VERSION ""

NS_ :

BS_:

BU_:

BO_ 2633663742 HVESP11HIST: 19 Vector__XXX
 SG_ Hvesp11StateOfHealth : 0|8@1+ (0.4,0) [0|100] "%" Vector__XXX
 SG_ Hvsp11CnttrOpnUndrLdCnt : 8|16@1+ (1,0) [0|64255] "count" Vector__XXX
 SG_ Hvesp11TotalEnergyThroughput : 24|32@1+ (100,0) [0|421108121500] "Watt-hour" Vector__XXX
 SG_ Hvesp11TotalAccumulatedCharge : 56|32@1+ (100,0) [0|421108121500] "Ah" Vector__XXX
 SG_ Hvesp11TotalLifetimeEnergyInput : 88|32@1+ (1,0) [0|4211081215] "kWh" Vector__XXX
 SG_ Hvsp11TtlLftmEnrgOtpt : 120|32@1+ (1,0) [0|4211081215] "kWh" Vector__XXX

BO_ 2566555134 HVESP11CFG: 19 Vector__XXX
 SG_ Hvesp11NominalVoltage : 0|16@1+ (0.05,0) [0|3212.75] "V" Vector__XXX
 SG_ Hvsp11RmmnddMnmmOprtngVltg : 16|16@1+ (0.05,0) [0|3212.75] "V" Vector__XXX
 SG_ Hvsp11RmmnddMxmmOprtngVltg : 32|16@1+ (0.05,0) [0|3212.75] "V" Vector__XXX
 SG_ Hvsp11RmmnddMnmmSttOfChrg : 48|16@1+ (0.0015625,0) [0|100.3984375] "%" Vector__XXX
 SG_ Hvsp11RmmnddMxmmSttOfChrg : 64|16@1+ (0.0015625,0) [0|100.3984375] "%" Vector__XXX
 SG_ Hvsp11RmmnddMxmmOprtngTmprtr : 80|16@1+ (0.03125,-273) [-273|1734.96875] "degC" Vector__XXX
 SG_ Hvsp11RmmnddMnmmOprtngTmprtr : 96|16@1+ (0.03125,-273) [-273|1734.96875] "degC" Vector__XXX
 SG_ Hvesp11CellMaximumVoltageLimit : 112|8@1+ (0.02044,0) [0|5.11] "V" Vector__XXX
 SG_ Hvesp11CellMinimumVoltageLimit : 120|8@1+ (0.02044,0) [0|5.11] "V" Vector__XXX
 SG_ Hvesp11NominalRatedCapacity : 128|24@1+ (0.001,0) [0|16449.535] "kWh" Vector__XXX

BO_ 2633664254 HVESP12HIST: 19 Vector__XXX
 SG_ Hvesp12StateOfHealth : 0|8@1+ (0.4,0) [0|100] "%" Vector__XXX
 SG_ Hvsp12CnttrOpnUndrLdCnt : 8|16@1+ (1,0) [0|64255] "count" Vector__XXX
 SG_ Hvesp12TotalEnergyThroughput : 24|32@1+ (100,0) [0|421108121500] "Watt-hour" Vector__XXX
 SG_ Hvesp12TotalAccumulatedCharge : 56|32@1+ (100,0) [0|421108121500] "Ah" Vector__XXX
 SG_ Hvesp12TotalLifetimeEnergyInput : 88|32@1+ (1,0) [0|4211081215] "kWh" Vector__XXX
 SG_ Hvsp12TtlLftmEnrgOtpt : 120|32@1+ (1,0) [0|4211081215] "kWh" Vector__XXX

BO_ 2566555646 HVESP12CFG: 19 Vector__XXX
 SG_ Hvesp12NominalVoltage : 0|16@1+ (0.05,0) [0|3212.75] "V" Vector__XXX
 SG_ Hvsp12RmmnddMnmmOprtngVltg : 16|16@1+ (0.05,0) [0|3212.75] "V" Vector__XXX
 SG_ Hvsp12RmmnddMxmmOprtngVltg : 32|16@1+ (0.05,0) [0|3212.75] "V" Vector__XXX
 SG_ Hvsp12RmmnddMnmmSttOfChrg : 48|16@1+ (0.0015625,0) [0|100.3984375] "%" Vector__XXX
 SG_ Hvsp12RmmnddMxmmSttOfChrg : 64|16@1+ (0.0015625,0) [0|100.3984375] "%" Vector__XXX
 SG_ Hvsp12RmmnddMxmmOprtngTmprtr : 80|16@1+ (0.03125,-273) [-273|1734.96875] "degC" Vector__XXX
 SG_ Hvsp12RmmnddMnmmOprtngTmprtr : 96|16@1+ (0.03125,-273) [-273|1734.96875] "degC" Vector__XXX
 SG_ Hvesp12CellMaximumVoltageLimit : 112|8@1+ (0.02044,0) [0|5.11] "V" Vector__XXX
 SG_ Hvesp12CellMinimumVoltageLimit : 120|8@1+ (0.02044,0) [0|5.11] "V" Vector__XXX
 SG_ Hvesp12NominalRatedCapacity : 128|24@1+ (0.001,0) [0|16449.535] "kWh" Vector__XXX

BO_ 2633664766 HVESP13HIST: 19 Vector__XXX
 SG_ Hvesp13StateOfHealth : 0|8@1+ (0.4,0) [0|100] "%" Vector__XXX
 SG_ Hvsp13CnttrOpnUndrLdCnt : 8|16@1+ (1,0) [0|64255] "count" Vector__XXX
 SG_ Hvesp13TotalEnergyThroughput : 24|32@1+ (100,0) [0|421108121500] "Watt-hour" Vector__XXX
 SG_ Hvesp13TotalAccumulatedCharge : 56|32@1+ (100,0) [0|421108121500] "Ah" Vector__XXX
 SG_ Hvesp13TotalLifetimeEnergyInput : 88|32@1+ (1,0) [0|4211081215] "kWh" Vector__XXX
 SG_ Hvsp13TtlLftmEnrgOtpt : 120|32@1+ (1,0) [0|4211081215] "kWh" Vector__XXX

BO_ 2566556158 HVESP13CFG: 19 Vector__XXX
 SG_ Hvesp13NominalVoltage : 0|16@1+ (0.05,0) [0|3212.75] "V" Vector__XXX
 SG_ Hvsp13RmmnddMnmmOprtngVltg : 16|16@1+ (0.05,0) [0|3212.75] "V" Vector__XXX
 SG_ Hvsp13RmmnddMxmmOprtngVltg : 32|16@1+ (0.05,0) [0|3212.75] "V" Vector__XXX
 SG_ Hvsp13RmmnddMnmmSttOfChrg : 48|16@1+ (0.0015625,0) [0|100.3984375] "%" Vector__XXX
 SG_ Hvsp13RmmnddMxmmSttOfChrg : 64|16@1+ (0.0015625,0) [0|100.3984375] "%" Vector__XXX
 SG_ Hvsp13RmmnddMxmmOprtngTmprtr : 80|16@1+ (0.03125,-273) [-273|1734.96875] "degC" Vector__XXX
 SG_ Hvsp13RmmnddMnmmOprtngTmprtr : 96|16@1+ (0.03125,-273) [-273|1734.96875] "degC" Vector__XXX
 SG_ Hvesp13CellMaximumVoltageLimit : 112|8@1+ (0.02044,0) [0|5.11] "V" Vector__XXX
 SG_ Hvesp13CellMinimumVoltageLimit : 120|8@1+ (0.02044,0) [0|5.11] "V" Vector__XXX
 SG_ Hvesp13NominalRatedCapacity : 128|24@1+ (0.001,0) [0|16449.535] "kWh" Vector__XXX

BO_ 2633665278 HVESP14HIST: 19 Vector__XXX
 SG_ Hvesp14StateOfHealth : 0|8@1+ (0.4,0) [0|100] "%" Vector__XXX
 SG_ Hvsp14CnttrOpnUndrLdCnt : 8|16@1+ (1,0) [0|64255] "count" Vector__XXX
 SG_ Hvesp14TotalEnergyThroughput : 24|32@1+ (100,0) [0|421108121500] "Watt-hour" Vector__XXX
 SG_ Hvesp14TotalAccumulatedCharge : 56|32@1+ (100,0) [0|421108121500] "Ah" Vector__XXX
 SG_ Hvesp14TotalLifetimeEnergyInput : 88|32@1+ (1,0) [0|4211081215] "kWh" Vector__XXX
 SG_ Hvsp14TtlLftmEnrgOtpt : 120|32@1+ (1,0) [0|4211081215] "kWh" Vector__XXX

BO_ 2566556670 HVESP14CFG: 19 Vector__XXX
 SG_ Hvesp14NominalVoltage : 0|16@1+ (0.05,0) [0|3212.75] "V" Vector__XXX
 SG_ Hvsp14RmmnddMnmmOprtngVltg : 16|16@1+ (0.05,0) [0|3212.75] "V" Vector__XXX
 SG_ Hvsp14RmmnddMxmmOprtngVltg : 32|16@1+ (0.05,0) [0|3212.75] "V" Vector__XXX
 SG_ Hvsp14RmmnddMnmmSttOfChrg : 48|16@1+ (0.0015625,0) [0|100.3984375] "%" Vector__XXX
 SG_ Hvsp14RmmnddMxmmSttOfChrg : 64|16@1+ (0.0015625,0) [0|100.3984375] "%" Vector__XXX
 SG_ Hvsp14RmmnddMxmmOprtngTmprtr : 80|16@1+ (0.03125,-273) [-273|1734.96875] "degC" Vector__XXX
 SG_ Hvsp14RmmnddMnmmOprtngTmprtr : 96|16@1+ (0.03125,-273) [-273|1734.96875] "degC" Vector__XXX
 SG_ Hvesp14CellMaximumVoltageLimit : 112|8@1+ (0.02044,0) [0|5.11] "V" Vector__XXX
 SG_ Hvesp14CellMinimumVoltageLimit : 120|8@1+ (0.02044,0) [0|5.11] "V" Vector__XXX
 SG_ Hvesp14NominalRatedCapacity : 128|24@1+ (0.001,0) [0|16449.535] "kWh" Vector__XXX

BO_ 2633665790 HVESP15HIST: 19 Vector__XXX
 SG_ Hvesp15StateOfHealth : 0|8@1+ (0.4,0) [0|100] "%" Vector__XXX
 SG_ Hvsp15CnttrOpnUndrLdCnt : 8|16@1+ (1,0) [0|64255] "count" Vector__XXX
 SG_ Hvesp15TotalEnergyThroughput : 24|32@1+ (100,0) [0|421108121500] "Watt-hour" Vector__XXX
 SG_ Hvesp15TotalAccumulatedCharge : 56|32@1+ (100,0) [0|421108121500] "Ah" Vector__XXX
 SG_ Hvesp15TotalLifetimeEnergyInput : 88|32@1+ (1,0) [0|4211081215] "kWh" Vector__XXX
 SG_ Hvsp15TtlLftmEnrgOtpt : 120|32@1+ (1,0) [0|4211081215] "kWh" Vector__XXX

BO_ 2566557182 HVESP15CFG: 19 Vector__XXX
 SG_ Hvesp15NominalVoltage : 0|16@1+ (0.05,0) [0|3212.75] "V" Vector__XXX
 SG_ Hvsp15RmmnddMnmmOprtngVltg : 16|16@1+ (0.05,0) [0|3212.75] "V" Vector__XXX
 SG_ Hvsp15RmmnddMxmmOprtngVltg : 32|16@1+ (0.05,0) [0|3212.75] "V" Vector__XXX
 SG_ Hvsp15RmmnddMnmmSttOfChrg : 48|16@1+ (0.0015625,0) [0|100.3984375] "%" Vector__XXX
 SG_ Hvsp15RmmnddMxmmSttOfChrg : 64|16@1+ (0.0015625,0) [0|100.3984375] "%" Vector__XXX
 SG_ Hvsp15RmmnddMxmmOprtngTmprtr : 80|16@1+ (0.03125,-273) [-273|1734.96875] "degC" Vector__XXX
 SG_ Hvsp15RmmnddMnmmOprtngTmprtr : 96|16@1+ (0.03125,-273) [-273|1734.96875] "degC" Vector__XXX
 SG_ Hvesp15CellMaximumVoltageLimit : 112|8@1+ (0.02044,0) [0|5.11] "V" Vector__XXX
 SG_ Hvesp15CellMinimumVoltageLimit : 120|8@1+ (0.02044,0) [0|5.11] "V" Vector__XXX
 SG_ Hvesp15NominalRatedCapacity : 128|24@1+ (0.001,0) [0|16449.535] "kWh" Vector__XXX

BO_ 2633666302 HVESP16HIST: 19 Vector__XXX
 SG_ Hvesp16StateOfHealth : 0|8@1+ (0.4,0) [0|100] "%" Vector__XXX
 SG_ Hvsp16CnttrOpnUndrLdCnt : 8|16@1+ (1,0) [0|64255] "count" Vector__XXX
 SG_ Hvesp16TotalEnergyThroughput : 24|32@1+ (100,0) [0|421108121500] "Watt-hour" Vector__XXX
 SG_ Hvesp16TotalAccumulatedCharge : 56|32@1+ (100,0) [0|421108121500] "Ah" Vector__XXX
 SG_ Hvesp16TotalLifetimeEnergyInput : 88|32@1+ (1,0) [0|4211081215] "kWh" Vector__XXX
 SG_ Hvsp16TtlLftmEnrgOtpt : 120|32@1+ (1,0) [0|4211081215] "kWh" Vector__XXX

BO_ 2566557694 HVESP16CFG: 19 Vector__XXX
 SG_ Hvesp16NominalVoltage : 0|16@1+ (0.05,0) [0|3212.75] "V" Vector__XXX
 SG_ Hvsp16RmmnddMnmmOprtngVltg : 16|16@1+ (0.05,0) [0|3212.75] "V" Vector__XXX
 SG_ Hvsp16RmmnddMxmmOprtngVltg : 32|16@1+ (0.05,0) [0|3212.75] "V" Vector__XXX
 SG_ Hvsp16RmmnddMnmmSttOfChrg : 48|16@1+ (0.0015625,0) [0|100.3984375] "%" Vector__XXX
 SG_ Hvsp16RmmnddMxmmSttOfChrg : 64|16@1+ (0.0015625,0) [0|100.3984375] "%" Vector__XXX
 SG_ Hvsp16RmmnddMxmmOprtngTmprtr : 80|16@1+ (0.03125,-273) [-273|1734.96875] "degC" Vector__XXX
 SG_ Hvsp16RmmnddMnmmOprtngTmprtr : 96|16@1+ (0.03125,-273) [-273|1734.96875] "degC" Vector__XXX
 SG_ Hvesp16CellMaximumVoltageLimit : 112|8@1+ (0.02044,0) [0|5.11] "V" Vector__XXX
 SG_ Hvesp16CellMinimumVoltageLimit : 120|8@1+ (0.02044,0) [0|5.11] "V" Vector__XXX
 SG_ Hvesp16NominalRatedCapacity : 128|24@1+ (0.001,0) [0|16449.535] "kWh" Vector__XXX

BO_ 2633666814 HVESP17HIST: 19 Vector__XXX
 SG_ Hvesp17StateOfHealth : 0|8@1+ (0.4,0) [0|100] "%" Vector__XXX
 SG_ Hvsp17CnttrOpnUndrLdCnt : 8|16@1+ (1,0) [0|64255] "count" Vector__XXX
 SG_ Hvesp17TotalEnergyThroughput : 24|32@1+ (100,0) [0|421108121500] "Watt-hour" Vector__XXX
 SG_ Hvesp17TotalAccumulatedCharge : 56|32@1+ (100,0) [0|421108121500] "Ah" Vector__XXX
 SG_ Hvesp17TotalLifetimeEnergyInput : 88|32@1+ (1,0) [0|4211081215] "kWh" Vector__XXX
 SG_ Hvsp17TtlLftmEnrgOtpt : 120|32@1+ (1,0) [0|4211081215] "kWh" Vector__XXX

BO_ 2566558206 HVESP17CFG: 19 Vector__XXX
 SG_ Hvesp17NominalVoltage : 0|16@1+ (0.05,0) [0|3212.75] "V" Vector__XXX
 SG_ Hvsp17RmmnddMnmmOprtngVltg : 16|16@1+ (0.05,0) [0|3212.75] "V" Vector__XXX
 SG_ Hvsp17RmmnddMxmmOprtngVltg : 32|16@1+ (0.05,0) [0|3212.75] "V" Vector__XXX
 SG_ Hvsp17RmmnddMnmmSttOfChrg : 48|16@1+ (0.0015625,0) [0|100.3984375] "%" Vector__XXX
 SG_ Hvsp17RmmnddMxmmSttOfChrg : 64|16@1+ (0.0015625,0) [0|100.3984375] "%" Vector__XXX
 SG_ Hvsp17RmmnddMxmmOprtngTmprtr : 80|16@1+ (0.03125,-273) [-273|1734.96875] "degC" Vector__XXX
 SG_ Hvsp17RmmnddMnmmOprtngTmprtr : 96|16@1+ (0.03125,-273) [-273|1734.96875] "degC" Vector__XXX
 SG_ Hvesp17CellMaximumVoltageLimit : 112|8@1+ (0.02044,0) [0|5.11] "V" Vector__XXX
 SG_ Hvesp17CellMinimumVoltageLimit : 120|8@1+ (0.02044,0) [0|5.11] "V" Vector__XXX
 SG_ Hvesp17NominalRatedCapacity : 128|24@1+ (0.001,0) [0|16449.535] "kWh" Vector__XXX

BO_ 2633667326 HVESP18HIST: 19 Vector__XXX
 SG_ Hvesp18StateOfHealth : 0|8@1+ (0.4,0) [0|100] "%" Vector__XXX
 SG_ Hvsp18CnttrOpnUndrLdCnt : 8|16@1+ (1,0) [0|64255] "count" Vector__XXX
 SG_ Hvesp18TotalEnergyThroughput : 24|32@1+ (100,0) [0|421108121500] "Watt-hour" Vector__XXX
 SG_ Hvesp18TotalAccumulatedCharge : 56|32@1+ (100,0) [0|421108121500] "Ah" Vector__XXX
 SG_ Hvesp18TotalLifetimeEnergyInput : 88|32@1+ (1,0) [0|4211081215] "kWh" Vector__XXX
 SG_ Hvsp18TtlLftmEnrgOtpt : 120|32@1+ (1,0) [0|4211081215] "kWh" Vector__XXX

BO_ 2566558718 HVESP18CFG: 19 Vector__XXX
 SG_ Hvesp18NominalVoltage : 0|16@1+ (0.05,0) [0|3212.75] "V" Vector__XXX
 SG_ Hvsp18RmmnddMnmmOprtngVltg : 16|16@1+ (0.05,0) [0|3212.75] "V" Vector__XXX
 SG_ Hvsp18RmmnddMxmmOprtngVltg : 32|16@1+ (0.05,0) [0|3212.75] "V" Vector__XXX
 SG_ Hvsp18RmmnddMnmmSttOfChrg : 48|16@1+ (0.0015625,0) [0|100.3984375] "%" Vector__XXX
 SG_ Hvsp18RmmnddMxmmSttOfChrg : 64|16@1+ (0.0015625,0) [0|100.3984375] "%" Vector__XXX
 SG_ Hvsp18RmmnddMxmmOprtngTmprtr : 80|16@1+ (0.03125,-273) [-273|1734.96875] "degC" Vector__XXX
 SG_ Hvsp18RmmnddMnmmOprtngTmprtr : 96|16@1+ (0.03125,-273) [-273|1734.96875] "degC" Vector__XXX
 SG_ Hvesp18CellMaximumVoltageLimit : 112|8@1+ (0.02044,0) [0|5.11] "V" Vector__XXX
 SG_ Hvesp18CellMinimumVoltageLimit : 120|8@1+ (0.02044,0) [0|5.11] "V" Vector__XXX
 SG_ Hvesp18NominalRatedCapacity : 128|24@1+ (0.001,0) [0|16449.535] "kWh" Vector__XXX

BO_ 2633667838 HVESP19HIST: 19 Vector__XXX
 SG_ Hvesp19StateOfHealth : 0|8@1+ (0.4,0) [0|100] "%" Vector__XXX
 SG_ Hvsp19CnttrOpnUndrLdCnt : 8|16@1+ (1,0) [0|64255] "count" Vector__XXX
 SG_ Hvesp19TotalEnergyThroughput : 24|32@1+ (100,0) [0|421108121500] "Watt-hour" Vector__XXX
 SG_ Hvesp19TotalAccumulatedCharge : 56|32@1+ (100,0) [0|421108121500] "Ah" Vector__XXX
 SG_ Hvesp19TotalLifetimeEnergyInput : 88|32@1+ (1,0) [0|4211081215] "kWh" Vector__XXX
 SG_ Hvsp19TtlLftmEnrgOtpt : 120|32@1+ (1,0) [0|4211081215] "kWh" Vector__XXX

BO_ 2566559230 HVESP19CFG: 19 Vector__XXX
 SG_ Hvesp19NominalVoltage : 0|16@1+ (0.05,0) [0|3212.75] "V" Vector__XXX
 SG_ Hvsp19RmmnddMnmmOprtngVltg : 16|16@1+ (0.05,0) [0|3212.75] "V" Vector__XXX
 SG_ Hvsp19RmmnddMxmmOprtngVltg : 32|16@1+ (0.05,0) [0|3212.75] "V" Vector__XXX
 SG_ Hvsp19RmmnddMnmmSttOfChrg : 48|16@1+ (0.0015625,0) [0|100.3984375] "%" Vector__XXX
 SG_ Hvsp19RmmnddMxmmSttOfChrg : 64|16@1+ (0.0015625,0) [0|100.3984375] "%" Vector__XXX
 SG_ Hvsp19RmmnddMxmmOprtngTmprtr : 80|16@1+ (0.03125,-273) [-273|1734.96875] "degC" Vector__XXX
 SG_ Hvsp19RmmnddMnmmOprtngTmprtr : 96|16@1+ (0.03125,-273) [-273|1734.96875] "degC" Vector__XXX
 SG_ Hvesp19CellMaximumVoltageLimit : 112|8@1+ (0.02044,0) [0|5.11] "V" Vector__XXX
 SG_ Hvesp19CellMinimumVoltageLimit : 120|8@1+ (0.02044,0) [0|5.11] "V" Vector__XXX
 SG_ Hvesp19NominalRatedCapacity : 128|24@1+ (0.001,0) [0|16449.535] "kWh" Vector__XXX

BO_ 2633668350 HVESP20HIST: 19 Vector__XXX
 SG_ Hvesp20StateOfHealth : 0|8@1+ (0.4,0) [0|100] "%" Vector__XXX
 SG_ Hvsp20CnttrOpnUndrLdCnt : 8|16@1+ (1,0) [0|64255] "count" Vector__XXX
 SG_ Hvesp20TotalEnergyThroughput : 24|32@1+ (100,0) [0|421108121500] "Watt-hour" Vector__XXX
 SG_ Hvesp20TotalAccumulatedCharge : 56|32@1+ (100,0) [0|421108121500] "Ah" Vector__XXX
 SG_ Hvesp20TotalLifetimeEnergyInput : 88|32@1+ (1,0) [0|4211081215] "kWh" Vector__XXX
 SG_ Hvsp20TtlLftmEnrgOtpt : 120|32@1+ (1,0) [0|4211081215] "kWh" Vector__XXX

BO_ 2566559742 HVESP20CFG: 19 Vector__XXX
 SG_ Hvesp20NominalVoltage : 0|16@1+ (0.05,0) [0|3212.75] "V" Vector__XXX
 SG_ Hvsp20RmmnddMnmmOprtngVltg : 16|16@1+ (0.05,0) [0|3212.75] "V" Vector__XXX
 SG_ Hvsp20RmmnddMxmmOprtngVltg : 32|16@1+ (0.05,0) [0|3212.75] "V" Vector__XXX
 SG_ Hvsp20RmmnddMnmmSttOfChrg : 48|16@1+ (0.0015625,0) [0|100.3984375] "%" Vector__XXX
 SG_ Hvsp20RmmnddMxmmSttOfChrg : 64|16@1+ (0.0015625,0) [0|100.3984375] "%" Vector__XXX
 SG_ Hvsp20RmmnddMxmmOprtngTmprtr : 80|16@1+ (0.03125,-273) [-273|1734.96875] "degC" Vector__XXX
 SG_ Hvsp20RmmnddMnmmOprtngTmprtr : 96|16@1+ (0.03125,-273) [-273|1734.96875] "degC" Vector__XXX
 SG_ Hvesp20CellMaximumVoltageLimit : 112|8@1+ (0.02044,0) [0|5.11] "V" Vector__XXX
 SG_ Hvesp20CellMinimumVoltageLimit : 120|8@1+ (0.02044,0) [0|5.11] "V" Vector__XXX
 SG_ Hvesp20NominalRatedCapacity : 128|24@1+ (0.001,0) [0|16449.535] "kWh" Vector__XXX

BO_ 2633668862 HVESP21HIST: 19 Vector__XXX
 SG_ Hvesp21StateOfHealth : 0|8@1+ (0.4,0) [0|100] "%" Vector__XXX
 SG_ Hvsp21CnttrOpnUndrLdCnt : 8|16@1+ (1,0) [0|64255] "count" Vector__XXX
 SG_ Hvesp21TotalEnergyThroughput : 24|32@1+ (100,0) [0|421108121500] "Watt-hour" Vector__XXX
 SG_ Hvesp21TotalAccumulatedCharge : 56|32@1+ (100,0) [0|421108121500] "Ah" Vector__XXX
 SG_ Hvesp21TotalLifetimeEnergyInput : 88|32@1+ (1,0) [0|4211081215] "kWh" Vector__XXX
 SG_ Hvsp21TtlLftmEnrgOtpt : 120|32@1+ (1,0) [0|4211081215] "kWh" Vector__XXX

BO_ 2566560254 HVESP21CFG: 19 Vector__XXX
 SG_ Hvesp21NominalVoltage : 0|16@1+ (0.05,0) [0|3212.75] "V" Vector__XXX
 SG_ Hvsp21RmmnddMnmmOprtngVltg : 16|16@1+ (0.05,0) [0|3212.75] "V" Vector__XXX
 SG_ Hvsp21RmmnddMxmmOprtngVltg : 32|16@1+ (0.05,0) [0|3212.75] "V" Vector__XXX
 SG_ Hvsp21RmmnddMnmmSttOfChrg : 48|16@1+ (0.0015625,0) [0|100.3984375] "%" Vector__XXX
 SG_ Hvsp21RmmnddMxmmSttOfChrg : 64|16@1+ (0.0015625,0) [0|100.3984375] "%" Vector__XXX
 SG_ Hvsp21RmmnddMxmmOprtngTmprtr : 80|16@1+ (0.03125,-273) [-273|1734.96875] "degC" Vector__XXX
 SG_ Hvsp21RmmnddMnmmOprtngTmprtr : 96|16@1+ (0.03125,-273) [-273|1734.96875] "degC" Vector__XXX
 SG_ Hvesp21CellMaximumVoltageLimit : 112|8@1+ (0.02044,0) [0|5.11] "V" Vector__XXX
 SG_ Hvesp21CellMinimumVoltageLimit : 120|8@1+ (0.02044,0) [0|5.11] "V" Vector__XXX
 SG_ Hvesp21NominalRatedCapacity : 128|24@1+ (0.001,0) [0|16449.535] "kWh" Vector__XXX

BO_ 2633669374 HVESP22HIST: 19 Vector__XXX
 SG_ Hvesp22StateOfHealth : 0|8@1+ (0.4,0) [0|100] "%" Vector__XXX
 SG_ Hvsp22CnttrOpnUndrLdCnt : 8|16@1+ (1,0) [0|64255] "count" Vector__XXX
 SG_ Hvesp22TotalEnergyThroughput : 24|32@1+ (100,0) [0|421108121500] "Watt-hour" Vector__XXX
 SG_ Hvesp22TotalAccumulatedCharge : 56|32@1+ (100,0) [0|421108121500] "Ah" Vector__XXX
 SG_ Hvesp22TotalLifetimeEnergyInput : 88|32@1+ (1,0) [0|4211081215] "kWh" Vector__XXX
 SG_ Hvsp22TtlLftmEnrgOtpt : 120|32@1+ (1,0) [0|4211081215] "kWh" Vector__XXX

BO_ 2566560766 HVESP22CFG: 19 Vector__XXX
 SG_ Hvesp22NominalVoltage : 0|16@1+ (0.05,0) [0|3212.75] "V" Vector__XXX
 SG_ Hvsp22RmmnddMnmmOprtngVltg : 16|16@1+ (0.05,0) [0|3212.75] "V" Vector__XXX
 SG_ Hvsp22RmmnddMxmmOprtngVltg : 32|16@1+ (0.05,0) [0|3212.75] "V" Vector__XXX
 SG_ Hvsp22RmmnddMnmmSttOfChrg : 48|16@1+ (0.0015625,0) [0|100.3984375] "%" Vector__XXX
 SG_ Hvsp22RmmnddMxmmSttOfChrg : 64|16@1+ (0.0015625,0) [0|100.3984375] "%" Vector__XXX
 SG_ Hvsp22RmmnddMxmmOprtngTmprtr : 80|16@1+ (0.03125,-273) [-273|1734.96875] "degC" Vector__XXX
 SG_ Hvsp22RmmnddMnmmOprtngTmprtr : 96|16@1+ (0.03125,-273) [-273|1734.96875] "degC" Vector__XXX
 SG_ Hvesp22CellMaximumVoltageLimit : 112|8@1+ (0.02044,0) [0|5.11] "V" Vector__XXX
 SG_ Hvesp22CellMinimumVoltageLimit : 120|8@1+ (0.02044,0) [0|5.11] "V" Vector__XXX
 SG_ Hvesp22NominalRatedCapacity : 128|24@1+ (0.001,0) [0|16449.535] "kWh" Vector__XXX

BO_ 2633669886 HVESP23HIST: 19 Vector__XXX
 SG_ Hvesp23StateOfHealth : 0|8@1+ (0.4,0) [0|100] "%" Vector__XXX
 SG_ Hvsp23CnttrOpnUndrLdCnt : 8|16@1+ (1,0) [0|64255] "count" Vector__XXX
 SG_ Hvesp23TotalEnergyThroughput : 24|32@1+ (100,0) [0|421108121500] "Watt-hour" Vector__XXX
 SG_ Hvesp23TotalAccumulatedCharge : 56|32@1+ (100,0) [0|421108121500] "Ah" Vector__XXX
 SG_ Hvesp23TotalLifetimeEnergyInput : 88|32@1+ (1,0) [0|4211081215] "kWh" Vector__XXX
 SG_ Hvsp23TtlLftmEnrgOtpt : 120|32@1+ (1,0) [0|4211081215] "kWh" Vector__XXX

BO_ 2566561278 HVESP23CFG: 19 Vector__XXX
 SG_ Hvesp23NominalVoltage : 0|16@1+ (0.05,0) [0|3212.75] "V" Vector__XXX
 SG_ Hvsp23RmmnddMnmmOprtngVltg : 16|16@1+ (0.05,0) [0|3212.75] "V" Vector__XXX
 SG_ Hvsp23RmmnddMxmmOprtngVltg : 32|16@1+ (0.05,0) [0|3212.75] "V" Vector__XXX
 SG_ Hvsp23RmmnddMnmmSttOfChrg : 48|16@1+ (0.0015625,0) [0|100.3984375] "%" Vector__XXX
 SG_ Hvsp23RmmnddMxmmSttOfChrg : 64|16@1+ (0.0015625,0) [0|100.3984375] "%" Vector__XXX
 SG_ Hvsp23RmmnddMxmmOprtngTmprtr : 80|16@1+ (0.03125,-273) [-273|1734.96875] "degC" Vector__XXX
 SG_ Hvsp23RmmnddMnmmOprtngTmprtr : 96|16@1+ (0.03125,-273) [-273|1734.96875] "degC" Vector__XXX
 SG_ Hvesp23CellMaximumVoltageLimit : 112|8@1+ (0.02044,0) [0|5.11] "V" Vector__XXX
 SG_ Hvesp23CellMinimumVoltageLimit : 120|8@1+ (0.02044,0) [0|5.11] "V" Vector__XXX
 SG_ Hvesp23NominalRatedCapacity : 128|24@1+ (0.001,0) [0|16449.535] "kWh" Vector__XXX

BO_ 2633670398 HVESP24HIST: 19 Vector__XXX
 SG_ Hvesp24StateOfHealth : 0|8@1+ (0.4,0) [0|100] "%" Vector__XXX
 SG_ Hvsp24CnttrOpnUndrLdCnt : 8|16@1+ (1,0) [0|64255] "count" Vector__XXX
 SG_ Hvesp24TotalEnergyThroughput : 24|32@1+ (100,0) [0|421108121500] "Watt-hour" Vector__XXX
 SG_ Hvesp24TotalAccumulatedCharge : 56|32@1+ (100,0) [0|421108121500] "Ah" Vector__XXX
 SG_ Hvesp24TotalLifetimeEnergyInput : 88|32@1+ (1,0) [0|4211081215] "kWh" Vector__XXX
 SG_ Hvsp24TtlLftmEnrgOtpt : 120|32@1+ (1,0) [0|4211081215] "kWh" Vector__XXX

BO_ 2566561790 HVESP24CFG: 19 Vector__XXX
 SG_ Hvesp24NominalVoltage : 0|16@1+ (0.05,0) [0|3212.75] "V" Vector__XXX
 SG_ Hvsp24RmmnddMnmmOprtngVltg : 16|16@1+ (0.05,0) [0|3212.75] "V" Vector__XXX
 SG_ Hvsp24RmmnddMxmmOprtngVltg : 32|16@1+ (0.05,0) [0|3212.75] "V" Vector__XXX
 SG_ Hvsp24RmmnddMnmmSttOfChrg : 48|16@1+ (0.0015625,0) [0|100.3984375] "%" Vector__XXX
 SG_ Hvsp24RmmnddMxmmSttOfChrg : 64|16@1+ (0.0015625,0) [0|100.3984375] "%" Vector__XXX
 SG_ Hvsp24RmmnddMxmmOprtngTmprtr : 80|16@1+ (0.03125,-273) [-273|1734.96875] "degC" Vector__XXX
 SG_ Hvsp24RmmnddMnmmOprtngTmprtr : 96|16@1+ (0.03125,-273) [-273|1734.96875] "degC" Vector__XXX
 SG_ Hvesp24CellMaximumVoltageLimit : 112|8@1+ (0.02044,0) [0|5.11] "V" Vector__XXX
 SG_ Hvesp24CellMinimumVoltageLimit : 120|8@1+ (0.02044,0) [0|5.11] "V" Vector__XXX
 SG_ Hvesp24NominalRatedCapacity : 128|24@1+ (0.001,0) [0|16449.535] "kWh" Vector__XXX

BO_ 2633670910 HVESP25HIST: 19 Vector__XXX
 SG_ Hvesp25StateOfHealth : 0|8@1+ (0.4,0) [0|100] "%" Vector__XXX
 SG_ Hvsp25CnttrOpnUndrLdCnt : 8|16@1+ (1,0) [0|64255] "count" Vector__XXX
 SG_ Hvesp25TotalEnergyThroughput : 24|32@1+ (100,0) [0|421108121500] "Watt-hour" Vector__XXX
 SG_ Hvesp25TotalAccumulatedCharge : 56|32@1+ (100,0) [0|421108121500] "Ah" Vector__XXX
 SG_ Hvesp25TotalLifetimeEnergyInput : 88|32@1+ (1,0) [0|4211081215] "kWh" Vector__XXX
 SG_ Hvsp25TtlLftmEnrgOtpt : 120|32@1+ (1,0) [0|4211081215] "kWh" Vector__XXX

BO_ 2566562302 HVESP25CFG: 19 Vector__XXX
 SG_ Hvesp25NominalVoltage : 0|16@1+ (0.05,0) [0|3212.75] "V" Vector__XXX
 SG_ Hvsp25RmmnddMnmmOprtngVltg : 16|16@1+ (0.05,0) [0|3212.75] "V" Vector__XXX
 SG_ Hvsp25RmmnddMxmmOprtngVltg : 32|16@1+ (0.05,0) [0|3212.75] "V" Vector__XXX
 SG_ Hvsp25RmmnddMnmmSttOfChrg : 48|16@1+ (0.0015625,0) [0|100.3984375] "%" Vector__XXX
 SG_ Hvsp25RmmnddMxmmSttOfChrg : 64|16@1+ (0.0015625,0) [0|100.3984375] "%" Vector__XXX
 SG_ Hvsp25RmmnddMxmmOprtngTmprtr : 80|16@1+ (0.03125,-273) [-273|1734.96875] "degC" Vector__XXX
 SG_ Hvsp25RmmnddMnmmOprtngTmprtr : 96|16@1+ (0.03125,-273) [-273|1734.96875] "degC" Vector__XXX
 SG_ Hvesp25CellMaximumVoltageLimit : 112|8@1+ (0.02044,0) [0|5.11] "V" Vector__XXX
 SG_ Hvesp25CellMinimumVoltageLimit : 120|8@1+ (0.02044,0) [0|5.11] "V" Vector__XXX
 SG_ Hvesp25NominalRatedCapacity : 128|24@1+ (0.001,0) [0|16449.535] "kWh" Vector__XXX

BO_ 2633671422 HVESP26HIST: 19 Vector__XXX
 SG_ Hvesp26StateOfHealth : 0|8@1+ (0.4,0) [0|100] "%" Vector__XXX
 SG_ Hvsp26CnttrOpnUndrLdCnt : 8|16@1+ (1,0) [0|64255] "count" Vector__XXX
 SG_ Hvesp26TotalEnergyThroughput : 24|32@1+ (100,0) [0|421108121500] "Watt-hour" Vector__XXX
 SG_ Hvesp26TotalAccumulatedCharge : 56|32@1+ (100,0) [0|421108121500] "Ah" Vector__XXX
 SG_ Hvesp26TotalLifetimeEnergyInput : 88|32@1+ (1,0) [0|4211081215] "kWh" Vector__XXX
 SG_ Hvsp26TtlLftmEnrgOtpt : 120|32@1+ (1,0) [0|4211081215] "kWh" Vector__XXX

BO_ 2566562814 HVESP26CFG: 19 Vector__XXX
 SG_ Hvesp26NominalVoltage : 0|16@1+ (0.05,0) [0|3212.75] "V" Vector__XXX
 SG_ Hvsp26RmmnddMnmmOprtngVltg : 16|16@1+ (0.05,0) [0|3212.75] "V" Vector__XXX
 SG_ Hvsp26RmmnddMxmmOprtngVltg : 32|16@1+ (0.05,0) [0|3212.75] "V" Vector__XXX
 SG_ Hvsp26RmmnddMnmmSttOfChrg : 48|16@1+ (0.0015625,0) [0|100.3984375] "%" Vector__XXX
 SG_ Hvsp26RmmnddMxmmSttOfChrg : 64|16@1+ (0.0015625,0) [0|100.3984375] "%" Vector__XXX
 SG_ Hvsp26RmmnddMxmmOprtngTmprtr : 80|16@1+ (0.03125,-273) [-273|1734.96875] "degC" Vector__XXX
 SG_ Hvsp26RmmnddMnmmOprtngTmprtr : 96|16@1+ (0.03125,-273) [-273|1734.96875] "degC" Vector__XXX
 SG_ Hvesp26CellMaximumVoltageLimit : 112|8@1+ (0.02044,0) [0|5.11] "V" Vector__XXX
 SG_ Hvesp26CellMinimumVoltageLimit : 120|8@1+ (0.02044,0) [0|5.11] "V" Vector__XXX
 SG_ Hvesp26NominalRatedCapacity : 128|24@1+ (0.001,0) [0|16449.535] "kWh" Vector__XXX

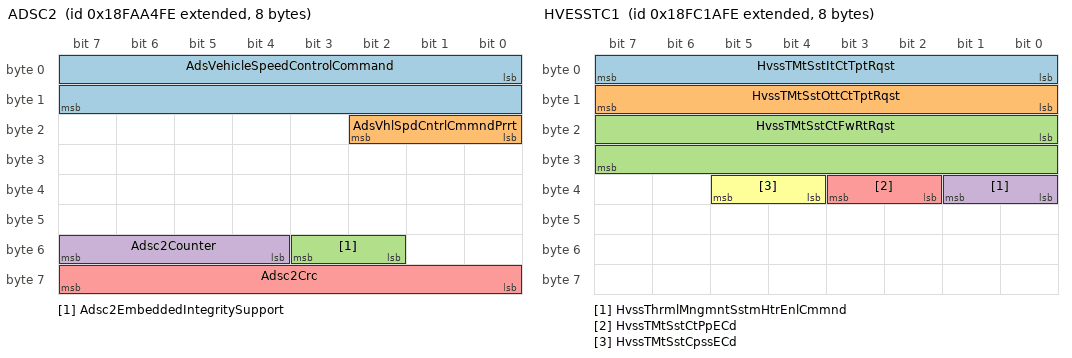
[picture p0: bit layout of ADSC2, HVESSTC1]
BO_ 2566563070 ADSC2: 8 Vector__XXX
 SG_ AdsVehicleSpeedControlCommand : 0|16@1+ (0.00390625,0) [0|250.99609375] "km/h" Vector__XXX
 SG_ AdsVhlSpdCntrlCmmndPrrt : 16|3@1+ (1,0) [0|7] "" Vector__XXX
 SG_ Adsc2EmbeddedIntegritySupport : 50|2@1+ (1,0) [0|3] "" Vector__XXX
 SG_ Adsc2Counter : 52|4@1+ (1,0) [0|15] "" Vector__XXX
 SG_ Adsc2Crc : 56|8@1+ (1,0) [0|250] "count" Vector__XXX

BO_ 2566658814 HVESSTC1: 8 Vector__XXX
 SG_ HvssTMtSstItCtTptRqst : 0|8@1+ (1,-40) [-40|210] "degC" Vector__XXX
 SG_ HvssTMtSstOttCtTptRqst : 8|8@1+ (1,-40) [-40|210] "degC" Vector__XXX
 SG_ HvssTMtSstCtFwRtRqst : 16|16@1+ (0.5,0) [0|32127.5] "l/min" Vector__XXX
 SG_ HvssThrmlMngmntSstmHtrEnlCmmnd : 32|2@1+ (1,0) [0|3] "" Vector__XXX
 SG_ HvssTMtSstCtPpECd : 34|2@1+ (1,0) [0|3] "" Vector__XXX
 SG_ HvssTMtSstCpssECd : 36|2@1+ (1,0) [0|3] "" Vector__XXX

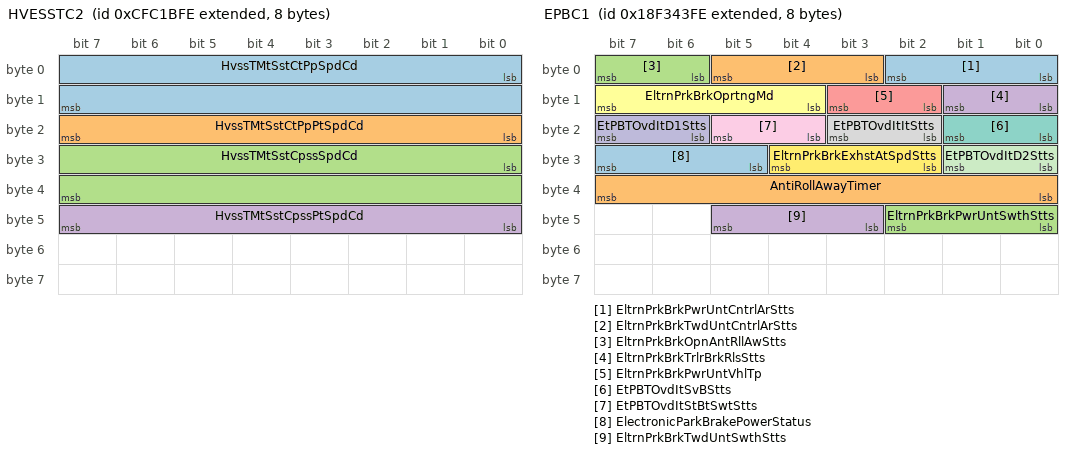
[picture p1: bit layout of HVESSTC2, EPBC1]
BO_ 2365332478 HVESSTC2: 8 Vector__XXX
 SG_ HvssTMtSstCtPpSpdCd : 0|16@1+ (0.5,0) [0|32127.5] "rpm" Vector__XXX
 SG_ HvssTMtSstCtPpPtSpdCd : 16|8@1+ (0.5,0) [0|100] "%" Vector__XXX
 SG_ HvssTMtSstCpssSpdCd : 24|16@1+ (0.5,0) [0|32127.5] "rpm" Vector__XXX
 SG_ HvssTMtSstCpssPtSpdCd : 40|8@1+ (0.5,0) [0|100] "%" Vector__XXX

BO_ 2566679038 EVOI1: 8 Vector__XXX
 SG_ HvessEstimatedRemainingDistance : 0|16@1+ (0.25,0) [0|16063.75] "km" Vector__XXX

BO_ 2566079486 EPBC1: 8 Vector__XXX
 SG_ EltrnPrkBrkPwrUntCntrlArStts : 0|3@1+ (1,0) [0|7] "" Vector__XXX
 SG_ EltrnPrkBrkTwdUntCntrlArStts : 3|3@1+ (1,0) [0|7] "" Vector__XXX
 SG_ EltrnPrkBrkOpnAntRllAwStts : 6|2@1+ (1,0) [0|3] "" Vector__XXX
 SG_ EltrnPrkBrkTrlrBrkRlsStts : 8|2@1+ (1,0) [0|3] "" Vector__XXX
 SG_ EltrnPrkBrkPwrUntVhlTp : 10|2@1+ (1,0) [0|3] "" Vector__XXX
 SG_ EltrnPrkBrkOprtngMd : 12|4@1+ (1,0) [0|15] "" Vector__XXX
 SG_ EtPBTOvdItSvBStts : 16|2@1+ (1,0) [0|3] "" Vector__XXX
 SG_ EtPBTOvdItItStts : 18|2@1+ (1,0) [0|3] "" Vector__XXX
 SG_ EtPBTOvdItStBtSwtStts : 20|2@1+ (1,0) [0|3] "" Vector__XXX
 SG_ EtPBTOvdItD1Stts : 22|2@1+ (1,0) [0|3] "" Vector__XXX
 SG_ EtPBTOvdItD2Stts : 24|2@1+ (1,0) [0|3] "" Vector__XXX
 SG_ EltrnPrkBrkExhstAtSpdStts : 26|3@1+ (1,0) [0|7] "" Vector__XXX
 SG_ ElectronicParkBrakePowerStatus : 29|3@1+ (1,0) [0|7] "" Vector__XXX
 SG_ AntiRollAwayTimer : 32|8@1+ (1,0) [0|240] "s" Vector__XXX
 SG_ EltrnPrkBrkPwrUntSwthStts : 40|3@1+ (1,0) [0|7] "" Vector__XXX
 SG_ EltrnPrkBrkTwdUntSwthStts : 43|3@1+ (1,0) [0|7] "" Vector__XXX

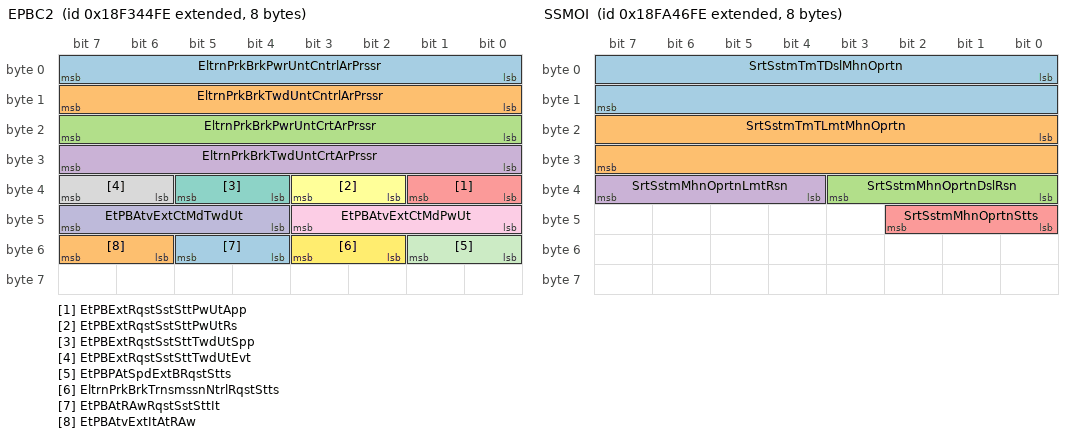
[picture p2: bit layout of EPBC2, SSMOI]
BO_ 2566079742 EPBC2: 8 Vector__XXX
 SG_ EltrnPrkBrkPwrUntCntrlArPrssr : 0|8@1+ (8,0) [0|2000] "kPa" Vector__XXX
 SG_ EltrnPrkBrkTwdUntCntrlArPrssr : 8|8@1+ (8,0) [0|2000] "kPa" Vector__XXX
 SG_ EltrnPrkBrkPwrUntCrtArPrssr : 16|8@1+ (8,0) [0|2000] "kPa" Vector__XXX
 SG_ EltrnPrkBrkTwdUntCrtArPrssr : 24|8@1+ (8,0) [0|2000] "kPa" Vector__XXX
 SG_ EtPBExtRqstSstSttPwUtApp : 32|2@1+ (1,0) [0|3] "" Vector__XXX
 SG_ EtPBExtRqstSstSttPwUtRs : 34|2@1+ (1,0) [0|3] "" Vector__XXX
 SG_ EtPBExtRqstSstSttTwdUtSpp : 36|2@1+ (1,0) [0|3] "" Vector__XXX
 SG_ EtPBExtRqstSstSttTwdUtEvt : 38|2@1+ (1,0) [0|3] "" Vector__XXX
 SG_ EtPBAtvExtCtMdPwUt : 40|4@1+ (1,0) [0|15] "" Vector__XXX
 SG_ EtPBAtvExtCtMdTwdUt : 44|4@1+ (1,0) [0|15] "" Vector__XXX
 SG_ EtPBPAtSpdExtBRqstStts : 48|2@1+ (1,0) [0|3] "" Vector__XXX
 SG_ EltrnPrkBrkTrnsmssnNtrlRqstStts : 50|2@1+ (1,0) [0|3] "" Vector__XXX
 SG_ EtPBAtRAwRqstSstSttIt : 52|2@1+ (1,0) [0|3] "" Vector__XXX
 SG_ EtPBAtvExtItAtRAw : 54|2@1+ (1,0) [0|3] "" Vector__XXX

BO_ 2566538494 LF2: 8 Vector__XXX
 SG_ TripAverageLoadFactor : 0|8@1+ (0.4,0) [0|100] "%" Vector__XXX
 SG_ TotalAverageLoadFactor : 8|8@1+ (0.4,0) [0|100] "%" Vector__XXX

BO_ 2365212158 GTRACE2: 8 Vector__XXX
 SG_ GeneratorTripKvarHoursImport : 0|32@1+ (1,0) [0|4211081215] "kVArh" Vector__XXX

BO_ 2566539006 SSMOI: 8 Vector__XXX
 SG_ SrtSstmTmTDslMhnOprtn : 0|16@1+ (1,0) [0|64255] "min" Vector__XXX
 SG_ SrtSstmTmTLmtMhnOprtn : 16|16@1+ (1,0) [0|64255] "min" Vector__XXX
 SG_ SrtSstmMhnOprtnDslRsn : 32|4@1+ (1,0) [0|15] "" Vector__XXX
 SG_ SrtSstmMhnOprtnLmtRsn : 36|4@1+ (1,0) [0|15] "" Vector__XXX
 SG_ SrtSstmMhnOprtnStts : 40|3@1+ (1,0) [0|7] "" Vector__XXX

BO_ 2566539262 EFASM: 8 Vector__XXX
 SG_ FuelActuator1ServiceModeRequest : 0|2@1+ (1,0) [0|3] "" Vector__XXX
 SG_ FuelActuator2ServiceModeRequest : 2|2@1+ (1,0) [0|3] "" Vector__XXX

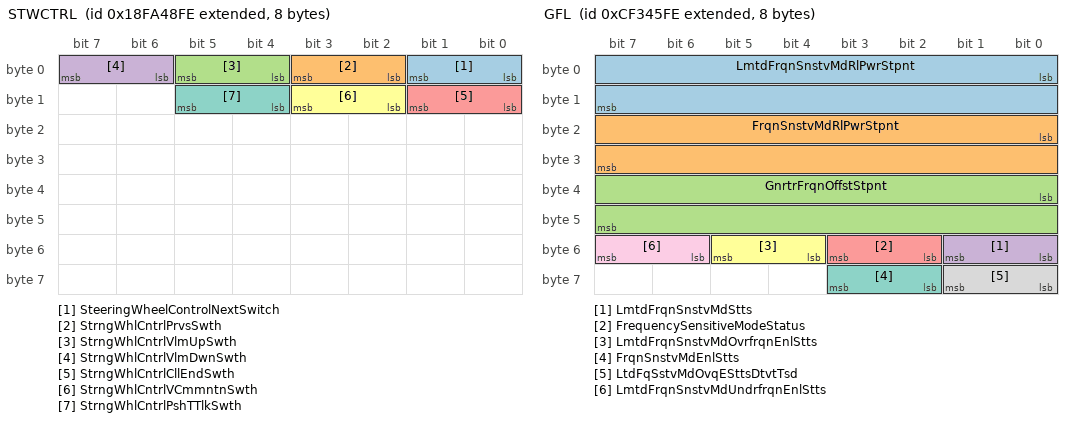
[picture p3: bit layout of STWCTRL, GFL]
BO_ 2566539518 STWCTRL: 8 Vector__XXX
 SG_ SteeringWheelControlNextSwitch : 0|2@1+ (1,0) [0|3] "" Vector__XXX
 SG_ StrngWhlCntrlPrvsSwth : 2|2@1+ (1,0) [0|3] "" Vector__XXX
 SG_ StrngWhlCntrlVlmUpSwth : 4|2@1+ (1,0) [0|3] "" Vector__XXX
 SG_ StrngWhlCntrlVlmDwnSwth : 6|2@1+ (1,0) [0|3] "" Vector__XXX
 SG_ StrngWhlCntrlCllEndSwth : 8|2@1+ (1,0) [0|3] "" Vector__XXX
 SG_ StrngWhlCntrlVCmmntnSwth : 10|2@1+ (1,0) [0|3] "" Vector__XXX
 SG_ StrngWhlCntrlPshTTlkSwth : 12|2@1+ (1,0) [0|3] "" Vector__XXX

BO_ 2566539774 PA: 8 Vector__XXX
 SG_ FrontParkAssistStatus : 0|3@1+ (1,0) [0|7] "" Vector__XXX
 SG_ RearParkAssistStatus : 3|3@1+ (1,0) [0|7] "" Vector__XXX

BO_ 2364753406 GFL: 8 Vector__XXX
 SG_ LmtdFrqnSnstvMdRlPwrStpnt : 0|16@1+ (0.01,-321.27) [-321.27|321.28] "%" Vector__XXX
 SG_ FrqnSnstvMdRlPwrStpnt : 16|16@1+ (0.01,-321.27) [-321.27|321.28] "%" Vector__XXX
 SG_ GnrtrFrqnOffstStpnt : 32|16@1+ (0.0078125,0) [0|501.9921875] "Hz" Vector__XXX
 SG_ LmtdFrqnSnstvMdStts : 48|2@1+ (1,0) [0|3] "" Vector__XXX
 SG_ FrequencySensitiveModeStatus : 50|2@1+ (1,0) [0|3] "" Vector__XXX
 SG_ LmtdFrqnSnstvMdOvrfrqnEnlStts : 52|2@1+ (1,0) [0|3] "" Vector__XXX
 SG_ FrqnSnstvMdEnlStts : 58|2@1+ (1,0) [0|3] "" Vector__XXX
 SG_ LtdFqSstvMdOvqESttsDtvtTsd : 56|2@1+ (1,0) [0|3] "" Vector__XXX
 SG_ LmtdFrqnSnstvMdUndrfrqnEnlStts : 54|2@1+ (1,0) [0|3] "" Vector__XXX

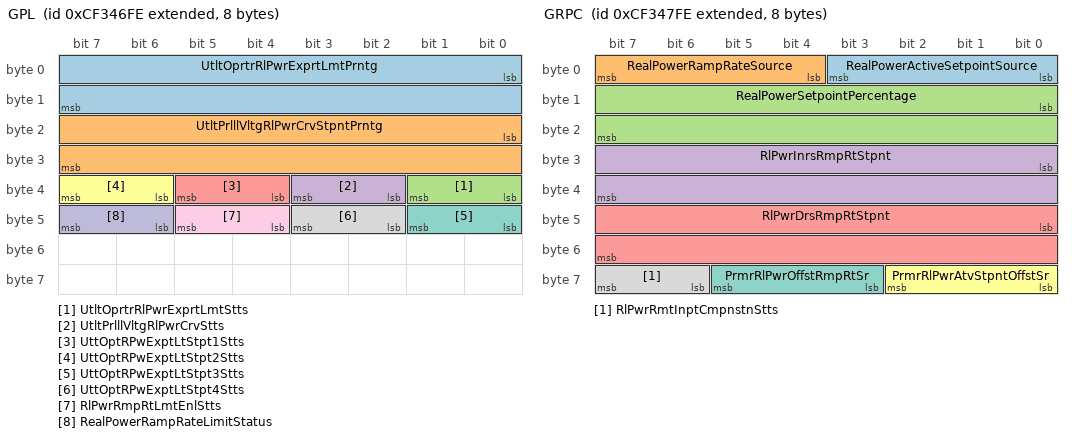
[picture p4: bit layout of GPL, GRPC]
BO_ 2364753662 GPL: 8 Vector__XXX
 SG_ UtltOprtrRlPwrExprtLmtPrntg : 0|16@1+ (0.01,-321.27) [-321.27|321.28] "%" Vector__XXX
 SG_ UtltPrlllVltgRlPwrCrvStpntPrntg : 16|16@1+ (0.01,-321.27) [-321.27|321.28] "%" Vector__XXX
 SG_ UtltOprtrRlPwrExprtLmtStts : 32|2@1+ (1,0) [0|3] "" Vector__XXX
 SG_ UtltPrlllVltgRlPwrCrvStts : 34|2@1+ (1,0) [0|3] "" Vector__XXX
 SG_ UttOptRPwExptLtStpt1Stts : 36|2@1+ (1,0) [0|3] "" Vector__XXX
 SG_ UttOptRPwExptLtStpt2Stts : 38|2@1+ (1,0) [0|3] "" Vector__XXX
 SG_ UttOptRPwExptLtStpt3Stts : 40|2@1+ (1,0) [0|3] "" Vector__XXX
 SG_ UttOptRPwExptLtStpt4Stts : 42|2@1+ (1,0) [0|3] "" Vector__XXX
 SG_ RlPwrRmpRtLmtEnlStts : 44|2@1+ (1,0) [0|3] "" Vector__XXX
 SG_ RealPowerRampRateLimitStatus : 46|2@1+ (1,0) [0|3] "" Vector__XXX

BO_ 2364753918 GRPC: 8 Vector__XXX
 SG_ RealPowerActiveSetpointSource : 0|4@1+ (1,0) [0|15] "" Vector__XXX
 SG_ RealPowerRampRateSource : 4|4@1+ (1,0) [0|15] "" Vector__XXX
 SG_ RealPowerSetpointPercentage : 8|16@1+ (0.01,-321.27) [-321.27|321.28] "%" Vector__XXX
 SG_ RlPwrInrsRmpRtStpnt : 24|16@1+ (0.01,0) [0|642.55] "%/s" Vector__XXX
 SG_ RlPwrDrsRmpRtStpnt : 40|16@1+ (0.01,0) [0|642.55] "%/s" Vector__XXX
 SG_ PrmrRlPwrAtvStpntOffstSr : 56|3@1+ (1,0) [0|7] "" Vector__XXX
 SG_ PrmrRlPwrOffstRmpRtSr : 59|3@1+ (1,0) [0|7] "" Vector__XXX
 SG_ RlPwrRmtInptCmpnstnStts : 62|2@1+ (1,0) [0|3] "" Vector__XXX

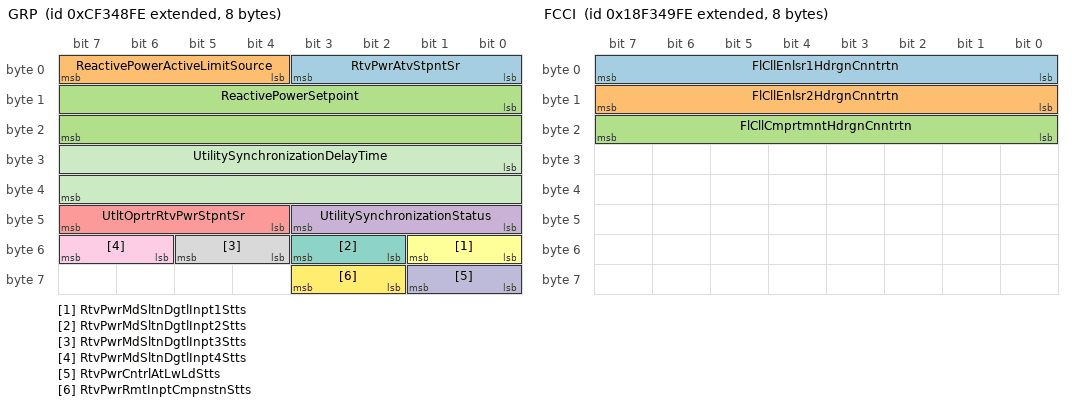
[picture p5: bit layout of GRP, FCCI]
BO_ 2364754174 GRP: 8 Vector__XXX
 SG_ RtvPwrAtvStpntSr : 0|4@1+ (1,0) [0|15] "" Vector__XXX
 SG_ ReactivePowerActiveLimitSource : 4|4@1+ (1,0) [0|15] "" Vector__XXX
 SG_ ReactivePowerSetpoint : 8|16@1+ (0.01,-321.27) [-321.27|321.28] "%" Vector__XXX
 SG_ UtilitySynchronizationStatus : 40|4@1+ (1,0) [0|15] "" Vector__XXX
 SG_ UtltOprtrRtvPwrStpntSr : 44|4@1+ (1,0) [0|15] "" Vector__XXX
 SG_ RtvPwrMdSltnDgtlInpt1Stts : 48|2@1+ (1,0) [0|3] "" Vector__XXX
 SG_ RtvPwrMdSltnDgtlInpt2Stts : 50|2@1+ (1,0) [0|3] "" Vector__XXX
 SG_ RtvPwrMdSltnDgtlInpt3Stts : 52|2@1+ (1,0) [0|3] "" Vector__XXX
 SG_ RtvPwrMdSltnDgtlInpt4Stts : 54|2@1+ (1,0) [0|3] "" Vector__XXX
 SG_ RtvPwrCntrlAtLwLdStts : 56|2@1+ (1,0) [0|3] "" Vector__XXX
 SG_ UtilitySynchronizationDelayTime : 24|16@1+ (1,0) [0|64255] "s" Vector__XXX
 SG_ RtvPwrRmtInptCmpnstnStts : 58|2@1+ (1,0) [0|3] "" Vector__XXX

BO_ 2566081022 FCCI: 8 Vector__XXX
 SG_ FlCllEnlsr1HdrgnCnntrtn : 0|8@1+ (500,0) [0|125000] "ppm" Vector__XXX
 SG_ FlCllEnlsr2HdrgnCnntrtn : 8|8@1+ (500,0) [0|125000] "ppm" Vector__XXX
 SG_ FlCllCmprtmntHdrgnCnntrtn : 16|8@1+ (500,0) [0|125000] "ppm" Vector__XXX

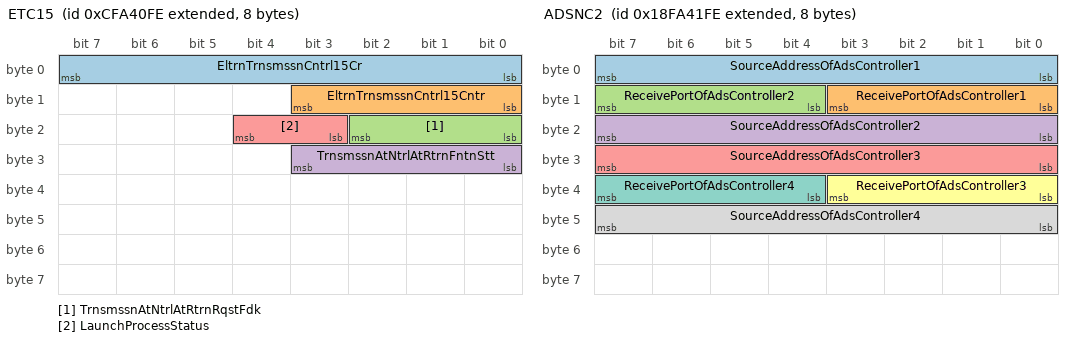
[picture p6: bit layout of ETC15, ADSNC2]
BO_ 2365210878 ETC15: 8 Vector__XXX
 SG_ EltrnTrnsmssnCntrl15Cr : 0|8@1+ (1,0) [0|250] "count" Vector__XXX
 SG_ EltrnTrnsmssnCntrl15Cntr : 8|4@1+ (1,0) [0|15] "count" Vector__XXX
 SG_ TrnsmssnAtNtrlAtRtrnRqstFdk : 16|3@1+ (1,0) [0|7] "" Vector__XXX
 SG_ TrnsmssnAtNtrlAtRtrnFntnStt : 24|4@1+ (1,0) [0|15] "" Vector__XXX
 SG_ LaunchProcessStatus : 19|2@1+ (1,0) [0|3] "" Vector__XXX

BO_ 2566537726 ADSNC2: 8 Vector__XXX
 SG_ SourceAddressOfAdsController1 : 0|8@1+ (1,0) [0|250] "sourceadr" Vector__XXX
 SG_ ReceivePortOfAdsController1 : 8|4@1+ (1,0) [0|15] "" Vector__XXX
 SG_ ReceivePortOfAdsController2 : 12|4@1+ (1,0) [0|15] "" Vector__XXX
 SG_ SourceAddressOfAdsController2 : 16|8@1+ (1,0) [0|250] "sourceadr" Vector__XXX
 SG_ SourceAddressOfAdsController3 : 24|8@1+ (1,0) [0|250] "sourceadr" Vector__XXX
 SG_ ReceivePortOfAdsController3 : 32|4@1+ (1,0) [0|15] "" Vector__XXX
 SG_ ReceivePortOfAdsController4 : 36|4@1+ (1,0) [0|15] "" Vector__XXX
 SG_ SourceAddressOfAdsController4 : 40|8@1+ (1,0) [0|250] "sourceadr" Vector__XXX

BO_ 2499429374 HSI2: 8 Vector__XXX
 SG_ HrdOrEvSstmTtlRgnrtvBrkngLvl : 16|8@1+ (0.4,0) [0|100] "%" Vector__XXX

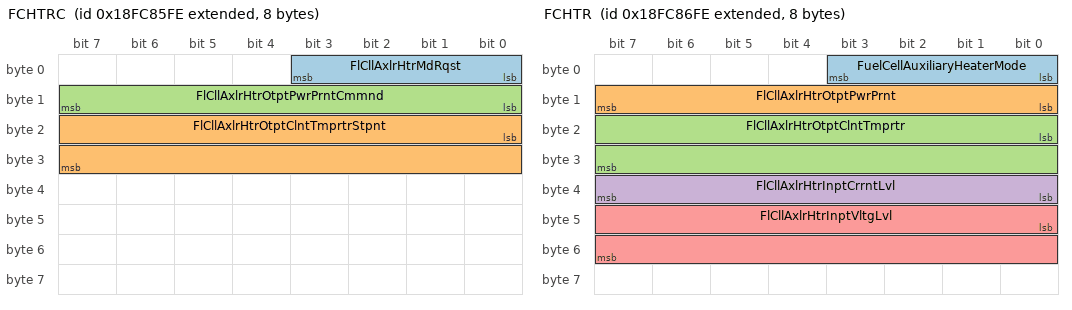
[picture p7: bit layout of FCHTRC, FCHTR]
BO_ 2566686206 FCHTRC: 8 Vector__XXX
 SG_ FlCllAxlrHtrMdRqst : 0|4@1+ (1,0) [0|15] "" Vector__XXX
 SG_ FlCllAxlrHtrOtptClntTmprtrStpnt : 16|16@1+ (0.0078125,-273) [-273|228.9921875] "degC" Vector__XXX
 SG_ FlCllAxlrHtrOtptPwrPrntCmmnd : 8|8@1+ (0.4,0) [0|100] "%" Vector__XXX

BO_ 2566686462 FCHTR: 8 Vector__XXX
 SG_ FuelCellAuxiliaryHeaterMode : 0|4@1+ (1,0) [0|15] "" Vector__XXX
 SG_ FlCllAxlrHtrOtptPwrPrnt : 8|8@1+ (0.4,0) [0|100] "%" Vector__XXX
 SG_ FlCllAxlrHtrOtptClntTmprtr : 16|16@1+ (0.0078125,-273) [-273|228.9921875] "degC" Vector__XXX
 SG_ FlCllAxlrHtrInptCrrntLvl : 32|8@1+ (0.25,0) [0|62.5] "A" Vector__XXX
 SG_ FlCllAxlrHtrInptVltgLvl : 40|16@1+ (1,0) [0|64255] "V" Vector__XXX

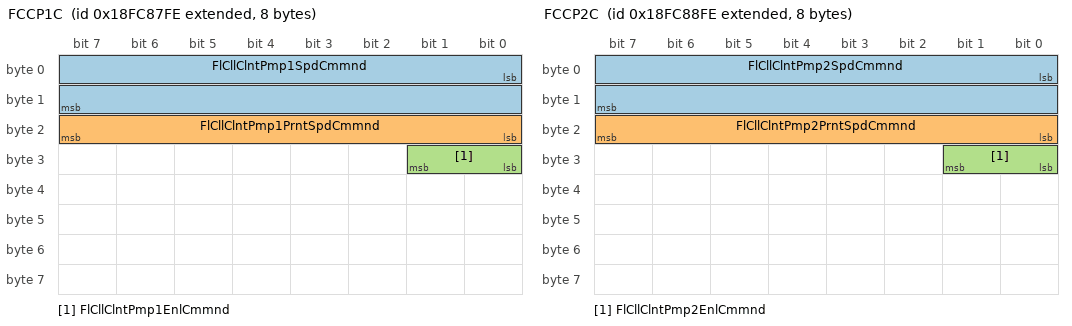
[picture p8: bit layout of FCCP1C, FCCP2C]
BO_ 2566686718 FCCP1C: 8 Vector__XXX
 SG_ FlCllClntPmp1SpdCmmnd : 0|16@1+ (0.5,0) [0|32127.5] "rpm" Vector__XXX
 SG_ FlCllClntPmp1PrntSpdCmmnd : 16|8@1+ (0.5,0) [0|125] "%" Vector__XXX
 SG_ FlCllClntPmp1EnlCmmnd : 24|2@1+ (1,0) [0|3] "" Vector__XXX

BO_ 2566686974 FCCP2C: 8 Vector__XXX
 SG_ FlCllClntPmp2SpdCmmnd : 0|16@1+ (0.5,0) [0|32127.5] "rpm" Vector__XXX
 SG_ FlCllClntPmp2PrntSpdCmmnd : 16|8@1+ (0.5,0) [0|125] "%" Vector__XXX
 SG_ FlCllClntPmp2EnlCmmnd : 24|2@1+ (1,0) [0|3] "" Vector__XXX

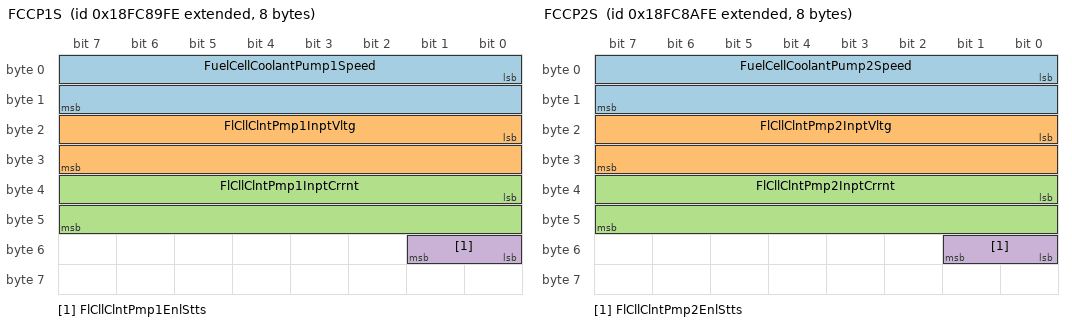
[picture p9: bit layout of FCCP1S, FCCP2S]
BO_ 2566687230 FCCP1S: 8 Vector__XXX
 SG_ FuelCellCoolantPump1Speed : 0|16@1+ (0.5,0) [0|32127.5] "rpm" Vector__XXX
 SG_ FlCllClntPmp1InptVltg : 16|16@1+ (1,0) [0|64255] "V" Vector__XXX
 SG_ FlCllClntPmp1InptCrrnt : 32|16@1+ (0.001,0) [0|64.255] "A" Vector__XXX
 SG_ FlCllClntPmp1EnlStts : 48|2@1+ (1,0) [0|3] "" Vector__XXX

BO_ 2566687486 FCCP2S: 8 Vector__XXX
 SG_ FuelCellCoolantPump2Speed : 0|16@1+ (0.5,0) [0|32127.5] "rpm" Vector__XXX
 SG_ FlCllClntPmp2InptVltg : 16|16@1+ (1,0) [0|64255] "V" Vector__XXX
 SG_ FlCllClntPmp2InptCrrnt : 32|16@1+ (0.001,0) [0|64.255] "A" Vector__XXX
 SG_ FlCllClntPmp2EnlStts : 48|2@1+ (1,0) [0|3] "" Vector__XXX

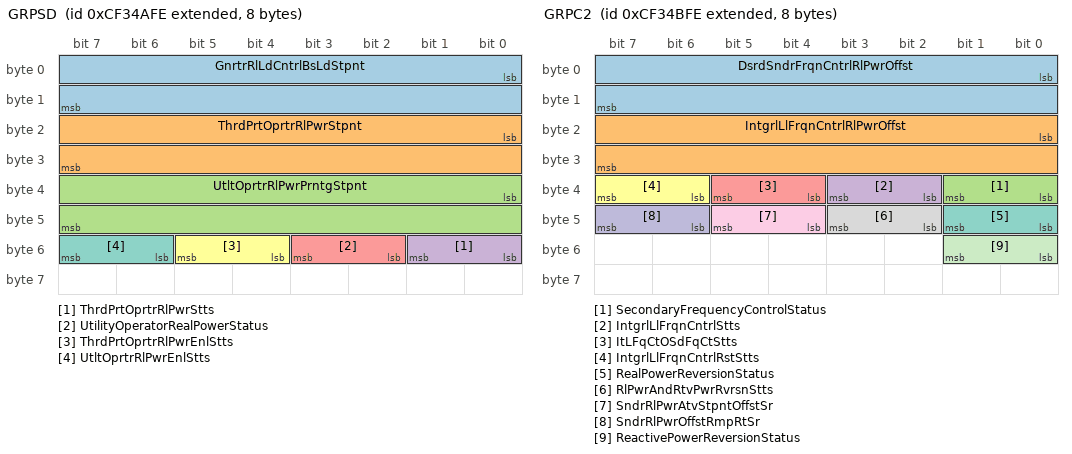
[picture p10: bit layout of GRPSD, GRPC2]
BO_ 2364754686 GRPSD: 8 Vector__XXX
 SG_ GnrtrRlLdCntrlBsLdStpnt : 0|16@1+ (0.01,-321.27) [-321.27|321.28] "%" Vector__XXX
 SG_ ThrdPrtOprtrRlPwrStpnt : 16|16@1+ (0.01,-321.27) [-321.27|321.28] "%" Vector__XXX
 SG_ UtltOprtrRlPwrPrntgStpnt : 32|16@1+ (0.01,-321.27) [-321.27|321.28] "%" Vector__XXX
 SG_ ThrdPrtOprtrRlPwrStts : 48|2@1+ (1,0) [0|3] "" Vector__XXX
 SG_ UtilityOperatorRealPowerStatus : 50|2@1+ (1,0) [0|3] "" Vector__XXX
 SG_ ThrdPrtOprtrRlPwrEnlStts : 52|2@1+ (1,0) [0|3] "" Vector__XXX
 SG_ UtltOprtrRlPwrEnlStts : 54|2@1+ (1,0) [0|3] "" Vector__XXX

BO_ 2364754942 GRPC2: 8 Vector__XXX
 SG_ DsrdSndrFrqnCntrlRlPwrOffst : 0|16@1+ (0.01,-321.27) [-321.27|321.28] "%" Vector__XXX
 SG_ IntgrlLlFrqnCntrlRlPwrOffst : 16|16@1+ (0.01,-321.27) [-321.27|321.28] "%" Vector__XXX
 SG_ SecondaryFrequencyControlStatus : 32|2@1+ (1,0) [0|3] "" Vector__XXX
 SG_ IntgrlLlFrqnCntrlStts : 34|2@1+ (1,0) [0|3] "" Vector__XXX
 SG_ ItLFqCtOSdFqCtStts : 36|2@1+ (1,0) [0|3] "" Vector__XXX
 SG_ IntgrlLlFrqnCntrlRstStts : 38|2@1+ (1,0) [0|3] "" Vector__XXX
 SG_ RealPowerReversionStatus : 40|2@1+ (1,0) [0|3] "" Vector__XXX
 SG_ RlPwrAndRtvPwrRvrsnStts : 42|2@1+ (1,0) [0|3] "" Vector__XXX
 SG_ SndrRlPwrAtvStpntOffstSr : 44|2@1+ (1,0) [0|3] "" Vector__XXX
 SG_ SndrRlPwrOffstRmpRtSr : 46|2@1+ (1,0) [0|3] "" Vector__XXX
 SG_ ReactivePowerReversionStatus : 48|2@1+ (1,0) [0|3] "" Vector__XXX

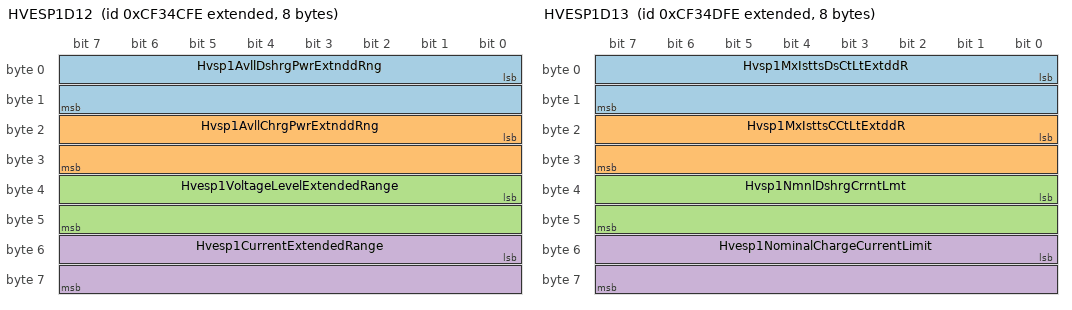
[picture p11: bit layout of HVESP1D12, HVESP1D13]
BO_ 2364755198 HVESP1D12: 8 Vector__XXX
 SG_ Hvsp1AvllDshrgPwrExtnddRng : 0|16@1+ (0.25,0) [0|16063.75] "kW" Vector__XXX
 SG_ Hvsp1AvllChrgPwrExtnddRng : 16|16@1+ (0.25,0) [0|16063.75] "kW" Vector__XXX
 SG_ Hvesp1VoltageLevelExtendedRange : 32|16@1+ (0.125,0) [0|8031.875] "V" Vector__XXX
 SG_ Hvesp1CurrentExtendedRange : 48|16@1+ (0.125,-4000) [-4000|4031.875] "A" Vector__XXX

BO_ 2364755454 HVESP1D13: 8 Vector__XXX
 SG_ Hvsp1MxIsttsDsCtLtExtddR : 0|16@1+ (0.125,-4000) [-4000|0] "A" Vector__XXX
 SG_ Hvsp1MxIsttsCCtLtExtddR : 16|16@1+ (0.125,-4000) [0|4031.875] "A" Vector__XXX
 SG_ Hvsp1NmnlDshrgCrrntLmt : 32|16@1+ (0.125,-4000) [-4000|0] "A" Vector__XXX
 SG_ Hvesp1NominalChargeCurrentLimit : 48|16@1+ (0.125,-4000) [0|4031.875] "A" Vector__XXX

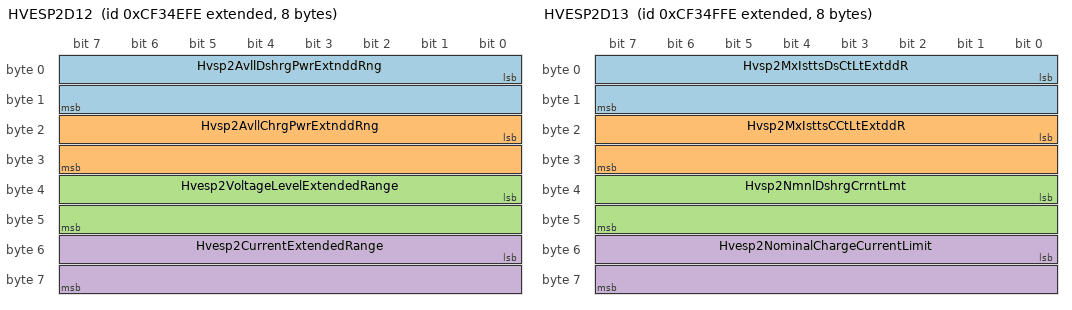
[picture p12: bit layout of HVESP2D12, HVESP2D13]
BO_ 2364755710 HVESP2D12: 8 Vector__XXX
 SG_ Hvsp2AvllDshrgPwrExtnddRng : 0|16@1+ (0.25,0) [0|16063.75] "kW" Vector__XXX
 SG_ Hvsp2AvllChrgPwrExtnddRng : 16|16@1+ (0.25,0) [0|16063.75] "kW" Vector__XXX
 SG_ Hvesp2VoltageLevelExtendedRange : 32|16@1+ (0.125,0) [0|8031.875] "V" Vector__XXX
 SG_ Hvesp2CurrentExtendedRange : 48|16@1+ (0.125,-4000) [-4000|4031.875] "A" Vector__XXX

BO_ 2364755966 HVESP2D13: 8 Vector__XXX
 SG_ Hvsp2MxIsttsDsCtLtExtddR : 0|16@1+ (0.125,-4000) [-4000|0] "A" Vector__XXX
 SG_ Hvsp2MxIsttsCCtLtExtddR : 16|16@1+ (0.125,-4000) [0|4031.875] "A" Vector__XXX
 SG_ Hvsp2NmnlDshrgCrrntLmt : 32|16@1+ (0.125,-4000) [-4000|0] "A" Vector__XXX
 SG_ Hvesp2NominalChargeCurrentLimit : 48|16@1+ (0.125,-4000) [0|4031.875] "A" Vector__XXX

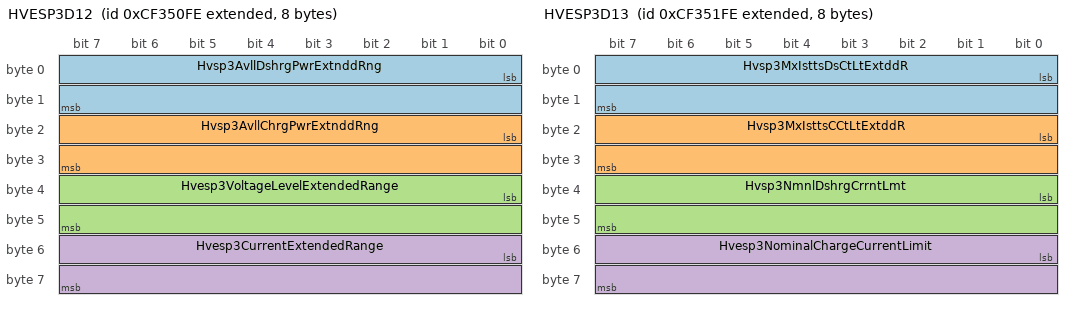
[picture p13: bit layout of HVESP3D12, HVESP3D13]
BO_ 2364756222 HVESP3D12: 8 Vector__XXX
 SG_ Hvsp3AvllDshrgPwrExtnddRng : 0|16@1+ (0.25,0) [0|16063.75] "kW" Vector__XXX
 SG_ Hvsp3AvllChrgPwrExtnddRng : 16|16@1+ (0.25,0) [0|16063.75] "kW" Vector__XXX
 SG_ Hvesp3VoltageLevelExtendedRange : 32|16@1+ (0.125,0) [0|8031.875] "V" Vector__XXX
 SG_ Hvesp3CurrentExtendedRange : 48|16@1+ (0.125,-4000) [-4000|4031.875] "A" Vector__XXX

BO_ 2364756478 HVESP3D13: 8 Vector__XXX
 SG_ Hvsp3MxIsttsDsCtLtExtddR : 0|16@1+ (0.125,-4000) [-4000|0] "A" Vector__XXX
 SG_ Hvsp3MxIsttsCCtLtExtddR : 16|16@1+ (0.125,-4000) [0|4031.875] "A" Vector__XXX
 SG_ Hvsp3NmnlDshrgCrrntLmt : 32|16@1+ (0.125,-4000) [-4000|0] "A" Vector__XXX
 SG_ Hvesp3NominalChargeCurrentLimit : 48|16@1+ (0.125,-4000) [0|4031.875] "A" Vector__XXX

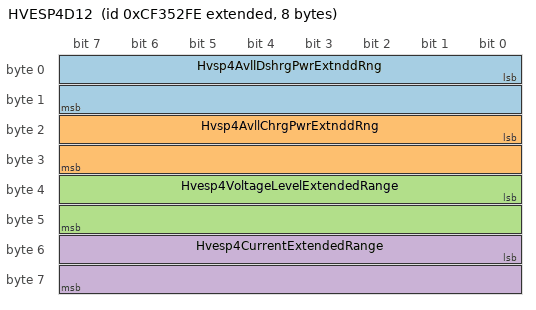
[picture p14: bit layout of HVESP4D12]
BO_ 2364756734 HVESP4D12: 8 Vector__XXX
 SG_ Hvsp4AvllDshrgPwrExtnddRng : 0|16@1+ (0.25,0) [0|16063.75] "kW" Vector__XXX
 SG_ Hvsp4AvllChrgPwrExtnddRng : 16|16@1+ (0.25,0) [0|16063.75] "kW" Vector__XXX
 SG_ Hvesp4VoltageLevelExtendedRange : 32|16@1+ (0.125,0) [0|8031.875] "V" Vector__XXX
 SG_ Hvesp4CurrentExtendedRange : 48|16@1+ (0.125,-4000) [-4000|4031.875] "A" Vector__XXX

CM_ BO_ 2633663742 "High Voltage Energy Storage Pack 11 History";
CM_ SG_ 2633663742 Hvesp11StateOfHealth "HVESP11 State of Health: This signal represents the expected remaining Life of this High Voltage Energy Storage Pack instance, in percent.  Battery life is a manufacturer-specific measure of how well the energy storage system is functioning relative ...";
CM_ SG_ 2633663742 Hvsp11CnttrOpnUndrLdCnt "HVESP11 Contactor Open Under Load Count: This signal represents the number of times the contactors inside this High Voltage Energy Storage Pack instance have opened while current is flowing through them.  The current level (that determines if an open...";
CM_ SG_ 2633663742 Hvesp11TotalEnergyThroughput "HVESP11 Total Energy Throughput: The total energy throughput which has flowed through this High Voltage Energy Storage Pack instance.  This parameter is the sum of the absolute values of the Energy into and out of this HVES instance.  This parameter ...";
CM_ SG_ 2633663742 Hvesp11TotalAccumulatedCharge "HVESP11 Total Accumulated Charge: The total accumulated amp hours which have flowed through this High Voltage Energy Storage Pack instance.  This parameter is the sum of the absolute values of the Ampere hours into and out of this HVES instance.  Thi...";
CM_ SG_ 2633663742 Hvesp11TotalLifetimeEnergyInput "HVESP11 Total Lifetime Energy Input: The cumulative energy which has flowed into this High Voltage Energy Storage Pack instance over the lifetime of the battery pack. This parameter is the sum of the Energy into this HVES instance. This value is rese...";
CM_ SG_ 2633663742 Hvsp11TtlLftmEnrgOtpt "HVESP11 Total Lifetime Energy Output: The cumulative energy which has flowed out of this High Voltage Energy Storage Pack instance over the lifetime of the battery pack. This parameter is the sum of the Energy out of this HVES instance. This value is...";
CM_ BO_ 2566555134 "High Voltage Energy Storage Pack 11 Configuration";
CM_ SG_ 2566555134 Hvesp11NominalVoltage "HVESP11 Nominal Voltage: Per the HVES manufacturer, this is the nominal operating voltage of this High Voltage Energy Storage Pack instance, e.g. '300V' or '600V'.This parameter is for one of multiple packs in an HVESS.  If there is only one pack in ...";
CM_ SG_ 2566555134 Hvsp11RmmnddMnmmOprtngVltg "HVESP11 Recommended Minimum Operating Voltage: Per the HVES manufacturer, this is the minimum recommended voltage level for this High Voltage Energy Storage Pack instance operation.  Operating below this value may compromise HVES life.This parameter ...";
CM_ SG_ 2566555134 Hvsp11RmmnddMxmmOprtngVltg "HVESP11 Recommended Maximum Operating Voltage: Per the HVES manufacturer, this is the maximum recommended voltage level for this High Voltage Energy Storage Pack instance operation.  Operating above this value may compromise HVES life.This parameter ...";
CM_ SG_ 2566555134 Hvsp11RmmnddMnmmSttOfChrg "HVESP11 Recommended Minimum State Of Charge: Per the HVES manufacturer, this is the recommended minimum state of charge for this High Voltage Energy Storage Pack instance operation.  Operating below this value may compromise HVES life.This parameter ...";
CM_ SG_ 2566555134 Hvsp11RmmnddMxmmSttOfChrg "HVESP11 Recommended Maximum State Of Charge: Per the HVES manufacturer, this is the recommended maximum state of charge for this High Voltage Energy Storage Pack instance operation.  Operating above this value may compromise HVES life.This parameter ...";
CM_ SG_ 2566555134 Hvsp11RmmnddMxmmOprtngTmprtr "HVESP11 Recommended Maximum Operating Temperature: Per the HVES manufacturer, this is the recommended maximum temperature for this High Voltage Energy Storage Pack instance operation.  Operating above this value may damage HVES hardware, or compromis...";
CM_ SG_ 2566555134 Hvsp11RmmnddMnmmOprtngTmprtr "HVESP11 Recommended Minimum Operating Temperature: Per the HVES manufacturer, this is the recommended minimum temperature for this High Voltage Energy Storage Pack instance operation.  Operating below this value may damage HVES hardware, or compromis...";
CM_ SG_ 2566555134 Hvesp11CellMaximumVoltageLimit "HVESP11 Cell Maximum Voltage Limit: Per the HVES manufacturer, this is the maximum cell voltage for this High Voltage Energy Storage Pack instance operation.  Operating above this value may damage HVES hardware, or compromise HVES life.This parameter...";
CM_ SG_ 2566555134 Hvesp11CellMinimumVoltageLimit "HVESP11 Cell Minimum Voltage Limit: Per the HVES manufacturer, this is the minimum cell voltage for this High Voltage Energy Storage Pack instance operation.  Operating below this value may damage HVES hardware, or compromise HVES life.This parameter...";
CM_ SG_ 2566555134 Hvesp11NominalRatedCapacity "HVESP11 Nominal Rated Capacity: Per the HVES manufacturer, this is the manufacturer's nominal rated capacity of this instance of the energy storage system.  The rated capacity does not change over the life of the HVES.This parameter is for one of mul...";
CM_ BO_ 2633664254 "High Voltage Energy Storage Pack 12 History";
CM_ SG_ 2633664254 Hvesp12StateOfHealth "HVESP12 State of Health: This signal represents the expected remaining Life of this High Voltage Energy Storage Pack instance, in percent.  Battery life is a manufacturer-specific measure of how well the energy storage system is functioning relative ...";
CM_ SG_ 2633664254 Hvsp12CnttrOpnUndrLdCnt "HVESP12 Contactor Open Under Load Count: This signal represents the number of times the contactors inside this High Voltage Energy Storage Pack instance have opened while current is flowing through them.  The current level (that determines if an open...";
CM_ SG_ 2633664254 Hvesp12TotalEnergyThroughput "HVESP12 Total Energy Throughput: The total energy throughput which has flowed through this High Voltage Energy Storage Pack instance.  This parameter is the sum of the absolute values of the Energy into and out of this HVES instance.  This parameter ...";
CM_ SG_ 2633664254 Hvesp12TotalAccumulatedCharge "HVESP12 Total Accumulated Charge: The total accumulated amp hours which have flowed through this High Voltage Energy Storage Pack instance.  This parameter is the sum of the absolute values of the Ampere hours into and out of this HVES instance.  Thi...";
CM_ SG_ 2633664254 Hvesp12TotalLifetimeEnergyInput "HVESP12 Total Lifetime Energy Input: The cumulative energy which has flowed into this High Voltage Energy Storage Pack instance over the lifetime of the battery pack. This parameter is the sum of the Energy into this HVES instance. This value is rese...";
CM_ SG_ 2633664254 Hvsp12TtlLftmEnrgOtpt "HVESP12 Total Lifetime Energy Output: The cumulative energy which has flowed out of this High Voltage Energy Storage Pack instance over the lifetime of the battery pack. This parameter is the sum of the Energy out of this HVES instance. This value is...";
CM_ BO_ 2566555646 "High Voltage Energy Storage Pack 12 Configuration";
CM_ SG_ 2566555646 Hvesp12NominalVoltage "HVESP12 Nominal Voltage: Per the HVES manufacturer, this is the nominal operating voltage of this High Voltage Energy Storage Pack instance, e.g. '300V' or '600V'.This parameter is for one of multiple packs in an HVESS.  If there is only one pack in ...";
CM_ SG_ 2566555646 Hvsp12RmmnddMnmmOprtngVltg "HVESP12 Recommended Minimum Operating Voltage: Per the HVES manufacturer, this is the minimum recommended voltage level for this High Voltage Energy Storage Pack instance operation.  Operating below this value may compromise HVES life.This parameter ...";
CM_ SG_ 2566555646 Hvsp12RmmnddMxmmOprtngVltg "HVESP12 Recommended Maximum Operating Voltage: Per the HVES manufacturer, this is the maximum recommended voltage level for this High Voltage Energy Storage Pack instance operation.  Operating above this value may compromise HVES life.This parameter ...";
CM_ SG_ 2566555646 Hvsp12RmmnddMnmmSttOfChrg "HVESP12 Recommended Minimum State Of Charge: Per the HVES manufacturer, this is the recommended minimum state of charge for this High Voltage Energy Storage Pack instance operation.  Operating below this value may compromise HVES life.This parameter ...";
CM_ SG_ 2566555646 Hvsp12RmmnddMxmmSttOfChrg "HVESP12 Recommended Maximum State Of Charge: Per the HVES manufacturer, this is the recommended maximum state of charge for this High Voltage Energy Storage Pack instance operation.  Operating above this value may compromise HVES life.This parameter ...";
CM_ SG_ 2566555646 Hvsp12RmmnddMxmmOprtngTmprtr "HVESP12 Recommended Maximum Operating Temperature: Per the HVES manufacturer, this is the recommended maximum temperature for this High Voltage Energy Storage Pack instance operation.  Operating above this value may damage HVES hardware, or compromis...";
CM_ SG_ 2566555646 Hvsp12RmmnddMnmmOprtngTmprtr "HVESP12 Recommended Minimum Operating Temperature: Per the HVES manufacturer, this is the recommended minimum temperature for this High Voltage Energy Storage Pack instance operation.  Operating below this value may damage HVES hardware, or compromis...";
CM_ SG_ 2566555646 Hvesp12CellMaximumVoltageLimit "HVESP12 Cell Maximum Voltage Limit: Per the HVES manufacturer, this is the maximum cell voltage for this High Voltage Energy Storage Pack instance operation.  Operating above this value may damage HVES hardware, or compromise HVES life.This parameter...";
CM_ SG_ 2566555646 Hvesp12CellMinimumVoltageLimit "HVESP12 Cell Minimum Voltage Limit: Per the HVES manufacturer, this is the minimum cell voltage for this High Voltage Energy Storage Pack instance operation.  Operating below this value may damage HVES hardware, or compromise HVES life.This parameter...";
CM_ SG_ 2566555646 Hvesp12NominalRatedCapacity "HVESP12 Nominal Rated Capacity: Per the HVES manufacturer, this is the manufacturer's nominal rated capacity of this instance of the energy storage system.  The rated capacity does not change over the life of the HVES.This parameter is for one of mul...";
CM_ BO_ 2633664766 "High Voltage Energy Storage Pack 13 History";
CM_ SG_ 2633664766 Hvesp13StateOfHealth "HVESP13 State of Health: This signal represents the expected remaining Life of this High Voltage Energy Storage Pack instance, in percent.  Battery life is a manufacturer-specific measure of how well the energy storage system is functioning relative ...";
CM_ SG_ 2633664766 Hvsp13CnttrOpnUndrLdCnt "HVESP13 Contactor Open Under Load Count: This signal represents the number of times the contactors inside this High Voltage Energy Storage Pack instance have opened while current is flowing through them.  The current level (that determines if an open...";
CM_ SG_ 2633664766 Hvesp13TotalEnergyThroughput "HVESP13 Total Energy Throughput: The total energy throughput which has flowed through this High Voltage Energy Storage Pack instance.  This parameter is the sum of the absolute values of the Energy into and out of this HVES instance.  This parameter ...";
CM_ SG_ 2633664766 Hvesp13TotalAccumulatedCharge "HVESP13 Total Accumulated Charge: The total accumulated amp hours which have flowed through this High Voltage Energy Storage Pack instance.  This parameter is the sum of the absolute values of the Ampere hours into and out of this HVES instance.  Thi...";
CM_ SG_ 2633664766 Hvesp13TotalLifetimeEnergyInput "HVESP13 Total Lifetime Energy Input: The cumulative energy which has flowed into this High Voltage Energy Storage Pack instance over the lifetime of the battery pack. This parameter is the sum of the Energy into this HVES instance. This value is rese...";
CM_ SG_ 2633664766 Hvsp13TtlLftmEnrgOtpt "HVESP13 Total Lifetime Energy Output: The cumulative energy which has flowed out of this High Voltage Energy Storage Pack instance over the lifetime of the battery pack. This parameter is the sum of the Energy out of this HVES instance. This value is...";
CM_ BO_ 2566556158 "High Voltage Energy Storage Pack 13 Configuration";
CM_ SG_ 2566556158 Hvesp13NominalVoltage "HVESP13 Nominal Voltage: Per the HVES manufacturer, this is the nominal operating voltage of this High Voltage Energy Storage Pack instance, e.g. '300V' or '600V'.This parameter is for one of multiple packs in an HVESS.  If there is only one pack in ...";
CM_ SG_ 2566556158 Hvsp13RmmnddMnmmOprtngVltg "HVESP13 Recommended Minimum Operating Voltage: Per the HVES manufacturer, this is the minimum recommended voltage level for this High Voltage Energy Storage Pack instance operation.  Operating below this value may compromise HVES life.This parameter ...";
CM_ SG_ 2566556158 Hvsp13RmmnddMxmmOprtngVltg "HVESP13 Recommended Maximum Operating Voltage: Per the HVES manufacturer, this is the maximum recommended voltage level for this High Voltage Energy Storage Pack instance operation.  Operating above this value may compromise HVES life.This parameter ...";
CM_ SG_ 2566556158 Hvsp13RmmnddMnmmSttOfChrg "HVESP13 Recommended Minimum State Of Charge: Per the HVES manufacturer, this is the recommended minimum state of charge for this High Voltage Energy Storage Pack instance operation.  Operating below this value may compromise HVES life.This parameter ...";
CM_ SG_ 2566556158 Hvsp13RmmnddMxmmSttOfChrg "HVESP13 Recommended Maximum State Of Charge: Per the HVES manufacturer, this is the recommended maximum state of charge for this High Voltage Energy Storage Pack instance operation.  Operating above this value may compromise HVES life.This parameter ...";
CM_ SG_ 2566556158 Hvsp13RmmnddMxmmOprtngTmprtr "HVESP13 Recommended Maximum Operating Temperature: Per the HVES manufacturer, this is the recommended maximum temperature for this High Voltage Energy Storage Pack instance operation.  Operating above this value may damage HVES hardware, or compromis...";
CM_ SG_ 2566556158 Hvsp13RmmnddMnmmOprtngTmprtr "HVESP13 Recommended Minimum Operating Temperature: Per the HVES manufacturer, this is the recommended minimum temperature for this High Voltage Energy Storage Pack instance operation.  Operating below this value may damage HVES hardware, or compromis...";
CM_ SG_ 2566556158 Hvesp13CellMaximumVoltageLimit "HVESP13 Cell Maximum Voltage Limit: Per the HVES manufacturer, this is the maximum cell voltage for this High Voltage Energy Storage Pack instance operation.  Operating above this value may damage HVES hardware, or compromise HVES life.This parameter...";
CM_ SG_ 2566556158 Hvesp13CellMinimumVoltageLimit "HVESP13 Cell Minimum Voltage Limit: Per the HVES manufacturer, this is the minimum cell voltage for this High Voltage Energy Storage Pack instance operation.  Operating below this value may damage HVES hardware, or compromise HVES life.This parameter...";
CM_ SG_ 2566556158 Hvesp13NominalRatedCapacity "HVESP13 Nominal Rated Capacity: Per the HVES manufacturer, this is the manufacturer's nominal rated capacity of this instance of the energy storage system.  The rated capacity does not change over the life of the HVES.This parameter is for one of mul...";
CM_ BO_ 2633665278 "High Voltage Energy Storage Pack 14 History";
CM_ SG_ 2633665278 Hvesp14StateOfHealth "HVESP14 State of Health: This signal represents the expected remaining Life of this High Voltage Energy Storage Pack instance, in percent.  Battery life is a manufacturer-specific measure of how well the energy storage system is functioning relative ...";
CM_ SG_ 2633665278 Hvsp14CnttrOpnUndrLdCnt "HVESP14 Contactor Open Under Load Count: This signal represents the number of times the contactors inside this High Voltage Energy Storage Pack instance have opened while current is flowing through them.  The current level (that determines if an open...";
CM_ SG_ 2633665278 Hvesp14TotalEnergyThroughput "HVESP14 Total Energy Throughput: The total energy throughput which has flowed through this High Voltage Energy Storage Pack instance.  This parameter is the sum of the absolute values of the Energy into and out of this HVES instance.  This parameter ...";
CM_ SG_ 2633665278 Hvesp14TotalAccumulatedCharge "HVESP14 Total Accumulated Charge: The total accumulated amp hours which have flowed through this High Voltage Energy Storage Pack instance.  This parameter is the sum of the absolute values of the Ampere hours into and out of this HVES instance.  Thi...";
CM_ SG_ 2633665278 Hvesp14TotalLifetimeEnergyInput "HVESP14 Total Lifetime Energy Input: The cumulative energy which has flowed into this High Voltage Energy Storage Pack instance over the lifetime of the battery pack. This parameter is the sum of the Energy into this HVES instance. This value is rese...";
CM_ SG_ 2633665278 Hvsp14TtlLftmEnrgOtpt "HVESP14 Total Lifetime Energy Output: The cumulative energy which has flowed out of this High Voltage Energy Storage Pack instance over the lifetime of the battery pack. This parameter is the sum of the Energy out of this HVES instance. This value is...";
CM_ BO_ 2566556670 "High Voltage Energy Storage Pack 14 Configuration";
CM_ SG_ 2566556670 Hvesp14NominalVoltage "HVESP14 Nominal Voltage: Per the HVES manufacturer, this is the nominal operating voltage of this High Voltage Energy Storage Pack instance, e.g. '300V' or '600V'.This parameter is for one of multiple packs in an HVESS.  If there is only one pack in ...";
CM_ SG_ 2566556670 Hvsp14RmmnddMnmmOprtngVltg "HVESP14 Recommended Minimum Operating Voltage: Per the HVES manufacturer, this is the minimum recommended voltage level for this High Voltage Energy Storage Pack instance operation.  Operating below this value may compromise HVES life.This parameter ...";
CM_ SG_ 2566556670 Hvsp14RmmnddMxmmOprtngVltg "HVESP14 Recommended Maximum Operating Voltage: Per the HVES manufacturer, this is the maximum recommended voltage level for this High Voltage Energy Storage Pack instance operation.  Operating above this value may compromise HVES life.This parameter ...";
CM_ SG_ 2566556670 Hvsp14RmmnddMnmmSttOfChrg "HVESP14 Recommended Minimum State Of Charge: Per the HVES manufacturer, this is the recommended minimum state of charge for this High Voltage Energy Storage Pack instance operation.  Operating below this value may compromise HVES life.This parameter ...";
CM_ SG_ 2566556670 Hvsp14RmmnddMxmmSttOfChrg "HVESP14 Recommended Maximum State Of Charge: Per the HVES manufacturer, this is the recommended maximum state of charge for this High Voltage Energy Storage Pack instance operation.  Operating above this value may compromise HVES life.This parameter ...";
CM_ SG_ 2566556670 Hvsp14RmmnddMxmmOprtngTmprtr "HVESP14 Recommended Maximum Operating Temperature: Per the HVES manufacturer, this is the recommended maximum temperature for this High Voltage Energy Storage Pack instance operation.  Operating above this value may damage HVES hardware, or compromis...";
CM_ SG_ 2566556670 Hvsp14RmmnddMnmmOprtngTmprtr "HVESP14 Recommended Minimum Operating Temperature: Per the HVES manufacturer, this is the recommended minimum temperature for this High Voltage Energy Storage Pack instance operation.  Operating below this value may damage HVES hardware, or compromis...";
CM_ SG_ 2566556670 Hvesp14CellMaximumVoltageLimit "HVESP14 Cell Maximum Voltage Limit: Per the HVES manufacturer, this is the maximum cell voltage for this High Voltage Energy Storage Pack instance operation.  Operating above this value may damage HVES hardware, or compromise HVES life.This parameter...";
CM_ SG_ 2566556670 Hvesp14CellMinimumVoltageLimit "HVESP14 Cell Minimum Voltage Limit: Per the HVES manufacturer, this is the minimum cell voltage for this High Voltage Energy Storage Pack instance operation.  Operating below this value may damage HVES hardware, or compromise HVES life.This parameter...";
CM_ SG_ 2566556670 Hvesp14NominalRatedCapacity "HVESP14 Nominal Rated Capacity: Per the HVES manufacturer, this is the manufacturer's nominal rated capacity of this instance of the energy storage system.  The rated capacity does not change over the life of the HVES.This parameter is for one of mul...";
CM_ BO_ 2633665790 "High Voltage Energy Storage Pack 15 History";
CM_ SG_ 2633665790 Hvesp15StateOfHealth "HVESP15 State of Health: This signal represents the expected remaining Life of this High Voltage Energy Storage Pack instance, in percent.  Battery life is a manufacturer-specific measure of how well the energy storage system is functioning relative ...";
CM_ SG_ 2633665790 Hvsp15CnttrOpnUndrLdCnt "HVESP15 Contactor Open Under Load Count: This signal represents the number of times the contactors inside this High Voltage Energy Storage Pack instance have opened while current is flowing through them.  The current level (that determines if an open...";
CM_ SG_ 2633665790 Hvesp15TotalEnergyThroughput "HVESP15 Total Energy Throughput: The total energy throughput which has flowed through this High Voltage Energy Storage Pack instance.  This parameter is the sum of the absolute values of the Energy into and out of this HVES instance.  This parameter ...";
CM_ SG_ 2633665790 Hvesp15TotalAccumulatedCharge "HVESP15 Total Accumulated Charge: The total accumulated amp hours which have flowed through this High Voltage Energy Storage Pack instance.  This parameter is the sum of the absolute values of the Ampere hours into and out of this HVES instance.  Thi...";
CM_ SG_ 2633665790 Hvesp15TotalLifetimeEnergyInput "HVESP15 Total Lifetime Energy Input: The cumulative energy which has flowed into this High Voltage Energy Storage Pack instance over the lifetime of the battery pack. This parameter is the sum of the Energy into this HVES instance. This value is rese...";
CM_ SG_ 2633665790 Hvsp15TtlLftmEnrgOtpt "HVESP15 Total Lifetime Energy Output: The cumulative energy which has flowed out of this High Voltage Energy Storage Pack instance over the lifetime of the battery pack. This parameter is the sum of the Energy out of this HVES instance. This value is...";
CM_ BO_ 2566557182 "High Voltage Energy Storage Pack 15 Configuration";
CM_ SG_ 2566557182 Hvesp15NominalVoltage "HVESP15 Nominal Voltage: Per the HVES manufacturer, this is the nominal operating voltage of this High Voltage Energy Storage Pack instance, e.g. '300V' or '600V'.This parameter is for one of multiple packs in an HVESS.  If there is only one pack in ...";
CM_ SG_ 2566557182 Hvsp15RmmnddMnmmOprtngVltg "HVESP15 Recommended Minimum Operating Voltage: Per the HVES manufacturer, this is the minimum recommended voltage level for this High Voltage Energy Storage Pack instance operation.  Operating below this value may compromise HVES life.This parameter ...";
CM_ SG_ 2566557182 Hvsp15RmmnddMxmmOprtngVltg "HVESP15 Recommended Maximum Operating Voltage: Per the HVES manufacturer, this is the maximum recommended voltage level for this High Voltage Energy Storage Pack instance operation.  Operating above this value may compromise HVES life.This parameter ...";
CM_ SG_ 2566557182 Hvsp15RmmnddMnmmSttOfChrg "HVESP15 Recommended Minimum State Of Charge: Per the HVES manufacturer, this is the recommended minimum state of charge for this High Voltage Energy Storage Pack instance operation.  Operating below this value may compromise HVES life.This parameter ...";
CM_ SG_ 2566557182 Hvsp15RmmnddMxmmSttOfChrg "HVESP15 Recommended Maximum State Of Charge: Per the HVES manufacturer, this is the recommended maximum state of charge for this High Voltage Energy Storage Pack instance operation.  Operating above this value may compromise HVES life.This parameter ...";
CM_ SG_ 2566557182 Hvsp15RmmnddMxmmOprtngTmprtr "HVESP15 Recommended Maximum Operating Temperature: Per the HVES manufacturer, this is the recommended maximum temperature for this High Voltage Energy Storage Pack instance operation.  Operating above this value may damage HVES hardware, or compromis...";
CM_ SG_ 2566557182 Hvsp15RmmnddMnmmOprtngTmprtr "HVESP15 Recommended Minimum Operating Temperature: Per the HVES manufacturer, this is the recommended minimum temperature for this High Voltage Energy Storage Pack instance operation.  Operating below this value may damage HVES hardware, or compromis...";
CM_ SG_ 2566557182 Hvesp15CellMaximumVoltageLimit "HVESP15 Cell Maximum Voltage Limit: Per the HVES manufacturer, this is the maximum cell voltage for this High Voltage Energy Storage Pack instance operation.  Operating above this value may damage HVES hardware, or compromise HVES life.This parameter...";
CM_ SG_ 2566557182 Hvesp15CellMinimumVoltageLimit "HVESP15 Cell Minimum Voltage Limit: Per the HVES manufacturer, this is the minimum cell voltage for this High Voltage Energy Storage Pack instance operation.  Operating below this value may damage HVES hardware, or compromise HVES life.This parameter...";
CM_ SG_ 2566557182 Hvesp15NominalRatedCapacity "HVESP15 Nominal Rated Capacity: Per the HVES manufacturer, this is the manufacturer's nominal rated capacity of this instance of the energy storage system.  The rated capacity does not change over the life of the HVES.This parameter is for one of mul...";
CM_ BO_ 2633666302 "High Voltage Energy Storage Pack 16 History";
CM_ SG_ 2633666302 Hvesp16StateOfHealth "HVESP16 State of Health: This signal represents the expected remaining Life of this High Voltage Energy Storage Pack instance, in percent.  Battery life is a manufacturer-specific measure of how well the energy storage system is functioning relative ...";
CM_ SG_ 2633666302 Hvsp16CnttrOpnUndrLdCnt "HVESP16 Contactor Open Under Load Count: This signal represents the number of times the contactors inside this High Voltage Energy Storage Pack instance have opened while current is flowing through them.  The current level (that determines if an open...";
CM_ SG_ 2633666302 Hvesp16TotalEnergyThroughput "HVESP16 Total Energy Throughput: The total energy throughput which has flowed through this High Voltage Energy Storage Pack instance.  This parameter is the sum of the absolute values of the Energy into and out of this HVES instance.  This parameter ...";
CM_ SG_ 2633666302 Hvesp16TotalAccumulatedCharge "HVESP16 Total Accumulated Charge: The total accumulated amp hours which have flowed through this High Voltage Energy Storage Pack instance.  This parameter is the sum of the absolute values of the Ampere hours into and out of this HVES instance.  Thi...";
CM_ SG_ 2633666302 Hvesp16TotalLifetimeEnergyInput "HVESP16 Total Lifetime Energy Input: The cumulative energy which has flowed into this High Voltage Energy Storage Pack instance over the lifetime of the battery pack. This parameter is the sum of the Energy into this HVES instance. This value is rese...";
CM_ SG_ 2633666302 Hvsp16TtlLftmEnrgOtpt "HVESP16 Total Lifetime Energy Output: The cumulative energy which has flowed out of this High Voltage Energy Storage Pack instance over the lifetime of the battery pack. This parameter is the sum of the Energy out of this HVES instance. This value is...";
CM_ BO_ 2566557694 "High Voltage Energy Storage Pack 16 Configuration";
CM_ SG_ 2566557694 Hvesp16NominalVoltage "HVESP16 Nominal Voltage: Per the HVES manufacturer, this is the nominal operating voltage of this High Voltage Energy Storage Pack instance, e.g. '300V' or '600V'.This parameter is for one of multiple packs in an HVESS.  If there is only one pack in ...";
CM_ SG_ 2566557694 Hvsp16RmmnddMnmmOprtngVltg "HVESP16 Recommended Minimum Operating Voltage: Per the HVES manufacturer, this is the minimum recommended voltage level for this High Voltage Energy Storage Pack instance operation.  Operating below this value may compromise HVES life.This parameter ...";
CM_ SG_ 2566557694 Hvsp16RmmnddMxmmOprtngVltg "HVESP16 Recommended Maximum Operating Voltage: Per the HVES manufacturer, this is the maximum recommended voltage level for this High Voltage Energy Storage Pack instance operation.  Operating above this value may compromise HVES life.This parameter ...";
CM_ SG_ 2566557694 Hvsp16RmmnddMnmmSttOfChrg "HVESP16 Recommended Minimum State Of Charge: Per the HVES manufacturer, this is the recommended minimum state of charge for this High Voltage Energy Storage Pack instance operation.  Operating below this value may compromise HVES life.This parameter ...";
CM_ SG_ 2566557694 Hvsp16RmmnddMxmmSttOfChrg "HVESP16 Recommended Maximum State Of Charge: Per the HVES manufacturer, this is the recommended maximum state of charge for this High Voltage Energy Storage Pack instance operation.  Operating above this value may compromise HVES life.This parameter ...";
CM_ SG_ 2566557694 Hvsp16RmmnddMxmmOprtngTmprtr "HVESP16 Recommended Maximum Operating Temperature: Per the HVES manufacturer, this is the recommended maximum temperature for this High Voltage Energy Storage Pack instance operation.  Operating above this value may damage HVES hardware, or compromis...";
CM_ SG_ 2566557694 Hvsp16RmmnddMnmmOprtngTmprtr "HVESP16 Recommended Minimum Operating Temperature: Per the HVES manufacturer, this is the recommended minimum temperature for this High Voltage Energy Storage Pack instance operation.  Operating below this value may damage HVES hardware, or compromis...";
CM_ SG_ 2566557694 Hvesp16CellMaximumVoltageLimit "HVESP16 Cell Maximum Voltage Limit: Per the HVES manufacturer, this is the maximum cell voltage for this High Voltage Energy Storage Pack instance operation.  Operating above this value may damage HVES hardware, or compromise HVES life.This parameter...";
CM_ SG_ 2566557694 Hvesp16CellMinimumVoltageLimit "HVESP16 Cell Minimum Voltage Limit: Per the HVES manufacturer, this is the minimum cell voltage for this High Voltage Energy Storage Pack instance operation.  Operating below this value may damage HVES hardware, or compromise HVES life.This parameter...";
CM_ SG_ 2566557694 Hvesp16NominalRatedCapacity "HVESP16 Nominal Rated Capacity: Per the HVES manufacturer, this is the manufacturer's nominal rated capacity of this instance of the energy storage system.  The rated capacity does not change over the life of the HVES.This parameter is for one of mul...";
CM_ BO_ 2633666814 "High Voltage Energy Storage Pack 17 History";
CM_ SG_ 2633666814 Hvesp17StateOfHealth "HVESP17 State of Health: This signal represents the expected remaining Life of this High Voltage Energy Storage Pack instance, in percent.  Battery life is a manufacturer-specific measure of how well the energy storage system is functioning relative ...";
CM_ SG_ 2633666814 Hvsp17CnttrOpnUndrLdCnt "HVESP17 Contactor Open Under Load Count: This signal represents the number of times the contactors inside this High Voltage Energy Storage Pack instance have opened while current is flowing through them.  The current level (that determines if an open...";
CM_ SG_ 2633666814 Hvesp17TotalEnergyThroughput "HVESP17 Total Energy Throughput: The total energy throughput which has flowed through this High Voltage Energy Storage Pack instance.  This parameter is the sum of the absolute values of the Energy into and out of this HVES instance.  This parameter ...";
CM_ SG_ 2633666814 Hvesp17TotalAccumulatedCharge "HVESP17 Total Accumulated Charge: The total accumulated amp hours which have flowed through this High Voltage Energy Storage Pack instance.  This parameter is the sum of the absolute values of the Ampere hours into and out of this HVES instance.  Thi...";
CM_ SG_ 2633666814 Hvesp17TotalLifetimeEnergyInput "HVESP17 Total Lifetime Energy Input: The cumulative energy which has flowed into this High Voltage Energy Storage Pack instance over the lifetime of the battery pack. This parameter is the sum of the Energy into this HVES instance. This value is rese...";
CM_ SG_ 2633666814 Hvsp17TtlLftmEnrgOtpt "HVESP17 Total Lifetime Energy Output: The cumulative energy which has flowed out of this High Voltage Energy Storage Pack instance over the lifetime of the battery pack. This parameter is the sum of the Energy out of this HVES instance. This value is...";
CM_ BO_ 2566558206 "High Voltage Energy Storage Pack 17 Configuration";
CM_ SG_ 2566558206 Hvesp17NominalVoltage "HVESP17 Nominal Voltage: Per the HVES manufacturer, this is the nominal operating voltage of this High Voltage Energy Storage Pack instance, e.g. '300V' or '600V'.This parameter is for one of multiple packs in an HVESS.  If there is only one pack in ...";
CM_ SG_ 2566558206 Hvsp17RmmnddMnmmOprtngVltg "HVESP17 Recommended Minimum Operating Voltage: Per the HVES manufacturer, this is the minimum recommended voltage level for this High Voltage Energy Storage Pack instance operation.  Operating below this value may compromise HVES life.This parameter ...";
CM_ SG_ 2566558206 Hvsp17RmmnddMxmmOprtngVltg "HVESP17 Recommended Maximum Operating Voltage: Per the HVES manufacturer, this is the maximum recommended voltage level for this High Voltage Energy Storage Pack instance operation.  Operating above this value may compromise HVES life.This parameter ...";
CM_ SG_ 2566558206 Hvsp17RmmnddMnmmSttOfChrg "HVESP17 Recommended Minimum State Of Charge: Per the HVES manufacturer, this is the recommended minimum state of charge for this High Voltage Energy Storage Pack instance operation.  Operating below this value may compromise HVES life.This parameter ...";
CM_ SG_ 2566558206 Hvsp17RmmnddMxmmSttOfChrg "HVESP17 Recommended Maximum State Of Charge: Per the HVES manufacturer, this is the recommended maximum state of charge for this High Voltage Energy Storage Pack instance operation.  Operating above this value may compromise HVES life.This parameter ...";
CM_ SG_ 2566558206 Hvsp17RmmnddMxmmOprtngTmprtr "HVESP17 Recommended Maximum Operating Temperature: Per the HVES manufacturer, this is the recommended maximum temperature for this High Voltage Energy Storage Pack instance operation.  Operating above this value may damage HVES hardware, or compromis...";
CM_ SG_ 2566558206 Hvsp17RmmnddMnmmOprtngTmprtr "HVESP17 Recommended Minimum Operating Temperature: Per the HVES manufacturer, this is the recommended minimum temperature for this High Voltage Energy Storage Pack instance operation.  Operating below this value may damage HVES hardware, or compromis...";
CM_ SG_ 2566558206 Hvesp17CellMaximumVoltageLimit "HVESP17 Cell Maximum Voltage Limit: Per the HVES manufacturer, this is the maximum cell voltage for this High Voltage Energy Storage Pack instance operation.  Operating above this value may damage HVES hardware, or compromise HVES life.This parameter...";
CM_ SG_ 2566558206 Hvesp17CellMinimumVoltageLimit "HVESP17 Cell Minimum Voltage Limit: Per the HVES manufacturer, this is the minimum cell voltage for this High Voltage Energy Storage Pack instance operation.  Operating below this value may damage HVES hardware, or compromise HVES life.This parameter...";
CM_ SG_ 2566558206 Hvesp17NominalRatedCapacity "HVESP17 Nominal Rated Capacity: Per the HVES manufacturer, this is the manufacturer's nominal rated capacity of this instance of the energy storage system.  The rated capacity does not change over the life of the HVES.This parameter is for one of mul...";
CM_ BO_ 2633667326 "High Voltage Energy Storage Pack 18 History";
CM_ SG_ 2633667326 Hvesp18StateOfHealth "HVESP18 State of Health: This signal represents the expected remaining Life of this High Voltage Energy Storage Pack instance, in percent.  Battery life is a manufacturer-specific measure of how well the energy storage system is functioning relative ...";
CM_ SG_ 2633667326 Hvsp18CnttrOpnUndrLdCnt "HVESP18 Contactor Open Under Load Count: This signal represents the number of times the contactors inside this High Voltage Energy Storage Pack instance have opened while current is flowing through them.  The current level (that determines if an open...";
CM_ SG_ 2633667326 Hvesp18TotalEnergyThroughput "HVESP18 Total Energy Throughput: The total energy throughput which has flowed through this High Voltage Energy Storage Pack instance.  This parameter is the sum of the absolute values of the Energy into and out of this HVES instance.  This parameter ...";
CM_ SG_ 2633667326 Hvesp18TotalAccumulatedCharge "HVESP18 Total Accumulated Charge: The total accumulated amp hours which have flowed through this High Voltage Energy Storage Pack instance.  This parameter is the sum of the absolute values of the Ampere hours into and out of this HVES instance.  Thi...";
CM_ SG_ 2633667326 Hvesp18TotalLifetimeEnergyInput "HVESP18 Total Lifetime Energy Input: The cumulative energy which has flowed into this High Voltage Energy Storage Pack instance over the lifetime of the battery pack. This parameter is the sum of the Energy into this HVES instance. This value is rese...";
CM_ SG_ 2633667326 Hvsp18TtlLftmEnrgOtpt "HVESP18 Total Lifetime Energy Output: The cumulative energy which has flowed out of this High Voltage Energy Storage Pack instance over the lifetime of the battery pack. This parameter is the sum of the Energy out of this HVES instance. This value is...";
CM_ BO_ 2566558718 "High Voltage Energy Storage Pack 18 Configuration";
CM_ SG_ 2566558718 Hvesp18NominalVoltage "HVESP18 Nominal Voltage: Per the HVES manufacturer, this is the nominal operating voltage of this High Voltage Energy Storage Pack instance, e.g. '300V' or '600V'.This parameter is for one of multiple packs in an HVESS.  If there is only one pack in ...";
CM_ SG_ 2566558718 Hvsp18RmmnddMnmmOprtngVltg "HVESP18 Recommended Minimum Operating Voltage: Per the HVES manufacturer, this is the minimum recommended voltage level for this High Voltage Energy Storage Pack instance operation.  Operating below this value may compromise HVES life.This parameter ...";
CM_ SG_ 2566558718 Hvsp18RmmnddMxmmOprtngVltg "HVESP18 Recommended Maximum Operating Voltage: Per the HVES manufacturer, this is the maximum recommended voltage level for this High Voltage Energy Storage Pack instance operation.  Operating above this value may compromise HVES life.This parameter ...";
CM_ SG_ 2566558718 Hvsp18RmmnddMnmmSttOfChrg "HVESP18 Recommended Minimum State Of Charge: Per the HVES manufacturer, this is the recommended minimum state of charge for this High Voltage Energy Storage Pack instance operation.  Operating below this value may compromise HVES life.This parameter ...";
CM_ SG_ 2566558718 Hvsp18RmmnddMxmmSttOfChrg "HVESP18 Recommended Maximum State Of Charge: Per the HVES manufacturer, this is the recommended maximum state of charge for this High Voltage Energy Storage Pack instance operation.  Operating above this value may compromise HVES life.This parameter ...";
CM_ SG_ 2566558718 Hvsp18RmmnddMxmmOprtngTmprtr "HVESP18 Recommended Maximum Operating Temperature: Per the HVES manufacturer, this is the recommended maximum temperature for this High Voltage Energy Storage Pack instance operation.  Operating above this value may damage HVES hardware, or compromis...";
CM_ SG_ 2566558718 Hvsp18RmmnddMnmmOprtngTmprtr "HVESP18 Recommended Minimum Operating Temperature: Per the HVES manufacturer, this is the recommended minimum temperature for this High Voltage Energy Storage Pack instance operation.  Operating below this value may damage HVES hardware, or compromis...";
CM_ SG_ 2566558718 Hvesp18CellMaximumVoltageLimit "HVESP18 Cell Maximum Voltage Limit: Per the HVES manufacturer, this is the maximum cell voltage for this High Voltage Energy Storage Pack instance operation.  Operating above this value may damage HVES hardware, or compromise HVES life.This parameter...";
CM_ SG_ 2566558718 Hvesp18CellMinimumVoltageLimit "HVESP18 Cell Minimum Voltage Limit: Per the HVES manufacturer, this is the minimum cell voltage for this High Voltage Energy Storage Pack instance operation.  Operating below this value may damage HVES hardware, or compromise HVES life.This parameter...";
CM_ SG_ 2566558718 Hvesp18NominalRatedCapacity "HVESP18 Nominal Rated Capacity: Per the HVES manufacturer, this is the manufacturer's nominal rated capacity of this instance of the energy storage system.  The rated capacity does not change over the life of the HVES.This parameter is for one of mul...";
CM_ BO_ 2633667838 "High Voltage Energy Storage Pack 19 History";
CM_ SG_ 2633667838 Hvesp19StateOfHealth "HVESP19 State of Health: This signal represents the expected remaining Life of this High Voltage Energy Storage Pack instance, in percent.  Battery life is a manufacturer-specific measure of how well the energy storage system is functioning relative ...";
CM_ SG_ 2633667838 Hvsp19CnttrOpnUndrLdCnt "HVESP19 Contactor Open Under Load Count: This signal represents the number of times the contactors inside this High Voltage Energy Storage Pack instance have opened while current is flowing through them.  The current level (that determines if an open...";
CM_ SG_ 2633667838 Hvesp19TotalEnergyThroughput "HVESP19 Total Energy Throughput: The total energy throughput which has flowed through this High Voltage Energy Storage Pack instance.  This parameter is the sum of the absolute values of the Energy into and out of this HVES instance.  This parameter ...";
CM_ SG_ 2633667838 Hvesp19TotalAccumulatedCharge "HVESP19 Total Accumulated Charge: The total accumulated amp hours which have flowed through this High Voltage Energy Storage Pack instance.  This parameter is the sum of the absolute values of the Ampere hours into and out of this HVES instance.  Thi...";
CM_ SG_ 2633667838 Hvesp19TotalLifetimeEnergyInput "HVESP19 Total Lifetime Energy Input: The cumulative energy which has flowed into this High Voltage Energy Storage Pack instance over the lifetime of the battery pack. This parameter is the sum of the Energy into this HVES instance. This value is rese...";
CM_ SG_ 2633667838 Hvsp19TtlLftmEnrgOtpt "HVESP19 Total Lifetime Energy Output: The cumulative energy which has flowed out of this High Voltage Energy Storage Pack instance over the lifetime of the battery pack. This parameter is the sum of the Energy out of this HVES instance. This value is...";
CM_ BO_ 2566559230 "High Voltage Energy Storage Pack 19 Configuration";
CM_ SG_ 2566559230 Hvesp19NominalVoltage "HVESP19 Nominal Voltage: Per the HVES manufacturer, this is the nominal operating voltage of this High Voltage Energy Storage Pack instance, e.g. '300V' or '600V'.This parameter is for one of multiple packs in an HVESS.  If there is only one pack in ...";
CM_ SG_ 2566559230 Hvsp19RmmnddMnmmOprtngVltg "HVESP19 Recommended Minimum Operating Voltage: Per the HVES manufacturer, this is the minimum recommended voltage level for this High Voltage Energy Storage Pack instance operation.  Operating below this value may compromise HVES life.This parameter ...";
CM_ SG_ 2566559230 Hvsp19RmmnddMxmmOprtngVltg "HVESP19 Recommended Maximum Operating Voltage: Per the HVES manufacturer, this is the maximum recommended voltage level for this High Voltage Energy Storage Pack instance operation.  Operating above this value may compromise HVES life.This parameter ...";
CM_ SG_ 2566559230 Hvsp19RmmnddMnmmSttOfChrg "HVESP19 Recommended Minimum State Of Charge: Per the HVES manufacturer, this is the recommended minimum state of charge for this High Voltage Energy Storage Pack instance operation.  Operating below this value may compromise HVES life.This parameter ...";
CM_ SG_ 2566559230 Hvsp19RmmnddMxmmSttOfChrg "HVESP19 Recommended Maximum State Of Charge: Per the HVES manufacturer, this is the recommended maximum state of charge for this High Voltage Energy Storage Pack instance operation.  Operating above this value may compromise HVES life.This parameter ...";
CM_ SG_ 2566559230 Hvsp19RmmnddMxmmOprtngTmprtr "HVESP19 Recommended Maximum Operating Temperature: Per the HVES manufacturer, this is the recommended maximum temperature for this High Voltage Energy Storage Pack instance operation.  Operating above this value may damage HVES hardware, or compromis...";
CM_ SG_ 2566559230 Hvsp19RmmnddMnmmOprtngTmprtr "HVESP19 Recommended Minimum Operating Temperature: Per the HVES manufacturer, this is the recommended minimum temperature for this High Voltage Energy Storage Pack instance operation.  Operating below this value may damage HVES hardware, or compromis...";
CM_ SG_ 2566559230 Hvesp19CellMaximumVoltageLimit "HVESP19 Cell Maximum Voltage Limit: Per the HVES manufacturer, this is the maximum cell voltage for this High Voltage Energy Storage Pack instance operation.  Operating above this value may damage HVES hardware, or compromise HVES life.This parameter...";
CM_ SG_ 2566559230 Hvesp19CellMinimumVoltageLimit "HVESP19 Cell Minimum Voltage Limit: Per the HVES manufacturer, this is the minimum cell voltage for this High Voltage Energy Storage Pack instance operation.  Operating below this value may damage HVES hardware, or compromise HVES life.This parameter...";
CM_ SG_ 2566559230 Hvesp19NominalRatedCapacity "HVESP19 Nominal Rated Capacity: Per the HVES manufacturer, this is the manufacturer's nominal rated capacity of this instance of the energy storage system.  The rated capacity does not change over the life of the HVES.This parameter is for one of mul...";
CM_ BO_ 2633668350 "High Voltage Energy Storage Pack 20 History";
CM_ SG_ 2633668350 Hvesp20StateOfHealth "HVESP20 State of Health: This signal represents the expected remaining Life of this High Voltage Energy Storage Pack instance, in percent.  Battery life is a manufacturer-specific measure of how well the energy storage system is functioning relative ...";
CM_ SG_ 2633668350 Hvsp20CnttrOpnUndrLdCnt "HVESP20 Contactor Open Under Load Count: This signal represents the number of times the contactors inside this High Voltage Energy Storage Pack instance have opened while current is flowing through them.  The current level (that determines if an open...";
CM_ SG_ 2633668350 Hvesp20TotalEnergyThroughput "HVESP20 Total Energy Throughput: The total energy throughput which has flowed through this High Voltage Energy Storage Pack instance.  This parameter is the sum of the absolute values of the Energy into and out of this HVES instance.  This parameter ...";
CM_ SG_ 2633668350 Hvesp20TotalAccumulatedCharge "HVESP20 Total Accumulated Charge: The total accumulated amp hours which have flowed through this High Voltage Energy Storage Pack instance.  This parameter is the sum of the absolute values of the Ampere hours into and out of this HVES instance.  Thi...";
CM_ SG_ 2633668350 Hvesp20TotalLifetimeEnergyInput "HVESP20 Total Lifetime Energy Input: The cumulative energy which has flowed into this High Voltage Energy Storage Pack instance over the lifetime of the battery pack. This parameter is the sum of the Energy into this HVES instance. This value is rese...";
CM_ SG_ 2633668350 Hvsp20TtlLftmEnrgOtpt "HVESP20 Total Lifetime Energy Output: The cumulative energy which has flowed out of this High Voltage Energy Storage Pack instance over the lifetime of the battery pack. This parameter is the sum of the Energy out of this HVES instance. This value is...";
CM_ BO_ 2566559742 "High Voltage Energy Storage Pack 20 Configuration";
CM_ SG_ 2566559742 Hvesp20NominalVoltage "HVESP20 Nominal Voltage: Per the HVES manufacturer, this is the nominal operating voltage of this High Voltage Energy Storage Pack instance, e.g. '300V' or '600V'.This parameter is for one of multiple packs in an HVESS.  If there is only one pack in ...";
CM_ SG_ 2566559742 Hvsp20RmmnddMnmmOprtngVltg "HVESP20 Recommended Minimum Operating Voltage: Per the HVES manufacturer, this is the minimum recommended voltage level for this High Voltage Energy Storage Pack instance operation.  Operating below this value may compromise HVES life.This parameter ...";
CM_ SG_ 2566559742 Hvsp20RmmnddMxmmOprtngVltg "HVESP20 Recommended Maximum Operating Voltage: Per the HVES manufacturer, this is the maximum recommended voltage level for this High Voltage Energy Storage Pack instance operation.  Operating above this value may compromise HVES life.This parameter ...";
CM_ SG_ 2566559742 Hvsp20RmmnddMnmmSttOfChrg "HVESP20 Recommended Minimum State Of Charge: Per the HVES manufacturer, this is the recommended minimum state of charge for this High Voltage Energy Storage Pack instance operation.  Operating below this value may compromise HVES life.This parameter ...";
CM_ SG_ 2566559742 Hvsp20RmmnddMxmmSttOfChrg "HVESP20 Recommended Maximum State Of Charge: Per the HVES manufacturer, this is the recommended maximum state of charge for this High Voltage Energy Storage Pack instance operation.  Operating above this value may compromise HVES life.This parameter ...";
CM_ SG_ 2566559742 Hvsp20RmmnddMxmmOprtngTmprtr "HVESP20 Recommended Maximum Operating Temperature: Per the HVES manufacturer, this is the recommended maximum temperature for this High Voltage Energy Storage Pack instance operation.  Operating above this value may damage HVES hardware, or compromis...";
CM_ SG_ 2566559742 Hvsp20RmmnddMnmmOprtngTmprtr "HVESP20 Recommended Minimum Operating Temperature: Per the HVES manufacturer, this is the recommended minimum temperature for this High Voltage Energy Storage Pack instance operation.  Operating below this value may damage HVES hardware, or compromis...";
CM_ SG_ 2566559742 Hvesp20CellMaximumVoltageLimit "HVESP20 Cell Maximum Voltage Limit: Per the HVES manufacturer, this is the maximum cell voltage for this High Voltage Energy Storage Pack instance operation.  Operating above this value may damage HVES hardware, or compromise HVES life.This parameter...";
CM_ SG_ 2566559742 Hvesp20CellMinimumVoltageLimit "HVESP20 Cell Minimum Voltage Limit: Per the HVES manufacturer, this is the minimum cell voltage for this High Voltage Energy Storage Pack instance operation.  Operating below this value may damage HVES hardware, or compromise HVES life.This parameter...";
CM_ SG_ 2566559742 Hvesp20NominalRatedCapacity "HVESP20 Nominal Rated Capacity: Per the HVES manufacturer, this is the manufacturer's nominal rated capacity of this instance of the energy storage system.  The rated capacity does not change over the life of the HVES.This parameter is for one of mul...";
CM_ BO_ 2633668862 "High Voltage Energy Storage Pack 21 History";
CM_ SG_ 2633668862 Hvesp21StateOfHealth "HVESP21 State of Health: This signal represents the expected remaining Life of this High Voltage Energy Storage Pack instance, in percent.  Battery life is a manufacturer-specific measure of how well the energy storage system is functioning relative ...";
CM_ SG_ 2633668862 Hvsp21CnttrOpnUndrLdCnt "HVESP21 Contactor Open Under Load Count: This signal represents the number of times the contactors inside this High Voltage Energy Storage Pack instance have opened while current is flowing through them.  The current level (that determines if an open...";
CM_ SG_ 2633668862 Hvesp21TotalEnergyThroughput "HVESP21 Total Energy Throughput: The total energy throughput which has flowed through this High Voltage Energy Storage Pack instance.  This parameter is the sum of the absolute values of the Energy into and out of this HVES instance.  This parameter ...";
CM_ SG_ 2633668862 Hvesp21TotalAccumulatedCharge "HVESP21 Total Accumulated Charge: The total accumulated amp hours which have flowed through this High Voltage Energy Storage Pack instance.  This parameter is the sum of the absolute values of the Ampere hours into and out of this HVES instance.  Thi...";
CM_ SG_ 2633668862 Hvesp21TotalLifetimeEnergyInput "HVESP21 Total Lifetime Energy Input: The cumulative energy which has flowed into this High Voltage Energy Storage Pack instance over the lifetime of the battery pack. This parameter is the sum of the Energy into this HVES instance. This value is rese...";
CM_ SG_ 2633668862 Hvsp21TtlLftmEnrgOtpt "HVESP21 Total Lifetime Energy Output: The cumulative energy which has flowed out of this High Voltage Energy Storage Pack instance over the lifetime of the battery pack. This parameter is the sum of the Energy out of this HVES instance. This value is...";
CM_ BO_ 2566560254 "High Voltage Energy Storage Pack 21 Configuration";
CM_ SG_ 2566560254 Hvesp21NominalVoltage "HVESP21 Nominal Voltage: Per the HVES manufacturer, this is the nominal operating voltage of this High Voltage Energy Storage Pack instance, e.g. '300V' or '600V'.This parameter is for one of multiple packs in an HVESS.  If there is only one pack in ...";
CM_ SG_ 2566560254 Hvsp21RmmnddMnmmOprtngVltg "HVESP21 Recommended Minimum Operating Voltage: Per the HVES manufacturer, this is the minimum recommended voltage level for this High Voltage Energy Storage Pack instance operation.  Operating below this value may compromise HVES life.This parameter ...";
CM_ SG_ 2566560254 Hvsp21RmmnddMxmmOprtngVltg "HVESP21 Recommended Maximum Operating Voltage: Per the HVES manufacturer, this is the maximum recommended voltage level for this High Voltage Energy Storage Pack instance operation.  Operating above this value may compromise HVES life.This parameter ...";
CM_ SG_ 2566560254 Hvsp21RmmnddMnmmSttOfChrg "HVESP21 Recommended Minimum State Of Charge: Per the HVES manufacturer, this is the recommended minimum state of charge for this High Voltage Energy Storage Pack instance operation.  Operating below this value may compromise HVES life.This parameter ...";
CM_ SG_ 2566560254 Hvsp21RmmnddMxmmSttOfChrg "HVESP21 Recommended Maximum State Of Charge: Per the HVES manufacturer, this is the recommended maximum state of charge for this High Voltage Energy Storage Pack instance operation.  Operating above this value may compromise HVES life.This parameter ...";
CM_ SG_ 2566560254 Hvsp21RmmnddMxmmOprtngTmprtr "HVESP21 Recommended Maximum Operating Temperature: Per the HVES manufacturer, this is the recommended maximum temperature for this High Voltage Energy Storage Pack instance operation.  Operating above this value may damage HVES hardware, or compromis...";
CM_ SG_ 2566560254 Hvsp21RmmnddMnmmOprtngTmprtr "HVESP21 Recommended Minimum Operating Temperature: Per the HVES manufacturer, this is the recommended minimum temperature for this High Voltage Energy Storage Pack instance operation.  Operating below this value may damage HVES hardware, or compromis...";
CM_ SG_ 2566560254 Hvesp21CellMaximumVoltageLimit "HVESP21 Cell Maximum Voltage Limit: Per the HVES manufacturer, this is the maximum cell voltage for this High Voltage Energy Storage Pack instance operation.  Operating above this value may damage HVES hardware, or compromise HVES life.This parameter...";
CM_ SG_ 2566560254 Hvesp21CellMinimumVoltageLimit "HVESP21 Cell Minimum Voltage Limit: Per the HVES manufacturer, this is the minimum cell voltage for this High Voltage Energy Storage Pack instance operation.  Operating below this value may damage HVES hardware, or compromise HVES life.This parameter...";
CM_ SG_ 2566560254 Hvesp21NominalRatedCapacity "HVESP21 Nominal Rated Capacity: Per the HVES manufacturer, this is the manufacturer's nominal rated capacity of this instance of the energy storage system.  The rated capacity does not change over the life of the HVES.This parameter is for one of mul...";
CM_ BO_ 2633669374 "High Voltage Energy Storage Pack 22 History";
CM_ SG_ 2633669374 Hvesp22StateOfHealth "HVESP22 State of Health: This signal represents the expected remaining Life of this High Voltage Energy Storage Pack instance, in percent.  Battery life is a manufacturer-specific measure of how well the energy storage system is functioning relative ...";
CM_ SG_ 2633669374 Hvsp22CnttrOpnUndrLdCnt "HVESP22 Contactor Open Under Load Count: This signal represents the number of times the contactors inside this High Voltage Energy Storage Pack instance have opened while current is flowing through them.  The current level (that determines if an open...";
CM_ SG_ 2633669374 Hvesp22TotalEnergyThroughput "HVESP22 Total Energy Throughput: The total energy throughput which has flowed through this High Voltage Energy Storage Pack instance.  This parameter is the sum of the absolute values of the Energy into and out of this HVES instance.  This parameter ...";
CM_ SG_ 2633669374 Hvesp22TotalAccumulatedCharge "HVESP22 Total Accumulated Charge: The total accumulated amp hours which have flowed through this High Voltage Energy Storage Pack instance.  This parameter is the sum of the absolute values of the Ampere hours into and out of this HVES instance.  Thi...";
CM_ SG_ 2633669374 Hvesp22TotalLifetimeEnergyInput "HVESP22 Total Lifetime Energy Input: The cumulative energy which has flowed into this High Voltage Energy Storage Pack instance over the lifetime of the battery pack. This parameter is the sum of the Energy into this HVES instance. This value is rese...";
CM_ SG_ 2633669374 Hvsp22TtlLftmEnrgOtpt "HVESP22 Total Lifetime Energy Output: The cumulative energy which has flowed out of this High Voltage Energy Storage Pack instance over the lifetime of the battery pack. This parameter is the sum of the Energy out of this HVES instance. This value is...";
CM_ BO_ 2566560766 "High Voltage Energy Storage Pack 22 Configuration";
CM_ SG_ 2566560766 Hvesp22NominalVoltage "HVESP22 Nominal Voltage: Per the HVES manufacturer, this is the nominal operating voltage of this High Voltage Energy Storage Pack instance, e.g. '300V' or '600V'.This parameter is for one of multiple packs in an HVESS.  If there is only one pack in ...";
CM_ SG_ 2566560766 Hvsp22RmmnddMnmmOprtngVltg "HVESP22 Recommended Minimum Operating Voltage: Per the HVES manufacturer, this is the minimum recommended voltage level for this High Voltage Energy Storage Pack instance operation.  Operating below this value may compromise HVES life.This parameter ...";
CM_ SG_ 2566560766 Hvsp22RmmnddMxmmOprtngVltg "HVESP22 Recommended Maximum Operating Voltage: Per the HVES manufacturer, this is the maximum recommended voltage level for this High Voltage Energy Storage Pack instance operation.  Operating above this value may compromise HVES life.This parameter ...";
CM_ SG_ 2566560766 Hvsp22RmmnddMnmmSttOfChrg "HVESP22 Recommended Minimum State Of Charge: Per the HVES manufacturer, this is the recommended minimum state of charge for this High Voltage Energy Storage Pack instance operation.  Operating below this value may compromise HVES life.This parameter ...";
CM_ SG_ 2566560766 Hvsp22RmmnddMxmmSttOfChrg "HVESP22 Recommended Maximum State Of Charge: Per the HVES manufacturer, this is the recommended maximum state of charge for this High Voltage Energy Storage Pack instance operation.  Operating above this value may compromise HVES life.This parameter ...";
CM_ SG_ 2566560766 Hvsp22RmmnddMxmmOprtngTmprtr "HVESP22 Recommended Maximum Operating Temperature: Per the HVES manufacturer, this is the recommended maximum temperature for this High Voltage Energy Storage Pack instance operation.  Operating above this value may damage HVES hardware, or compromis...";
CM_ SG_ 2566560766 Hvsp22RmmnddMnmmOprtngTmprtr "HVESP22 Recommended Minimum Operating Temperature: Per the HVES manufacturer, this is the recommended minimum temperature for this High Voltage Energy Storage Pack instance operation.  Operating below this value may damage HVES hardware, or compromis...";
CM_ SG_ 2566560766 Hvesp22CellMaximumVoltageLimit "HVESP22 Cell Maximum Voltage Limit: Per the HVES manufacturer, this is the maximum cell voltage for this High Voltage Energy Storage Pack instance operation.  Operating above this value may damage HVES hardware, or compromise HVES life.This parameter...";
CM_ SG_ 2566560766 Hvesp22CellMinimumVoltageLimit "HVESP22 Cell Minimum Voltage Limit: Per the HVES manufacturer, this is the minimum cell voltage for this High Voltage Energy Storage Pack instance operation.  Operating below this value may damage HVES hardware, or compromise HVES life.This parameter...";
CM_ SG_ 2566560766 Hvesp22NominalRatedCapacity "HVESP22 Nominal Rated Capacity: Per the HVES manufacturer, this is the manufacturer's nominal rated capacity of this instance of the energy storage system.  The rated capacity does not change over the life of the HVES.This parameter is for one of mul...";
CM_ BO_ 2633669886 "High Voltage Energy Storage Pack 23 History";
CM_ SG_ 2633669886 Hvesp23StateOfHealth "HVESP23 State of Health: This signal represents the expected remaining Life of this High Voltage Energy Storage Pack instance, in percent.  Battery life is a manufacturer-specific measure of how well the energy storage system is functioning relative ...";
CM_ SG_ 2633669886 Hvsp23CnttrOpnUndrLdCnt "HVESP23 Contactor Open Under Load Count: This signal represents the number of times the contactors inside this High Voltage Energy Storage Pack instance have opened while current is flowing through them.  The current level (that determines if an open...";
CM_ SG_ 2633669886 Hvesp23TotalEnergyThroughput "HVESP23 Total Energy Throughput: The total energy throughput which has flowed through this High Voltage Energy Storage Pack instance.  This parameter is the sum of the absolute values of the Energy into and out of this HVES instance.  This parameter ...";
CM_ SG_ 2633669886 Hvesp23TotalAccumulatedCharge "HVESP23 Total Accumulated Charge: The total accumulated amp hours which have flowed through this High Voltage Energy Storage Pack instance.  This parameter is the sum of the absolute values of the Ampere hours into and out of this HVES instance.  Thi...";
CM_ SG_ 2633669886 Hvesp23TotalLifetimeEnergyInput "HVESP23 Total Lifetime Energy Input: The cumulative energy which has flowed into this High Voltage Energy Storage Pack instance over the lifetime of the battery pack. This parameter is the sum of the Energy into this HVES instance. This value is rese...";
CM_ SG_ 2633669886 Hvsp23TtlLftmEnrgOtpt "HVESP23 Total Lifetime Energy Output: The cumulative energy which has flowed out of this High Voltage Energy Storage Pack instance over the lifetime of the battery pack. This parameter is the sum of the Energy out of this HVES instance. This value is...";
CM_ BO_ 2566561278 "High Voltage Energy Storage Pack 23 Configuration";
CM_ SG_ 2566561278 Hvesp23NominalVoltage "HVESP23 Nominal Voltage: Per the HVES manufacturer, this is the nominal operating voltage of this High Voltage Energy Storage Pack instance, e.g. '300V' or '600V'.This parameter is for one of multiple packs in an HVESS.  If there is only one pack in ...";
CM_ SG_ 2566561278 Hvsp23RmmnddMnmmOprtngVltg "HVESP23 Recommended Minimum Operating Voltage: Per the HVES manufacturer, this is the minimum recommended voltage level for this High Voltage Energy Storage Pack instance operation.  Operating below this value may compromise HVES life.This parameter ...";
CM_ SG_ 2566561278 Hvsp23RmmnddMxmmOprtngVltg "HVESP23 Recommended Maximum Operating Voltage: Per the HVES manufacturer, this is the maximum recommended voltage level for this High Voltage Energy Storage Pack instance operation.  Operating above this value may compromise HVES life.This parameter ...";
CM_ SG_ 2566561278 Hvsp23RmmnddMnmmSttOfChrg "HVESP23 Recommended Minimum State Of Charge: Per the HVES manufacturer, this is the recommended minimum state of charge for this High Voltage Energy Storage Pack instance operation.  Operating below this value may compromise HVES life.This parameter ...";
CM_ SG_ 2566561278 Hvsp23RmmnddMxmmSttOfChrg "HVESP23 Recommended Maximum State Of Charge: Per the HVES manufacturer, this is the recommended maximum state of charge for this High Voltage Energy Storage Pack instance operation.  Operating above this value may compromise HVES life.This parameter ...";
CM_ SG_ 2566561278 Hvsp23RmmnddMxmmOprtngTmprtr "HVESP23 Recommended Maximum Operating Temperature: Per the HVES manufacturer, this is the recommended maximum temperature for this High Voltage Energy Storage Pack instance operation.  Operating above this value may damage HVES hardware, or compromis...";
CM_ SG_ 2566561278 Hvsp23RmmnddMnmmOprtngTmprtr "HVESP23 Recommended Minimum Operating Temperature: Per the HVES manufacturer, this is the recommended minimum temperature for this High Voltage Energy Storage Pack instance operation.  Operating below this value may damage HVES hardware, or compromis...";
CM_ SG_ 2566561278 Hvesp23CellMaximumVoltageLimit "HVESP23 Cell Maximum Voltage Limit: Per the HVES manufacturer, this is the maximum cell voltage for this High Voltage Energy Storage Pack instance operation.  Operating above this value may damage HVES hardware, or compromise HVES life.This parameter...";
CM_ SG_ 2566561278 Hvesp23CellMinimumVoltageLimit "HVESP23 Cell Minimum Voltage Limit: Per the HVES manufacturer, this is the minimum cell voltage for this High Voltage Energy Storage Pack instance operation.  Operating below this value may damage HVES hardware, or compromise HVES life.This parameter...";
CM_ SG_ 2566561278 Hvesp23NominalRatedCapacity "HVESP23 Nominal Rated Capacity: Per the HVES manufacturer, this is the manufacturer's nominal rated capacity of this instance of the energy storage system.  The rated capacity does not change over the life of the HVES.This parameter is for one of mul...";
CM_ BO_ 2633670398 "High Voltage Energy Storage Pack 24 History";
CM_ SG_ 2633670398 Hvesp24StateOfHealth "HVESP24 State of Health: This signal represents the expected remaining Life of this High Voltage Energy Storage Pack instance, in percent.  Battery life is a manufacturer-specific measure of how well the energy storage system is functioning relative ...";
CM_ SG_ 2633670398 Hvsp24CnttrOpnUndrLdCnt "HVESP24 Contactor Open Under Load Count: This signal represents the number of times the contactors inside this High Voltage Energy Storage Pack instance have opened while current is flowing through them.  The current level (that determines if an open...";
CM_ SG_ 2633670398 Hvesp24TotalEnergyThroughput "HVESP24 Total Energy Throughput: The total energy throughput which has flowed through this High Voltage Energy Storage Pack instance.  This parameter is the sum of the absolute values of the Energy into and out of this HVES instance.  This parameter ...";
CM_ SG_ 2633670398 Hvesp24TotalAccumulatedCharge "HVESP24 Total Accumulated Charge: The total accumulated amp hours which have flowed through this High Voltage Energy Storage Pack instance.  This parameter is the sum of the absolute values of the Ampere hours into and out of this HVES instance.  Thi...";
CM_ SG_ 2633670398 Hvesp24TotalLifetimeEnergyInput "HVESP24 Total Lifetime Energy Input: The cumulative energy which has flowed into this High Voltage Energy Storage Pack instance over the lifetime of the battery pack. This parameter is the sum of the Energy into this HVES instance. This value is rese...";
CM_ SG_ 2633670398 Hvsp24TtlLftmEnrgOtpt "HVESP24 Total Lifetime Energy Output: The cumulative energy which has flowed out of this High Voltage Energy Storage Pack instance over the lifetime of the battery pack. This parameter is the sum of the Energy out of this HVES instance. This value is...";
CM_ BO_ 2566561790 "High Voltage Energy Storage Pack 24 Configuration";
CM_ SG_ 2566561790 Hvesp24NominalVoltage "HVESP24 Nominal Voltage: Per the HVES manufacturer, this is the nominal operating voltage of this High Voltage Energy Storage Pack instance, e.g. '300V' or '600V'.This parameter is for one of multiple packs in an HVESS.  If there is only one pack in ...";
CM_ SG_ 2566561790 Hvsp24RmmnddMnmmOprtngVltg "HVESP24 Recommended Minimum Operating Voltage: Per the HVES manufacturer, this is the minimum recommended voltage level for this High Voltage Energy Storage Pack instance operation.  Operating below this value may compromise HVES life.This parameter ...";
CM_ SG_ 2566561790 Hvsp24RmmnddMxmmOprtngVltg "HVESP24 Recommended Maximum Operating Voltage: Per the HVES manufacturer, this is the maximum recommended voltage level for this High Voltage Energy Storage Pack instance operation.  Operating above this value may compromise HVES life.This parameter ...";
CM_ SG_ 2566561790 Hvsp24RmmnddMnmmSttOfChrg "HVESP24 Recommended Minimum State Of Charge: Per the HVES manufacturer, this is the recommended minimum state of charge for this High Voltage Energy Storage Pack instance operation.  Operating below this value may compromise HVES life.This parameter ...";
CM_ SG_ 2566561790 Hvsp24RmmnddMxmmSttOfChrg "HVESP24 Recommended Maximum State Of Charge: Per the HVES manufacturer, this is the recommended maximum state of charge for this High Voltage Energy Storage Pack instance operation.  Operating above this value may compromise HVES life.This parameter ...";
CM_ SG_ 2566561790 Hvsp24RmmnddMxmmOprtngTmprtr "HVESP24 Recommended Maximum Operating Temperature: Per the HVES manufacturer, this is the recommended maximum temperature for this High Voltage Energy Storage Pack instance operation.  Operating above this value may damage HVES hardware, or compromis...";
CM_ SG_ 2566561790 Hvsp24RmmnddMnmmOprtngTmprtr "HVESP24 Recommended Minimum Operating Temperature: Per the HVES manufacturer, this is the recommended minimum temperature for this High Voltage Energy Storage Pack instance operation.  Operating below this value may damage HVES hardware, or compromis...";
CM_ SG_ 2566561790 Hvesp24CellMaximumVoltageLimit "HVESP24 Cell Maximum Voltage Limit: Per the HVES manufacturer, this is the maximum cell voltage for this High Voltage Energy Storage Pack instance operation.  Operating above this value may damage HVES hardware, or compromise HVES life.This parameter...";
CM_ SG_ 2566561790 Hvesp24CellMinimumVoltageLimit "HVESP24 Cell Minimum Voltage Limit: Per the HVES manufacturer, this is the minimum cell voltage for this High Voltage Energy Storage Pack instance operation.  Operating below this value may damage HVES hardware, or compromise HVES life.This parameter...";
CM_ SG_ 2566561790 Hvesp24NominalRatedCapacity "HVESP24 Nominal Rated Capacity: Per the HVES manufacturer, this is the manufacturer's nominal rated capacity of this instance of the energy storage system.  The rated capacity does not change over the life of the HVES.This parameter is for one of mul...";
CM_ BO_ 2633670910 "High Voltage Energy Storage Pack 25 History";
CM_ SG_ 2633670910 Hvesp25StateOfHealth "HVESP25 State of Health: This signal represents the expected remaining Life of this High Voltage Energy Storage Pack instance, in percent.  Battery life is a manufacturer-specific measure of how well the energy storage system is functioning relative ...";
CM_ SG_ 2633670910 Hvsp25CnttrOpnUndrLdCnt "HVESP25 Contactor Open Under Load Count: This signal represents the number of times the contactors inside this High Voltage Energy Storage Pack instance have opened while current is flowing through them.  The current level (that determines if an open...";
CM_ SG_ 2633670910 Hvesp25TotalEnergyThroughput "HVESP25 Total Energy Throughput: The total energy throughput which has flowed through this High Voltage Energy Storage Pack instance.  This parameter is the sum of the absolute values of the Energy into and out of this HVES instance.  This parameter ...";
CM_ SG_ 2633670910 Hvesp25TotalAccumulatedCharge "HVESP25 Total Accumulated Charge: The total accumulated amp hours which have flowed through this High Voltage Energy Storage Pack instance.  This parameter is the sum of the absolute values of the Ampere hours into and out of this HVES instance.  Thi...";
CM_ SG_ 2633670910 Hvesp25TotalLifetimeEnergyInput "HVESP25 Total Lifetime Energy Input: The cumulative energy which has flowed into this High Voltage Energy Storage Pack instance over the lifetime of the battery pack. This parameter is the sum of the Energy into this HVES instance. This value is rese...";
CM_ SG_ 2633670910 Hvsp25TtlLftmEnrgOtpt "HVESP25 Total Lifetime Energy Output: The cumulative energy which has flowed out of this High Voltage Energy Storage Pack instance over the lifetime of the battery pack. This parameter is the sum of the Energy out of this HVES instance. This value is...";
CM_ BO_ 2566562302 "High Voltage Energy Storage Pack 25 Configuration";
CM_ SG_ 2566562302 Hvesp25NominalVoltage "HVESP25 Nominal Voltage: Per the HVES manufacturer, this is the nominal operating voltage of this High Voltage Energy Storage Pack instance, e.g. '300V' or '600V'.This parameter is for one of multiple packs in an HVESS.  If there is only one pack in ...";
CM_ SG_ 2566562302 Hvsp25RmmnddMnmmOprtngVltg "HVESP25 Recommended Minimum Operating Voltage: Per the HVES manufacturer, this is the minimum recommended voltage level for this High Voltage Energy Storage Pack instance operation.  Operating below this value may compromise HVES life.This parameter ...";
CM_ SG_ 2566562302 Hvsp25RmmnddMxmmOprtngVltg "HVESP25 Recommended Maximum Operating Voltage: Per the HVES manufacturer, this is the maximum recommended voltage level for this High Voltage Energy Storage Pack instance operation.  Operating above this value may compromise HVES life.This parameter ...";
CM_ SG_ 2566562302 Hvsp25RmmnddMnmmSttOfChrg "HVESP25 Recommended Minimum State Of Charge: Per the HVES manufacturer, this is the recommended minimum state of charge for this High Voltage Energy Storage Pack instance operation.  Operating below this value may compromise HVES life.This parameter ...";
CM_ SG_ 2566562302 Hvsp25RmmnddMxmmSttOfChrg "HVESP25 Recommended Maximum State Of Charge: Per the HVES manufacturer, this is the recommended maximum state of charge for this High Voltage Energy Storage Pack instance operation.  Operating above this value may compromise HVES life.This parameter ...";
CM_ SG_ 2566562302 Hvsp25RmmnddMxmmOprtngTmprtr "HVESP25 Recommended Maximum Operating Temperature: Per the HVES manufacturer, this is the recommended maximum temperature for this High Voltage Energy Storage Pack instance operation.  Operating above this value may damage HVES hardware, or compromis...";
CM_ SG_ 2566562302 Hvsp25RmmnddMnmmOprtngTmprtr "HVESP25 Recommended Minimum Operating Temperature: Per the HVES manufacturer, this is the recommended minimum temperature for this High Voltage Energy Storage Pack instance operation.  Operating below this value may damage HVES hardware, or compromis...";
CM_ SG_ 2566562302 Hvesp25CellMaximumVoltageLimit "HVESP25 Cell Maximum Voltage Limit: Per the HVES manufacturer, this is the maximum cell voltage for this High Voltage Energy Storage Pack instance operation.  Operating above this value may damage HVES hardware, or compromise HVES life.This parameter...";
CM_ SG_ 2566562302 Hvesp25CellMinimumVoltageLimit "HVESP25 Cell Minimum Voltage Limit: Per the HVES manufacturer, this is the minimum cell voltage for this High Voltage Energy Storage Pack instance operation.  Operating below this value may damage HVES hardware, or compromise HVES life.This parameter...";
CM_ SG_ 2566562302 Hvesp25NominalRatedCapacity "HVESP25 Nominal Rated Capacity: Per the HVES manufacturer, this is the manufacturer's nominal rated capacity of this instance of the energy storage system.  The rated capacity does not change over the life of the HVES.This parameter is for one of mul...";
CM_ BO_ 2633671422 "High Voltage Energy Storage Pack 26 History";
CM_ SG_ 2633671422 Hvesp26StateOfHealth "HVESP26 State of Health: This signal represents the expected remaining Life of this High Voltage Energy Storage Pack instance, in percent.  Battery life is a manufacturer-specific measure of how well the energy storage system is functioning relative ...";
CM_ SG_ 2633671422 Hvsp26CnttrOpnUndrLdCnt "HVESP26 Contactor Open Under Load Count: This signal represents the number of times the contactors inside this High Voltage Energy Storage Pack instance have opened while current is flowing through them.  The current level (that determines if an open...";
CM_ SG_ 2633671422 Hvesp26TotalEnergyThroughput "HVESP26 Total Energy Throughput: The total energy throughput which has flowed through this High Voltage Energy Storage Pack instance.  This parameter is the sum of the absolute values of the Energy into and out of this HVES instance.  This parameter ...";
CM_ SG_ 2633671422 Hvesp26TotalAccumulatedCharge "HVESP26 Total Accumulated Charge: The total accumulated amp hours which have flowed through this High Voltage Energy Storage Pack instance.  This parameter is the sum of the absolute values of the Ampere hours into and out of this HVES instance.  Thi...";
CM_ SG_ 2633671422 Hvesp26TotalLifetimeEnergyInput "HVESP26 Total Lifetime Energy Input: The cumulative energy which has flowed into this High Voltage Energy Storage Pack instance over the lifetime of the battery pack. This parameter is the sum of the Energy into this HVES instance. This value is rese...";
CM_ SG_ 2633671422 Hvsp26TtlLftmEnrgOtpt "HVESP26 Total Lifetime Energy Output: The cumulative energy which has flowed out of this High Voltage Energy Storage Pack instance over the lifetime of the battery pack. This parameter is the sum of the Energy out of this HVES instance. This value is...";
CM_ BO_ 2566562814 "High Voltage Energy Storage Pack 26 Configuration";
CM_ SG_ 2566562814 Hvesp26NominalVoltage "HVESP26 Nominal Voltage: Per the HVES manufacturer, this is the nominal operating voltage of this High Voltage Energy Storage Pack instance, e.g. '300V' or '600V'.This parameter is for one of multiple packs in an HVESS.  If there is only one pack in ...";
CM_ SG_ 2566562814 Hvsp26RmmnddMnmmOprtngVltg "HVESP26 Recommended Minimum Operating Voltage: Per the HVES manufacturer, this is the minimum recommended voltage level for this High Voltage Energy Storage Pack instance operation.  Operating below this value may compromise HVES life.This parameter ...";
CM_ SG_ 2566562814 Hvsp26RmmnddMxmmOprtngVltg "HVESP26 Recommended Maximum Operating Voltage: Per the HVES manufacturer, this is the maximum recommended voltage level for this High Voltage Energy Storage Pack instance operation.  Operating above this value may compromise HVES life.This parameter ...";
CM_ SG_ 2566562814 Hvsp26RmmnddMnmmSttOfChrg "HVESP26 Recommended Minimum State Of Charge: Per the HVES manufacturer, this is the recommended minimum state of charge for this High Voltage Energy Storage Pack instance operation.  Operating below this value may compromise HVES life.This parameter ...";
CM_ SG_ 2566562814 Hvsp26RmmnddMxmmSttOfChrg "HVESP26 Recommended Maximum State Of Charge: Per the HVES manufacturer, this is the recommended maximum state of charge for this High Voltage Energy Storage Pack instance operation.  Operating above this value may compromise HVES life.This parameter ...";
CM_ SG_ 2566562814 Hvsp26RmmnddMxmmOprtngTmprtr "HVESP26 Recommended Maximum Operating Temperature: Per the HVES manufacturer, this is the recommended maximum temperature for this High Voltage Energy Storage Pack instance operation.  Operating above this value may damage HVES hardware, or compromis...";
CM_ SG_ 2566562814 Hvsp26RmmnddMnmmOprtngTmprtr "HVESP26 Recommended Minimum Operating Temperature: Per the HVES manufacturer, this is the recommended minimum temperature for this High Voltage Energy Storage Pack instance operation.  Operating below this value may damage HVES hardware, or compromis...";
CM_ SG_ 2566562814 Hvesp26CellMaximumVoltageLimit "HVESP26 Cell Maximum Voltage Limit: Per the HVES manufacturer, this is the maximum cell voltage for this High Voltage Energy Storage Pack instance operation.  Operating above this value may damage HVES hardware, or compromise HVES life.This parameter...";
CM_ SG_ 2566562814 Hvesp26CellMinimumVoltageLimit "HVESP26 Cell Minimum Voltage Limit: Per the HVES manufacturer, this is the minimum cell voltage for this High Voltage Energy Storage Pack instance operation.  Operating below this value may damage HVES hardware, or compromise HVES life.This parameter...";
CM_ SG_ 2566562814 Hvesp26NominalRatedCapacity "HVESP26 Nominal Rated Capacity: Per the HVES manufacturer, this is the manufacturer's nominal rated capacity of this instance of the energy storage system.  The rated capacity does not change over the life of the HVES.This parameter is for one of mul...";
CM_ BO_ 2566563070 "Automated Driving System Control 2";
CM_ SG_ 2566563070 AdsVehicleSpeedControlCommand "ADS Vehicle Speed Control Command: Indicates the desired vehicle speed as commanded by the automated driving system (ADS).  ADS Vehicle Speed Control Command shall only be honored when ADS Vehicle Speed Control Consent (SPN 15247) is set to 01b.Note:...";
CM_ SG_ 2566563070 AdsVhlSpdCntrlCmmndPrrt "ADS Vehicle Speed Control Command Priority: This parameter is the priority of the ADS Vehicle Speed Control Command (SPN 15248). The recipient will honor the ADS Vehicle Speed Control Command with the highest priority when multiple ADSC2 messages are...";
CM_ SG_ 2566563070 Adsc2EmbeddedIntegritySupport "ADSC2 Embedded Integrity Support: Indicates that SPN 22263 (ADSC2 CRC) and SPN 22262 (ADSC2 Counter) are supported by the sender.00b = ADSC2 embedded CRC and Counter are supported by the sender01b = ADSC2 protection is provided using an external (not...";
CM_ SG_ 2566563070 Adsc2Counter "ADSC2 Counter: The message counter is used to detect situations where the transmitting ECU malfunction repeats the same frame all the time. The receiver of the information may use the counter parameter to detect this situation. The transmitting devic...";
CM_ SG_ 2566563070 Adsc2Crc "ADSC2 CRC: The CRC is defined as follows:- Length: 8 bits- Polynomial: x^8+x^5+x^3+x^2+x+1- Initial Value: FFh- Input Data Reflection: Not reflected- Result Data Reflection: Not reflected- XOR value: FFhSAE makes no claim of the functional safety lev...";
CM_ BO_ 2566658814 "HVESS Thermal Management System Control 1";
CM_ SG_ 2566658814 HvssTMtSstItCtTptRqst "HVESS Thermal Management System Inlet Coolant Temperature Request: Parameter used to request the desired HVESS Thermal Management System Inlet Coolant Temperature.";
CM_ SG_ 2566658814 HvssTMtSstOttCtTptRqst "HVESS Thermal Management System Outlet Coolant Temperature Request: Parameter used to request the desired HVESS Thermal Management System Outlet Coolant Temperature.";
CM_ SG_ 2566658814 HvssTMtSstCtFwRtRqst "HVESS Thermal Management System Coolant Flow Rate Request: Parameter used to request the desired HVESS Thermal Management System coolant flow rate.";
CM_ SG_ 2566658814 HvssThrmlMngmntSstmHtrEnlCmmnd "HVESS Thermal Management System Heater Enable Command: Command to enable HVESS Thermal Management heater.00b = Disable Heater01b = Enable Heater10b = Reserved11b = Don't Care/Take no action";
CM_ SG_ 2566658814 HvssTMtSstCtPpECd "HVESS Thermal Management System Coolant Pump Enable Command: Command to enable and direction HVESS Thermal Management System Coolant Pump.00b = Motor Off01b = Motor On Normal/Default Direction10b = Motor On Reverse Direction11b = Don't Care/Take no a...";
CM_ SG_ 2566658814 HvssTMtSstCpssECd "HVESS Thermal Management System Compressor Enable Command: Command to enable HVESS Thermal Management Compressor.00b = Compressor Off01b = Compressor On10b = Reserved11b = Don't Care/Take no action";
CM_ BO_ 2365332478 "HVESS Thermal Management System Control 2";
CM_ SG_ 2365332478 HvssTMtSstCtPpSpdCd "HVESS Thermal Management System Coolant Pump Speed Command: Speed command to HVESS Thermal Management Coolant Pump.Note: Both SPN 20460 (HVESS Thermal Management System Coolant Pump Speed Command) and SPN 20461 (HVESS Thermal Management System Coolan...";
CM_ SG_ 2365332478 HvssTMtSstCtPpPtSpdCd "HVESS Thermal Management System Coolant Pump Percent Speed Command: Speed command to HVESS Thermal Management Coolant Pump in percentage of maximum speed.Note: Both SPN 20460 (HVESS Thermal Management System Coolant Pump Speed Command) and SPN 20461 ...";
CM_ SG_ 2365332478 HvssTMtSstCpssSpdCd "HVESS Thermal Management System Compressor Speed Command: Speed command to HVESS Thermal Management Compressor Speed.Note: Both SPN 20462 (HVESS Thermal Management System Compressor Speed Command) and SPN 20463 (HVESS Thermal Management System Compre...";
CM_ SG_ 2365332478 HvssTMtSstCpssPtSpdCd "HVESS Thermal Management System Compressor Percent Speed Command: Speed command to HVESS Thermal Management Compressor Speed  in percentage of maximum speed.Note: Both SPN 20462 (HVESS Thermal Management System Compressor Speed Command) and SPN 20463...";
CM_ BO_ 2566679038 "EV Operator Indicators 1";
CM_ SG_ 2566679038 HvessEstimatedRemainingDistance "HVESS Estimated Remaining Distance: Estimated remaining distance based on existing available HVES system capacity.";
CM_ BO_ 2566079486 "Electronic Park Brake Controller 1";
CM_ SG_ 2566079486 EltrnPrkBrkPwrUntCntrlArStts "Electronic Park Brake Power Unit Control Air Status: Status of control air pressure output to power unit spring brake system.000b = Exhausted001b = Exhausting Pressure (Intermediate)010b = Building Pressure (Intermediate)011b = Charged100b = Reserved...";
CM_ SG_ 2566079486 EltrnPrkBrkTwdUntCntrlArStts "Electronic Park Brake Towed Unit Control Air Status: Status or control air pressure output to towed unit supply. While in the No Trailer Attached state, the EPB (Electronic Park Brake) system is indicating that it's operating with behavior suitable f...";
CM_ SG_ 2566079486 EltrnPrkBrkOpnAntRllAwStts "Electronic Park Brake Occupancy Anti-Roll-Away Status: Status of Anti-Roll-Away (ARA) driver assistance feature in the Electronic Park Brake (EPB) system. ARA can automatically set the park brakes in order to mitigate potential vehicle rollaway event...";
CM_ SG_ 2566079486 EltrnPrkBrkTrlrBrkRlsStts "Electronic Park Brake Trailer Brake Release Status: Status of Trailer Brake Release (TBR) driver assistance function of the Electronic Park Brake (EPB) system. TBR can automatically charge the Towed Unit resulting in the trailer unparking in order to...";
CM_ SG_ 2566079486 EltrnPrkBrkPwrUntVhlTp "Electronic Park Brake Power Unit Vehicle Type: EPB (Electronic Park Brake) system configuration for Power Unit (PU) vehicle type. This is a configuration parameter.00b = Towing (i.e. tractor)01b = Non-Towing Straight Truck10b = Non-Towing bus11b = Er...";
CM_ SG_ 2566079486 EltrnPrkBrkOprtngMd "Electronic Park Brake Operating Mode: The EPB (Electronic Park Brake) system can be in various operating modes, depending on the state of the vehicle and available inputs.0000b = Normal Mode - Intended for use during typical vehicle operation when al...";
CM_ SG_ 2566079486 EtPBTOvdItSvBStts "Electronic Park Brake Trailer Override Interlock Service Brake Status: Status of Service Brake interlock override.  If this value is overriden, the EPB (Electronic Park Brake) system will not use it as interlock control for trailer unparking.00b = EP...";
CM_ SG_ 2566079486 EtPBTOvdItItStts "Electronic Park Brake Trailer Override Interlock Ignition Status: Status of Ignition Switch Interlock override.  If this value is overriden, the EPB (Electronic Park Brake) system will not use it as interlock control for trailer unparking.00b = EPB w...";
CM_ SG_ 2566079486 EtPBTOvdItStBtSwtStts "Electronic Park Brake Trailer Override Interlock Seat Belt Switch Status: Status of Seat Belt Switch (SBS) interlock override.  If this value is overriden, the EPB (Electronic Park Brake) system will not use it as interlock control for trailer unpark...";
CM_ SG_ 2566079486 EtPBTOvdItD1Stts "Electronic Park Brake Trailer Override Interlock Door 1 Status: Status of Door 1 Switch interlock override.  If this value is overriden, the EPB (Electronic Park Brake) system will not use it as interlock control for trailer unparking.00b = EPB will ...";
CM_ SG_ 2566079486 EtPBTOvdItD2Stts "Electronic Park Brake Trailer Override Interlock Door 2 Status: Status of Door 2 Switch interlock override.  If this value is overriden, the EPB (Electronic Park Brake) system will not use it as interlock control for trailer unparking.00b = EPB will ...";
CM_ SG_ 2566079486 EltrnPrkBrkExhstAtSpdStts "Electronic Park Brake Exhaust-at-Speed Status: Status of Exhaust-at-Speed (EAS) dynamic function of the Electronic Park Brake (EPB) system. EAS can occur when an operator applies the parking brakes while the vehicle is in motion.  Parameters are conf...";
CM_ SG_ 2566079486 ElectronicParkBrakePowerStatus "Electronic Park Brake Power Status: The EPB (Electronic Park Brake) system will send out the Entering Sleep Mode message before entering sleep mode.000b = Normal001b = Entering Sleep Mode010b = Reserved011b = Reserved100b = Reserved101b = Reserved110...";
CM_ SG_ 2566079486 AntiRollAwayTimer "Anti-Roll-Away Timer: Anti-Roll-Away (ARA) Countdown Timer.Parameter Specific States:F1h - ARA TriggerF2h - ARA Acknowledgement PendingF3h - Countdown StartedF4h - Countdown PausedF5h - Countdown Not Started";
CM_ SG_ 2566079486 EltrnPrkBrkPwrUntSwthStts "Electronic Park Brake Power Unit Switch Status: EPB (Electronic Park Brake) system user input for park and unpark for the Power Unit (PU).000b = Neutral Position001b = Apply Park Brake Position - Driver Request Not Honored010b = Apply Park Brake Posi...";
CM_ SG_ 2566079486 EltrnPrkBrkTwdUntSwthStts "Electronic Park Brake Towed Unit Switch Status: EPB (Electronic Park Brake) system user input for park and unpark for the Towed Unit (TU).000b = Neutral Position001b = Apply Park Brake Position - Driver Request Not Honored010b = Apply Park Brake Posi...";
CM_ BO_ 2566079742 "Electronic Park Brake Controller 2";
CM_ SG_ 2566079742 EltrnPrkBrkPwrUntCntrlArPrssr "Electronic Park Brake Power Unit Control Air Pressure: The pneumatic pressure in the control portion of the park brake circuit as reported by the EPB (Electronic Park Brake) system.";
CM_ SG_ 2566079742 EltrnPrkBrkTwdUntCntrlArPrssr "Electronic Park Brake Towed Unit Control Air Pressure: The pneumatic pressure in the control portion of the trailer supply circuit as reported by the EPB (Electronic Park Brake) system.";
CM_ SG_ 2566079742 EltrnPrkBrkPwrUntCrtArPrssr "Electronic Park Brake Power Unit Circuit Air Pressure: The pneumatic pressure in the park brake circuit as reported by the EPB (Electronic Park Brake) system.";
CM_ SG_ 2566079742 EltrnPrkBrkTwdUntCrtArPrssr "Electronic Park Brake Towed Unit Circuit Air Pressure: The pneumatic pressure in the trailer supply circuit as reported by the EPB (Electronic Park Brake) system.";
CM_ SG_ 2566079742 EtPBExtRqstSstSttPwUtApp "Electronic Park Brake External Request System State Power Unit Apply: Indicates when external control of EPB (Electronic Park Brake) is allowed for the Power Unit (PU) apply 00b = External EPB Power Unit Apply will not be accepted01b = External EPB P...";
CM_ SG_ 2566079742 EtPBExtRqstSstSttPwUtRs "Electronic Park Brake External Request System State Power Unit Release: Indicates when external control of EPB (Electronic Park Brake) is allowed for the Power Unit (PU) release. 00b = External EPB Power Unit Release will not be accepted01b = Externa...";
CM_ SG_ 2566079742 EtPBExtRqstSstSttTwdUtSpp "Electronic Park Brake External Request System State Towed Unit Supply: Indicates when external control of EPB (Electronic Park Brake) is allowed for the Towed Unit (TU) supply. 00b = External EPB Towed Unit Supply will not be accepted01b = External E...";
CM_ SG_ 2566079742 EtPBExtRqstSstSttTwdUtEvt "Electronic Park Brake External Request System State Towed Unit Evacuate: Indicates when external control of EPB (Electronic Park Brake) is allowed for the Towed Unit (TU) evacuate. 00b = External EPB Towed Unit Evacuate will not be accepted01b = Exte...";
CM_ SG_ 2566079742 EtPBAtvExtCtMdPwUt "Electronic Park Brake Active External Control Mode Power Unit: Indicates which external control mode is executed by the EPB (Electronic Park Brake) system for the Power Unit (PU). 0000b = No external Power Unit apply or release demand being executed0...";
CM_ SG_ 2566079742 EtPBAtvExtCtMdTwdUt "Electronic Park Brake Active External Control Mode Towed Unit: Indicates which external control mode is executed by the EPB (Electronic Park Brake) system for the Towed Unit (PU). 0000b = No external Power Unit apply or release demand being executed0...";
CM_ SG_ 2566079742 EtPBPAtSpdExtBRqstStts "Electronic Park Brake Park-at-Speed External Brake Request Status: Status of Park-at-Speed (PAS) External Brake Request (XBR). Will communicate the state of the EPB (Electronic Park Brake) system requesting that the vehicle service brakes be applied....";
CM_ SG_ 2566079742 EltrnPrkBrkTrnsmssnNtrlRqstStts "Electronic Park Brake Transmission Neutral Request Status: Status of Transmission Neutral Request (TNR). Will communicate the state of the EPB (Electronic Park Brake) system requesting that the vehicle transmission be placed in neutral if the parking...";
CM_ SG_ 2566079742 EtPBAtRAwRqstSstSttIt "Electronic Park Brake Anti-Roll-Away Request System State Inhibit: Indicates if external control of EPB (Electronic Park Brake) is allowed for Inhibit Anti-Roll-Away. 00b = External EPB Inhibit Anti-Roll-Away will not be accepted01b = External EPB In...";
CM_ SG_ 2566079742 EtPBAtvExtItAtRAw "Electronic Park Brake Active External Inhibit Anti-Roll-Away: Indicates external inhibit Anti-Roll-Away is executed by the EPB (Electronic Park Brake) system. 00b = No external inhibit Anti-Roll-Away being executed01b = External EPB Inhibit Anti-Roll...";
CM_ BO_ 2566538494 "Engine Speed/Load Factor Information 2";
CM_ SG_ 2566538494 TripAverageLoadFactor "Trip Average Load Factor: Indicates the average engine load factor while engine speed is greater than zero, since last trip reset. Engine operation during cruise control operation is included.Note: See SPN 1015 for Trip Drive Average Load Factor and ...";
CM_ SG_ 2566538494 TotalAverageLoadFactor "Total Average Load Factor: Indicates the average engine load factor while engine speed is greater than zero, over the life of the engine. Engine operation during cruise control operation is included.Note: See SPN 1016 for Total Drive Average Load Fac...";
CM_ BO_ 2365212158 "Generator Trip Energy 2";
CM_ SG_ 2365212158 GeneratorTripKvarHoursImport "Generator Trip kVAr Hours Import: The trip AC reactive energy imported by the generator since the last reset of the trip kVArh meter.This value will be reset by the user at will.";
CM_ BO_ 2566539006 "Security System Machine Operation Information";
CM_ SG_ 2566539006 SrtSstmTmTDslMhnOprtn "Security System Time to Disable Machine Operation: Indicates amount of time until the security system disables machine operation.For example, if there is a condition that if not resolved, will result in the machine operation becoming disabled, this S...";
CM_ SG_ 2566539006 SrtSstmTmTLmtMhnOprtn "Security System Time to Limit Machine Operation: Indicates amount of time until the security system limits machine operation.For example, if there is a condition that if not resolved, will result in the machine operation becoming limited in some way,...";
CM_ SG_ 2566539006 SrtSstmMhnOprtnDslRsn "Security System Machine Operation Disable Reason: Indicates the reason for the Security System to Disable Machine Operation.This SP can be used to indicate the reason that the machine operation is currently or actively disabled. The SP can also be us...";
CM_ SG_ 2566539006 SrtSstmMhnOprtnLmtRsn "Security System Machine Operation Limit Reason: Indicates the reason for the security system to limit machine operation.This SP can be used to indicate the reason that the machine operation is currently or actively Limited. The SP can also be used to...";
CM_ SG_ 2566539006 SrtSstmMhnOprtnStts "Security System Machine Operation Status: Indicates Machine Operation Status as commanded by a security system or anti-theft device.A status of Normal Operation means that the security system or anti-theft device is not preventing or limiting machine...";
CM_ BO_ 2566539262 "Engine Fuel Actuator Service Mode";
CM_ SG_ 2566539262 FuelActuator1ServiceModeRequest "Fuel Actuator 1 Service Mode Request: Intended for applications where SPN 633 represents a flow command, to request that the fuel actuator enter a service mode of operation in which SPN 633 is interpreted as a position command instead of a flow comma...";
CM_ SG_ 2566539262 FuelActuator2ServiceModeRequest "Fuel Actuator 2 Service Mode Request: Intended for applications where SPN 1244 represents a flow command, to request that the fuel actuator enter a service mode of operation in which SPN 1244 is interpreted as a position command instead of a flow com...";
CM_ BO_ 2566539518 "Steering Wheel Controls";
CM_ SG_ 2566539518 SteeringWheelControlNextSwitch "Steering Wheel Control Next Switch: Indicates the state of the steering wheel next switch button. This will typically cycle to the next favorite, station, or song that is currently providing audio.00b = Released (Off)01b = Pressed (On)10b = Error11b ...";
CM_ SG_ 2566539518 StrngWhlCntrlPrvsSwth "Steering Wheel Control Previous Switch: Indicates the state of the steering wheel previous switch button. This will typically cycle to the previous favorite, station, or song that is currently providing audio.00b = Released (Off)01b = Pressed (On)10b...";
CM_ SG_ 2566539518 StrngWhlCntrlVlmUpSwth "Steering Wheel Control Volume Up Switch: Indicates the status of the steering wheel volume up switch. This switch controls the volume of the audio that is actively playing.00b = Released (Off)01b = Pressed (On)10b = Error11b = Not Available";
CM_ SG_ 2566539518 StrngWhlCntrlVlmDwnSwth "Steering Wheel Control Volume Down Switch: Indicates the status of the steering wheel volume down switch. This switch controls the volume of the audio that is actively playing.00b = Released (Off)01b = Pressed (On)10b = Error11b = Not Available...";
CM_ SG_ 2566539518 StrngWhlCntrlCllEndSwth "Steering Wheel Control Call End Switch: Indicates the status of the steering wheel call end switch. This button is used to end an ongoing call or to mute entertainment (non-call) audio in some cases.00b = Released (Off)01b = Pressed (On)10b = Error11...";
CM_ SG_ 2566539518 StrngWhlCntrlVCmmntnSwth "Steering Wheel Control Voice Communication Switch: Status of the Steering Wheel Voice Communication Control Switch.00b = Released (Off)01b = Pressed (On)10b = Error11b = Not Available";
CM_ SG_ 2566539518 StrngWhlCntrlPshTTlkSwth "Steering Wheel Control Push To Talk Switch: Status of the Steering Wheel Push To Talk Switch.00b = Released (Off)01b = Pressed (On)10b = Error11b = Not Available";
CM_ BO_ 2566539774 "Park Assist";
CM_ SG_ 2566539774 FrontParkAssistStatus "Front Park Assist Status: Indicates the status of the Front Park Assist system. Park Assist systems detect objects during low velocity movement and typically utilize ultrasonics, radar, or cameras.000b = Off - Park assist is not enabled001b = Standby...";
CM_ SG_ 2566539774 RearParkAssistStatus "Rear Park Assist Status: Indicates the status of the Rear Park Assist system. Park Assist systems detect objects during low velocity movement and typically utilize ultrasonics, radar, or cameras.000b = Off - Park assist is not enabled001b = Standby -...";
CM_ BO_ 2364753406 "Genset Frequency Limitation";
CM_ SG_ 2364753406 LmtdFrqnSnstvMdRlPwrStpnt "Limited Frequency Sensitive Mode Real Power Setpoint: Desired Generator real power setpoint based on the active frequency defined by the Limited Frequency Sensitive Mode control curve.";
CM_ SG_ 2364753406 FrqnSnstvMdRlPwrStpnt "Frequency Sensitive Mode Real Power Setpoint: Desired Generator real power setpoint based on the active frequency defined by the Frequency Sensitive Mode control curve.";
CM_ SG_ 2364753406 GnrtrFrqnOffstStpnt "Generator Frequency Offset Setpoint: Provides a frequency offset that is added to the measured utility frequency.";
CM_ SG_ 2364753406 LmtdFrqnSnstvMdStts "Limited Frequency Sensitive Mode Status: Indicates when the Limited Frequency Sensitive Mode is active.00b = Inactive01b = Active10b = Error11b = Not available";
CM_ SG_ 2364753406 FrequencySensitiveModeStatus "Frequency Sensitive Mode Status: Indicates when the Frequency Sensitive Mode is active.00b = Inactive01b = Active10b = Error11b = Not available";
CM_ SG_ 2364753406 LmtdFrqnSnstvMdOvrfrqnEnlStts "Limited Frequency Sensitive Mode Overfrequency Enable Status: Indicates the enable status of the feature that allows Limited Frequency Sensetive Mode to function normally when the frequency of the system exceeds the threshold.00b = Disabled01b = Enab...";
CM_ SG_ 2364753406 FrqnSnstvMdEnlStts "Frequency Sensitive Mode Enable Status: Indicates when the Frequency Sensitive Mode is enabled.00b = Disabled01b = Enabled10b = Error11b = Not Available";
CM_ SG_ 2364753406 LtdFqSstvMdOvqESttsDtvtTsd "Limited Frequency Sensitive Mode Overfrequency Enable Status Deactivation Threshold Reset Status: Indicates the request for the deactivation threshold control that prevents the genset from changing real power when the measured frequency changes while...";
CM_ SG_ 2364753406 LmtdFrqnSnstvMdUndrfrqnEnlStts "Limited Frequency Sensitive Mode Underfrequency Enable Status: Indicates the enable status of the feature that allows Limited Frequency Sensetive Mode to function normally when the frequency of the system exceeds the limit.00b = Disabled01b = Enabled...";
CM_ BO_ 2364753662 "Genset Power Limitation";
CM_ SG_ 2364753662 UtltOprtrRlPwrExprtLmtPrntg "Utility Operator Real Power Export Limit Percentage: Utility operator real power maximum setpoint for the generator output power percentage";
CM_ SG_ 2364753662 UtltPrlllVltgRlPwrCrvStpntPrntg "Utility Parallel Voltage-Real Power Curve Setpoint Percentage: Generator real power setpoint as a percentage based on the active voltage defined by the voltage-real power control curve.";
CM_ SG_ 2364753662 UtltOprtrRlPwrExprtLmtStts "Utility Operator Real Power Export Limit Status: Indicates when the electrical utility operator is limiting the generator output power. Disabled indicates that the limiting feature is not turned on.00b = Inactive01b = Active10b = Error11b = Not avail...";
CM_ SG_ 2364753662 UtltPrlllVltgRlPwrCrvStts "Utility Parallel Voltage-Real Power Curve Status: Indicates when the Utility Parallel Voltage Real-Power Control Curve is active.00b = Inactive01b = Active10b = Error11b = Not available";
CM_ SG_ 2364753662 UttOptRPwExptLtStpt1Stts "Utility Operator Real Power Export Limit Setpoint 1 Status: Indicates when the electrical utility operator is limiting the generator output power for Setpoint 1.00b = Not Actively Limiting01b = Actively Limiting10b = Error11b = Not available";
CM_ SG_ 2364753662 UttOptRPwExptLtStpt2Stts "Utility Operator Real Power Export Limit Setpoint 2 Status: Indicates when the electrical utility operator is limiting the generator output power for Setpoint 2.00b = Not Actively Limiting01b = Actively Limiting10b = Error11b = Not available";
CM_ SG_ 2364753662 UttOptRPwExptLtStpt3Stts "Utility Operator Real Power Export Limit Setpoint 3 Status: Indicates when the electrical utility operator is limiting the generator output power for Setpoint 3.00b = Not Actively Limiting01b = Actively Limiting10b = Error11b = Not available";
CM_ SG_ 2364753662 UttOptRPwExptLtStpt4Stts "Utility Operator Real Power Export Limit Setpoint 4 Status: Indicates when the electrical utility operator is limiting the generator output power for Setpoint 4.00b = Not Actively Limiting01b = Actively Limiting10b = Error11b = Not available";
CM_ SG_ 2364753662 RlPwrRmpRtLmtEnlStts "Real Power Ramp Rate Limit Enable Status: Indicates when the Real Power Ramp Rate Limit is enabled.00b = Disabled01b = Enabled10b = Error11b = Not available";
CM_ SG_ 2364753662 RealPowerRampRateLimitStatus "Real Power Ramp Rate Limit Status: Indicates when the Ramp Rate Limitation is limiting the real power ramp rate.00b = Not Actively Limiting01b = Actively Limiting10b = Error11b = Not available";
CM_ BO_ 2364753918 "Genset Real Power Control";
CM_ SG_ 2364753918 RealPowerActiveSetpointSource "Real Power Active Setpoint Source: For a generator system there are multiple possible sources or inputs for real power demand. This parameter is used to indicate the source that the Generator Control System is actively controlling real power.0000b = ...";
CM_ SG_ 2364753918 RealPowerRampRateSource "Real Power Ramp Rate Source: For a generator system there are multiple possible sources or inputs for real power ramp rates. This parameter is used to indicate the source that the Generator Control System is actively controlling real power ramp rate ...";
CM_ SG_ 2364753918 RealPowerSetpointPercentage "Real Power Setpoint Percentage: Desired real power for the generator control system as a percentage of generator rated power.";
CM_ SG_ 2364753918 RlPwrInrsRmpRtStpnt "Real Power Increase Ramp Rate Setpoint: Real power desired ramp rate that the generator control system will use to increase power.";
CM_ SG_ 2364753918 RlPwrDrsRmpRtStpnt "Real Power Decrease Ramp Rate Setpoint: Real power desired ramp rate that the generator control system will use to decrease power.";
CM_ SG_ 2364753918 PrmrRlPwrAtvStpntOffstSr "Primary Real Power Active Setpoint Offset Source: For a generator system there are multiple possible sources or inputs for real power offsets. This parameter is used to indicate the source that the Generator Control System is actively controlling rea...";
CM_ SG_ 2364753918 PrmrRlPwrOffstRmpRtSr "Primary Real Power Offset Ramp Rate Source: Used to indicate the source that the Generator Control is actively controlling the real power ramp rate offset.000b = None001b = Frequency Sensitive Mode Increase010b = Frequency Sensitive Mode Decrease011b...";
CM_ SG_ 2364753918 RlPwrRmtInptCmpnstnStts "Real Power Remote Input Compensation Status: Indicates when the reactive power remote input compensation is active or inactive. 00b = Inactive01b = Active10b = Error11b = Not available";
CM_ BO_ 2364754174 "Genset Reactive Power";
CM_ SG_ 2364754174 RtvPwrAtvStpntSr "Reactive Power Active Setpoint Source: For a generator system there are multiple possible sources or inputs for reactive power demand. This parameter is used to indicate the source that the Generator Control System is actively controlling reactive po...";
CM_ SG_ 2364754174 ReactivePowerActiveLimitSource "Reactive Power Active Limit Source: For a generator system there are multiple possible sources or inputs that can limit the reactive power limitation. This parameter is used to indicate the source of the Generator Control System reactive power limit....";
CM_ SG_ 2364754174 ReactivePowerSetpoint "Reactive Power Setpoint: Desired reactive power for the generator control system as a percentage of generator rated reactive power.";
CM_ SG_ 2364754174 UtilitySynchronizationStatus "Utility Synchronization Status: For a generator system there are multiple possible statuses that the generator is allowed to synchronize with the electrical utility grid.0000b = Permission granted0001b = Waiting for external signal0010b = Voltage or ...";
CM_ SG_ 2364754174 UtltOprtrRtvPwrStpntSr "Utility Operator Reactive Power Setpoint Source: For a generator system there are several possible sources or inputs for reactive power demand.  This parameter is used to indicate the source requested by the utility operator that that is to actively ...";
CM_ SG_ 2364754174 RtvPwrMdSltnDgtlInpt1Stts "Reactive Power Mode Selection Digital Input 1 Status: For a generator system, there are several possible digital input sources for reactive power demand. This parameter is used to indicate when the digital input 1 of the reactive power mode selection...";
CM_ SG_ 2364754174 RtvPwrMdSltnDgtlInpt2Stts "Reactive Power Mode Selection Digital Input 2 Status: For a generator system, there are several possible digital input sources for reactive power demand. This parameter is used to indicate when the digital input 2 of the reactive power mode selection...";
CM_ SG_ 2364754174 RtvPwrMdSltnDgtlInpt3Stts "Reactive Power Mode Selection Digital Input 3 Status: For a generator system, there are several possible digital input sources for reactive power demand. This parameter is used to indicate when the digital input 3 of the reactive power mode selection...";
CM_ SG_ 2364754174 RtvPwrMdSltnDgtlInpt4Stts "Reactive Power Mode Selection Digital Input 4 Status: For a generator system, there are several possible digital input sources for reactive power demand. This parameter is used to indicate when the digital input 4 of the reactive power mode selection...";
CM_ SG_ 2364754174 RtvPwrCntrlAtLwLdStts "Reactive Power Control at Low Load Status: Indicates when the reactive power control feature is within limits.00b = Not within limits01b = Within limits10b = Error / function disabled11b = Not available";
CM_ SG_ 2364754174 UtilitySynchronizationDelayTime "Utility Synchronization Delay Time: Time before the generator system will attempt to synchronize with the electrical utility grid.";
CM_ SG_ 2364754174 RtvPwrRmtInptCmpnstnStts "Reactive Power Remote Input Compensation Status: Indicates when the reactive power remote input compensation is active or inactive.00b = Inactive01b = Active10b = Error11b = Not available";
CM_ BO_ 2566081022 "Fuel Cell Compartment Information";
CM_ SG_ 2566081022 FlCllEnlsr1HdrgnCnntrtn "Fuel Cell Enclosure 1 Hydrogen Concentration: This parameter indicates the hydrogen concentration measured inside the Fuel Cell Enclosure 1 in the Fuel Cell CompartmentNote: A Fuel Cell Enclosure can contain one or more Fuel Cell Stack.Parameter Spec...";
CM_ SG_ 2566081022 FlCllEnlsr2HdrgnCnntrtn "Fuel Cell Enclosure 2 Hydrogen Concentration: This parameter indicates the hydrogen concentration measured inside the Fuel Cell Enclosure 2 in the Fuel Cell CompartmentNote: A Fuel Cell Enclosure can contain one or more Fuel Cell Stack.Parameter Spec...";
CM_ SG_ 2566081022 FlCllCmprtmntHdrgnCnntrtn "Fuel Cell Compartment Hydrogen Concentration: This parameter indicates the hydrogen concentration measured inside the Fuel Cell Compartment.Note: A Fuel Cell Compartment can contain one or more Fuel Cell Enclosures. See SPN 21336 (Fuel Cell Enclosure...";
CM_ BO_ 2365210878 "Electronic Transmission Controller 15";
CM_ SG_ 2365210878 EltrnTrnsmssnCntrl15Cr "Electronic Transmission Control 15 CRC: The CRC is defined as follows: - Length: 8 bits- Polynomial: x^8+x^5+x^3+x^2+x+1- Initial Value: FFh- Input Data Reflection: Not reflected- Result Data Reflection: Not reflected- XOR value: FFh SAE makes no cla...";
CM_ SG_ 2365210878 EltrnTrnsmssnCntrl15Cntr "Electronic Transmission Control 15 Counter: The message counter is used to detect situations where the transmitting ECU malfunction repeats the same frame all the time. The receiver of the information may use the counter parameter to detect this situ...";
CM_ SG_ 2365210878 TrnsmssnAtNtrlAtRtrnRqstFdk "Transmission Auto-Neutral (Auto-Return) Request Feedback: This parameter reflects the state of SPN 21252 [Transmission Auto-Neutral (Auto-Return) Request] that the transmission is currently acting upon.000b = Responding to: No request001b = Respondin...";
CM_ SG_ 2365210878 TrnsmssnAtNtrlAtRtrnFntnStt "Transmission Auto-Neutral (Auto-Return) Function State: Indicates the state of the Transmission Auto-Neutral (Auto-Return) function in relation to the state indicated in SPN 21253 [Transmission Auto-Neutral (Auto-Return) Request Feedback]. The applic...";
CM_ SG_ 2365210878 LaunchProcessStatus "Launch Process Status: Indicates the status of a propulsion system's process of launching the vehicle from stationary to moving.In the case of a transmission with a clutch, this may be the status of the clutch transitioning between an open state and ...";
CM_ BO_ 2566537726 "Automated Driving System Network Configuration 2";
CM_ SG_ 2566537726 SourceAddressOfAdsController1 "Source Address of ADS Controller 1: This parameter indicates the source address of ADS controller 1 detected by the controller application which is under control of an automated driving system. 254 (FEh) indicates this parameter is supported, but ADS...";
CM_ SG_ 2566537726 ReceivePortOfAdsController1 "Receive Port of ADS Controller 1: This parameter indicates the communication port of the ADS Controller 1.  The identification of each ECU communication port is ECU specific. The correlation of ECU communication port to a physical network connection ...";
CM_ SG_ 2566537726 ReceivePortOfAdsController2 "Receive Port of ADS Controller 2: This parameter indicates the communication port of the ADS Controller 2.  The identification of each ECU communication port is ECU specific. The correlation of ECU communication port to a physical network connection ...";
CM_ SG_ 2566537726 SourceAddressOfAdsController2 "Source Address of ADS Controller 2: This parameter indicates the source address of ADS controller 2 detected by the controller application which is under control of an automated driving system. 254 (FEh) indicates this parameter is supported, but ADS...";
CM_ SG_ 2566537726 SourceAddressOfAdsController3 "Source Address of ADS Controller 3: This parameter indicates the source address of ADS controller 3 detected by the controller application which is under control of an automated driving system. 254 (FEh) indicates this parameter is supported, but ADS...";
CM_ SG_ 2566537726 ReceivePortOfAdsController3 "Receive Port of ADS Controller 3: This parameter indicates the communication port of the ADS Controller 3.  The identification of each ECU communication port is ECU specific. The correlation of ECU communication port to a physical network connection ...";
CM_ SG_ 2566537726 ReceivePortOfAdsController4 "Receive Port of ADS Controller 4: This parameter indicates the communication port of the ADS Controller 4.  The identification of each ECU communication port is ECU specific. The correlation of ECU communication port to a physical network connection ...";
CM_ SG_ 2566537726 SourceAddressOfAdsController4 "Source Address of ADS Controller 4: This parameter indicates the source address of ADS controller 4 detected by the controller application which is under control of an automated driving system. 254 (FEh) indicates this parameter is supported, but ADS...";
CM_ BO_ 2499429374 "Hybrid System Inputs 2";
CM_ SG_ 2499429374 HrdOrEvSstmTtlRgnrtvBrkngLvl "Hybrid or EV System Total Regenerative Braking Level: Indicates the total regenerative braking level requested by the operator. It is expressed as a percent and determined by the ratio of current position to the maximum possible position. The physica...";
CM_ BO_ 2566686206 "Fuel Cell Auxiliary Heater Control";
CM_ SG_ 2566686206 FlCllAxlrHtrMdRqst "Fuel Cell Auxiliary Heater Mode Request: This is the request to activate the fuel cell auxiliary heater.0000b = De-activate fuel cell auxiliary heater0001b = Economy mode0010b = Normal mode0011b = Heater pump up-keep (run the equipment in order to ke...";
CM_ SG_ 2566686206 FlCllAxlrHtrOtptClntTmprtrStpnt "Fuel Cell Auxiliary Heater Output Coolant Temperature Setpoint: This parameter indicates the setpoint temperature of the fuel cell auxiliary heater output coolant (i.e. water in a water heater system.)";
CM_ SG_ 2566686206 FlCllAxlrHtrOtptPwrPrntCmmnd "Fuel Cell Auxiliary Heater Output Power Percent Command: This parameter indicates the commanded fuel cell auxillary heater output power in percentage, relative to the fuel cell auxiliary heater maximum output power. Note: See SPN 21318 (Fuel Cell Aux...";
CM_ BO_ 2566686462 "Fuel Cell Auxiliary Heater Information";
CM_ SG_ 2566686462 FuelCellAuxiliaryHeaterMode "Fuel Cell Auxiliary Heater Mode: Indicates the state of the fuel cell auxiliary heater0000b = Heater not active0001b = Economy mode0010b = Normal mode0011b = Heater pump up-keep   (running the equipment in order to keep it in good condition)0100b = H...";
CM_ SG_ 2566686462 FlCllAxlrHtrOtptPwrPrnt "Fuel Cell Auxiliary Heater Output Power Percent: Indicates the current fuel cell auxiliary heater output power, relative to the fuel cell auxiliary heater maximum output power. Note: See SPN 21315 (Fuel Cell Auxiliary Heater Power Percent Command) fo...";
CM_ SG_ 2566686462 FlCllAxlrHtrOtptClntTmprtr "Fuel Cell Auxiliary Heater Output Coolant Temperature: Indicates the temperature of the fuel cell auxiliary heater output coolant (I.e. water in a water heater system.)";
CM_ SG_ 2566686462 FlCllAxlrHtrInptCrrntLvl "Fuel Cell Auxiliary Heater Input Current level: Indicates the input DC current to the fuel cell auxilary heater.";
CM_ SG_ 2566686462 FlCllAxlrHtrInptVltgLvl "Fuel Cell Auxiliary Heater Input Voltage level: Indicates the input DC voltage to the fuel cell auxilary heater.";
CM_ BO_ 2566686718 "Fuel Cell Coolant Pump 1 Command";
CM_ SG_ 2566686718 FlCllClntPmp1SpdCmmnd "Fuel Cell Coolant Pump 1 Speed Command: The speed commanded to the fuel cell coolant pump 1.Note:  Both Fuel Cell Coolant Pump 1 Speed Command and Fuel Cell Coolant Pump 1 Percent Speed Command cannot be used at the same time.  Always set the unused ...";
CM_ SG_ 2566686718 FlCllClntPmp1PrntSpdCmmnd "Fuel Cell Coolant Pump 1 Percent Speed Command: The speed commanded to the Fuel Cell Coolant Pump 1  in percentage of maximum speed.Note: Both Fuel Cell Coolant Pump 1 Speed Command and Fuel Cell Coolant Pump 1 Percent Speed Command cannot be used at...";
CM_ SG_ 2566686718 FlCllClntPmp1EnlCmmnd "Fuel Cell Coolant Pump 1 Enable Command: Indicates the enable and direction command to the Fuel Cell Coolant Pump 1.00b = Motor Off01b = Motor On Normal/Default Direction10b = Motor On Reverse Direction11b = Don't Care/Take no action";
CM_ BO_ 2566686974 "Fuel Cell Coolant Pump 2 Command";
CM_ SG_ 2566686974 FlCllClntPmp2SpdCmmnd "Fuel Cell Coolant Pump 2 Speed Command: The speed commanded to the Fuel Cell Coolant Pump 2.Note:  Both Fuel Cell Coolant Pump 2 Speed Command and Fuel Cell Coolant Pump 2 Percent Speed Command cannot be used at the same time.  Always set the unused ...";
CM_ SG_ 2566686974 FlCllClntPmp2PrntSpdCmmnd "Fuel Cell Coolant Pump 2 Percent Speed Command: The speed commanded to the Fuel Cell Coolant Pump 2  in percentage of maximum speed.Note:  Both Fuel Cell Coolant Pump 2 Speed Command and Fuel Cell Coolant Pump 2 Percent Speed Command cannot be used a...";
CM_ SG_ 2566686974 FlCllClntPmp2EnlCmmnd "Fuel Cell Coolant Pump 2 Enable Command: Indicates the enable and direction command to the Fuel Cell Coolant Pump 2.00b = Motor Off01b = Motor On Normal/Default Direction10b = Motor On Reverse Direction11b = Don't Care/Take no action";
CM_ BO_ 2566687230 "Fuel Cell Coolant Pump 1 Status";
CM_ SG_ 2566687230 FuelCellCoolantPump1Speed "Fuel Cell Coolant Pump 1 Speed: Indicates the speed of the Fuel Cell Coolant Pump 1.";
CM_ SG_ 2566687230 FlCllClntPmp1InptVltg "Fuel Cell Coolant Pump 1 Input Voltage: Indicates the input DC voltage to the Fuel Cell Coolant pump 1.";
CM_ SG_ 2566687230 FlCllClntPmp1InptCrrnt "Fuel Cell Coolant Pump 1 Input Current: Indicates the input DC current to the Fuel Cell Coolant pump 1.";
CM_ SG_ 2566687230 FlCllClntPmp1EnlStts "Fuel Cell Coolant Pump 1 Enable Status: Indicates the enable and direction status of the Fuel Cell Coolant Pump 1 system or component.00b = Motor Off01b = Motor On - Normal, Forward, or Default Direction10b = Motor On - Reverse Direction11b = Not ava...";
CM_ BO_ 2566687486 "Fuel Cell Coolant Pump 2 Status";
CM_ SG_ 2566687486 FuelCellCoolantPump2Speed "Fuel Cell Coolant Pump 2 Speed: Indicates the speed of the Fuel Cell Coolant Pump 2.";
CM_ SG_ 2566687486 FlCllClntPmp2InptVltg "Fuel Cell Coolant Pump 2 Input Voltage: Indicates the input DC voltage to the Fuel Cell Coolant pump 2.";
CM_ SG_ 2566687486 FlCllClntPmp2InptCrrnt "Fuel Cell Coolant Pump 2 Input Current: This parameter indicates the input DC current to the Fuel Cell Coolant pump 2.";
CM_ SG_ 2566687486 FlCllClntPmp2EnlStts "Fuel Cell Coolant Pump 2 Enable Status: Indicates the enable and direction status of the Fuel Cell Coolant Pump 2 system or component.00b = Motor Off01b = Motor On - Normal, Forward, or Default Direction10b = Motor On - Reverse Direction11b = Not ava...";
CM_ BO_ 2364754686 "Genset Real Power Setpoint Demand";
CM_ SG_ 2364754686 GnrtrRlLdCntrlBsLdStpnt "Generator Real Load Control Base Load Setpoint: The desired real power base load setpoint as a percentage of generator rated power.";
CM_ SG_ 2364754686 ThrdPrtOprtrRlPwrStpnt "Third Party Operator Real Power Setpoint: The desired third party operator real power setpoint as a percentage of generator rated power.";
CM_ SG_ 2364754686 UtltOprtrRlPwrPrntgStpnt "Utility Operator Real Power Percentage Setpoint: The desired utility operator real power setpoint as a percentage of generator rated power.";
CM_ SG_ 2364754686 ThrdPrtOprtrRlPwrStts "Third Party Operator Real Power Status: Indicates when the third party operator real power is controlling the generator output power.00b = Not Actively Controlling01b = Actively Controlling10b = Error11b = Not available";
CM_ SG_ 2364754686 UtilityOperatorRealPowerStatus "Utility Operator Real Power Status: Indicates when the utility operator real power is controlling the generator output power.00b = Not Actively Controlling01b = Actively Controlling10b = Error11b = Not available";
CM_ SG_ 2364754686 ThrdPrtOprtrRlPwrEnlStts "Third Party Operator Real Power Enable Status: Indicates when the third party operator real power input status is enabled.00b = Disabled01b = Enabled10b = Error11b = Not available";
CM_ SG_ 2364754686 UtltOprtrRlPwrEnlStts "Utility Operator Real Power Enable Status: Indicates when the utility operator real power input status is enabled.00b = Disabled01b = Enabled10b = Error11b = Not available";
CM_ BO_ 2364754942 "Genset Real Power Control 2";
CM_ SG_ 2364754942 DsrdSndrFrqnCntrlRlPwrOffst "Desired Secondary Frequency Control Real Power Offset: Desired generator real power offset based on the real power demand by the secondary frequency control.";
CM_ SG_ 2364754942 IntgrlLlFrqnCntrlRlPwrOffst "Integral Local Frequency Control Real Power Offset: Desired generator real power offset based on the real power demand by the integral local frequency control.";
CM_ SG_ 2364754942 SecondaryFrequencyControlStatus "Secondary Frequency Control Status: Indicates when the secondary frequency control is active.00b = Inactive01b = Active10b = Error11b = Not available";
CM_ SG_ 2364754942 IntgrlLlFrqnCntrlStts "Integral Local Frequency Control Status: Indicates when the integral local frequency control is active00b = Inactive01b = Active10b = Error11b = Not available";
CM_ SG_ 2364754942 ItLFqCtOSdFqCtStts "Integral Local Frequency Control or Secondary Frequency Control Status: Indicates when the integral local frequency control or the secondary frequency control function are enabled.00b = Disabled01b = Enabled10b = Error11b = Not available";
CM_ SG_ 2364754942 IntgrlLlFrqnCntrlRstStts "Integral Local Frequency Control Reset Status: Indicates when a reset of the offset of the integral local frequency control is requested.00b = Reset not requested01b = Reset requested10b = Error11b = Not Available";
CM_ SG_ 2364754942 RealPowerReversionStatus "Real Power Reversion Status: Indicates when the real power reversion is active.00b = Inactive01b = Active10b = Error11b = Not available";
CM_ SG_ 2364754942 RlPwrAndRtvPwrRvrsnStts "Real Power and Reactive Power Reversion Status: Indicates real power and reactive power reversion status. 00b = Inactive01b = Active10b = Error11b = Not available";
CM_ SG_ 2364754942 SndrRlPwrAtvStpntOffstSr "Secondary Real Power Active Setpoint Offset Source: Indicates when the secondary frequency control or the integral local frequency control are controlling the real power offset.00b = Integral Local Frequency Regulation01b = Secondary Regulation10b = ...";
CM_ SG_ 2364754942 SndrRlPwrOffstRmpRtSr "Secondary Real Power Offset Ramp Rate Source: Indicates when the secondary frequency control or the integral local frequency control are controlling the real power offset ramp rate.00b = Integral Local Frequency Regulation01b = Secondary Regulation10...";
CM_ SG_ 2364754942 ReactivePowerReversionStatus "Reactive Power Reversion Status: Indicates when the reactive power reversion is active or inactive. 00b = Inactive01b = Active10b = Error11b = Not available";
CM_ BO_ 2364755198 "High Voltage Energy Storage Pack 1 Data 12";
CM_ SG_ 2364755198 Hvsp1AvllDshrgPwrExtnddRng "HVESP1 Available Discharge Power (Extended Range): The rate at which this High Voltage Energy Storage Pack instance can currently provide energy for propulsion or other uses.This parameter is for one of multiple packs in an HVESS. If there is only on...";
CM_ SG_ 2364755198 Hvsp1AvllChrgPwrExtnddRng "HVESP1 Available Charge Power (Extended Range): The rate at which this High Voltage Energy Storage Pack instance can currently receive energy from a regenerative or recharging system.This parameter is for one of multiple packs in an HVESS. If there i...";
CM_ SG_ 2364755198 Hvesp1VoltageLevelExtendedRange "HVESP1 Voltage Level (Extended Range): The voltage level of this High Voltage Energy Storage Pack instance. This parameter should be synchronized with SPN 22361 (HVESP1 Current (Extended Range)) such that a realized power value can be calculated. If ...";
CM_ SG_ 2364755198 Hvesp1CurrentExtendedRange "HVESP1 Current (Extended Range): The current in or out of this High Voltage Energy Storage Pack instance. This parameter should be synchronized with SPN 22360 (HVESP1 Voltage Level (Extended Range)) such that a realized power value can be calculated....";
CM_ BO_ 2364755454 "High Voltage Energy Storage Pack 1 Data 13";
CM_ SG_ 2364755454 Hvsp1MxIsttsDsCtLtExtddR "HVESP1 Maximum Instantaneous Discharge Current Limit (Extended Range): The maximum instantaneous current flow limit out of this High Voltage Energy Storage Pack instance. This parameter is defined from the high voltage energy storage pack's point of ...";
CM_ SG_ 2364755454 Hvsp1MxIsttsCCtLtExtddR "HVESP1 Maximum Instantaneous Charge Current Limit (Extended Range): The maximum instantaneous current flow limit into this High Voltage Energy Storage Pack instance. This parameter is defined from the high voltage energy storage pack's point of view ...";
CM_ SG_ 2364755454 Hvsp1NmnlDshrgCrrntLmt "HVESP1 Nominal Discharge Current Limit: The nominal current flow limit out of the High Voltage Energy Storage Pack instance. This limit is a preferred boundary for normal operation. Operating within this limit reduces negative impacts on battery lif...";
CM_ SG_ 2364755454 Hvesp1NominalChargeCurrentLimit "HVESP1 Nominal Charge Current Limit: The nominal current flow limit into the High Voltage Energy Storage Pack instance. This limit is a preferred boundary for normal operation. Operating within this limit reduces negative impacts on battery life or ...";
CM_ BO_ 2364755710 "High Voltage Energy Storage Pack 2 Data 12";
CM_ SG_ 2364755710 Hvsp2AvllDshrgPwrExtnddRng "HVESP2 Available Discharge Power (Extended Range): The rate at which this High Voltage Energy Storage Pack instance can currently provide energy for propulsion or other uses.This parameter is for one of multiple packs in an HVESS. If there is only on...";
CM_ SG_ 2364755710 Hvsp2AvllChrgPwrExtnddRng "HVESP2 Available Charge Power (Extended Range): The rate at which this High Voltage Energy Storage Pack instance can currently receive energy from a regenerative or recharging system.This parameter is for one of multiple packs in an HVESS. If there i...";
CM_ SG_ 2364755710 Hvesp2VoltageLevelExtendedRange "HVESP2 Voltage Level (Extended Range): The voltage level of this High Voltage Energy Storage Pack instance. This parameter should be synchronized with SPN 22383 (HVESP2 Current (Extended Range)) such that a realized power value can be calculated. If ...";
CM_ SG_ 2364755710 Hvesp2CurrentExtendedRange "HVESP2 Current (Extended Range): The current in or out of this High Voltage Energy Storage Pack instance. This parameter should be synchronized with SPN 22382 (HVESP2 Voltage Level (Extended Range)) such that a realized power value can be calculated....";
CM_ BO_ 2364755966 "High Voltage Energy Storage Pack 2 Data 13";
CM_ SG_ 2364755966 Hvsp2MxIsttsDsCtLtExtddR "HVESP2 Maximum Instantaneous Discharge Current Limit (Extended Range): The maximum instantaneous current flow limit out of this High Voltage Energy Storage Pack instance. This parameter is defined from the high voltage energy storage pack's point of ...";
CM_ SG_ 2364755966 Hvsp2MxIsttsCCtLtExtddR "HVESP2 Maximum Instantaneous Charge Current Limit (Extended Range): The maximum instantaneous current flow limit into this High Voltage Energy Storage Pack instance. This parameter is defined from the high voltage energy storage pack's point of view ...";
CM_ SG_ 2364755966 Hvsp2NmnlDshrgCrrntLmt "HVESP2 Nominal Discharge Current Limit: The nominal current flow limit out of the High Voltage Energy Storage Pack instance. This limit is a preferred boundary for normal operation. Operating within this limit reduces negative impacts on battery lif...";
CM_ SG_ 2364755966 Hvesp2NominalChargeCurrentLimit "HVESP2 Nominal Charge Current Limit: The nominal current flow limit into the High Voltage Energy Storage Pack instance. This limit is a preferred boundary for normal operation. Operating within this limit reduces negative impacts on battery life or ...";
CM_ BO_ 2364756222 "High Voltage Energy Storage Pack 3 Data 12";
CM_ SG_ 2364756222 Hvsp3AvllDshrgPwrExtnddRng "HVESP3 Available Discharge Power (Extended Range): The rate at which this High Voltage Energy Storage Pack instance can currently provide energy for propulsion or other uses.This parameter is for one of multiple packs in an HVESS. If there is only on...";
CM_ SG_ 2364756222 Hvsp3AvllChrgPwrExtnddRng "HVESP3 Available Charge Power (Extended Range): The rate at which this High Voltage Energy Storage Pack instance can currently receive energy from a regenerative or recharging system.This parameter is for one of multiple packs in an HVESS. If there i...";
CM_ SG_ 2364756222 Hvesp3VoltageLevelExtendedRange "HVESP3 Voltage Level (Extended Range): The voltage level of this High Voltage Energy Storage Pack instance. This parameter should be synchronized with SPN 22405 (HVESP3 Current (Extended Range)) such that a realized power value can be calculated. If ...";
CM_ SG_ 2364756222 Hvesp3CurrentExtendedRange "HVESP3 Current (Extended Range): The current in or out of this High Voltage Energy Storage Pack instance. This parameter should be synchronized with SPN 22404 (HVESP3 Voltage Level (Extended Range)) such that a realized power value can be calculated....";
CM_ BO_ 2364756478 "High Voltage Energy Storage Pack 3 Data 13";
CM_ SG_ 2364756478 Hvsp3MxIsttsDsCtLtExtddR "HVESP3 Maximum Instantaneous Discharge Current Limit (Extended Range): The maximum instantaneous current flow limit out of this High Voltage Energy Storage Pack instance. This parameter is defined from the high voltage energy storage pack's point of ...";
CM_ SG_ 2364756478 Hvsp3MxIsttsCCtLtExtddR "HVESP3 Maximum Instantaneous Charge Current Limit (Extended Range): The maximum instantaneous current flow limit into this High Voltage Energy Storage Pack instance. This parameter is defined from the high voltage energy storage pack's point of view ...";
CM_ SG_ 2364756478 Hvsp3NmnlDshrgCrrntLmt "HVESP3 Nominal Discharge Current Limit: The nominal current flow limit out of the High Voltage Energy Storage Pack instance. This limit is a preferred boundary for normal operation. Operating within this limit reduces negative impacts on battery lif...";
CM_ SG_ 2364756478 Hvesp3NominalChargeCurrentLimit "HVESP3 Nominal Charge Current Limit: The nominal current flow limit into the High Voltage Energy Storage Pack instance. This limit is a preferred boundary for normal operation. Operating within this limit reduces negative impacts on battery life or ...";
CM_ BO_ 2364756734 "High Voltage Energy Storage Pack 4 Data 12";
CM_ SG_ 2364756734 Hvsp4AvllDshrgPwrExtnddRng "HVESP4 Available Discharge Power (Extended Range): The rate at which this High Voltage Energy Storage Pack instance can currently provide energy for propulsion or other uses.This parameter is for one of multiple packs in an HVESS. If there is only on...";
CM_ SG_ 2364756734 Hvsp4AvllChrgPwrExtnddRng "HVESP4 Available Charge Power (Extended Range): The rate at which this High Voltage Energy Storage Pack instance can currently receive energy from a regenerative or recharging system.This parameter is for one of multiple packs in an HVESS. If there i...";
CM_ SG_ 2364756734 Hvesp4VoltageLevelExtendedRange "HVESP4 Voltage Level (Extended Range): The voltage level of this High Voltage Energy Storage Pack instance. This parameter should be synchronized with SPN 22427 (HVESP4 Current (Extended Range)) such that a realized power value can be calculated. If ...";
CM_ SG_ 2364756734 Hvesp4CurrentExtendedRange "HVESP4 Current (Extended Range): The current in or out of this High Voltage Energy Storage Pack instance. This parameter should be synchronized with SPN 22426 (HVESP4 Voltage Level (Extended Range)) such that a realized power value can be calculated....";
BA_DEF_ SG_  "SPN" INT 0 524287;
BA_DEF_ BO_  "VFrameFormat" ENUM  "StandardCAN","ExtendedCAN","reserved","J1939PG";
BA_DEF_DEF_  "SPN" 0;
BA_DEF_DEF_  "VFrameFormat" "J1939PG";
BA_ "SPN" SG_ 2633663742 Hvesp11StateOfHealth 15395;
BA_ "SPN" SG_ 2633663742 Hvsp11CnttrOpnUndrLdCnt 15396;
BA_ "SPN" SG_ 2633663742 Hvesp11TotalEnergyThroughput 15397;
BA_ "SPN" SG_ 2633663742 Hvesp11TotalAccumulatedCharge 15398;
BA_ "SPN" SG_ 2633663742 Hvesp11TotalLifetimeEnergyInput 15399;
BA_ "SPN" SG_ 2633663742 Hvsp11TtlLftmEnrgOtpt 15400;
BA_ "SPN" SG_ 2566555134 Hvesp11NominalVoltage 15401;
BA_ "SPN" SG_ 2566555134 Hvsp11RmmnddMnmmOprtngVltg 15402;
BA_ "SPN" SG_ 2566555134 Hvsp11RmmnddMxmmOprtngVltg 15403;
BA_ "SPN" SG_ 2566555134 Hvsp11RmmnddMnmmSttOfChrg 15404;
BA_ "SPN" SG_ 2566555134 Hvsp11RmmnddMxmmSttOfChrg 15405;
BA_ "SPN" SG_ 2566555134 Hvsp11RmmnddMxmmOprtngTmprtr 15406;
BA_ "SPN" SG_ 2566555134 Hvsp11RmmnddMnmmOprtngTmprtr 15407;
BA_ "SPN" SG_ 2566555134 Hvesp11CellMaximumVoltageLimit 15408;
BA_ "SPN" SG_ 2566555134 Hvesp11CellMinimumVoltageLimit 15409;
BA_ "SPN" SG_ 2566555134 Hvesp11NominalRatedCapacity 15410;
BA_ "SPN" SG_ 2633664254 Hvesp12StateOfHealth 15537;
BA_ "SPN" SG_ 2633664254 Hvsp12CnttrOpnUndrLdCnt 15538;
BA_ "SPN" SG_ 2633664254 Hvesp12TotalEnergyThroughput 15539;
BA_ "SPN" SG_ 2633664254 Hvesp12TotalAccumulatedCharge 15540;
BA_ "SPN" SG_ 2633664254 Hvesp12TotalLifetimeEnergyInput 15541;
BA_ "SPN" SG_ 2633664254 Hvsp12TtlLftmEnrgOtpt 15542;
BA_ "SPN" SG_ 2566555646 Hvesp12NominalVoltage 15543;
BA_ "SPN" SG_ 2566555646 Hvsp12RmmnddMnmmOprtngVltg 15544;
BA_ "SPN" SG_ 2566555646 Hvsp12RmmnddMxmmOprtngVltg 15545;
BA_ "SPN" SG_ 2566555646 Hvsp12RmmnddMnmmSttOfChrg 15546;
BA_ "SPN" SG_ 2566555646 Hvsp12RmmnddMxmmSttOfChrg 15547;
BA_ "SPN" SG_ 2566555646 Hvsp12RmmnddMxmmOprtngTmprtr 15548;
BA_ "SPN" SG_ 2566555646 Hvsp12RmmnddMnmmOprtngTmprtr 15549;
BA_ "SPN" SG_ 2566555646 Hvesp12CellMaximumVoltageLimit 15550;
BA_ "SPN" SG_ 2566555646 Hvesp12CellMinimumVoltageLimit 15551;
BA_ "SPN" SG_ 2566555646 Hvesp12NominalRatedCapacity 15552;
BA_ "SPN" SG_ 2633664766 Hvesp13StateOfHealth 15679;
BA_ "SPN" SG_ 2633664766 Hvsp13CnttrOpnUndrLdCnt 15680;
BA_ "SPN" SG_ 2633664766 Hvesp13TotalEnergyThroughput 15681;
BA_ "SPN" SG_ 2633664766 Hvesp13TotalAccumulatedCharge 15682;
BA_ "SPN" SG_ 2633664766 Hvesp13TotalLifetimeEnergyInput 15683;
BA_ "SPN" SG_ 2633664766 Hvsp13TtlLftmEnrgOtpt 15684;
BA_ "SPN" SG_ 2566556158 Hvesp13NominalVoltage 15685;
BA_ "SPN" SG_ 2566556158 Hvsp13RmmnddMnmmOprtngVltg 15686;
BA_ "SPN" SG_ 2566556158 Hvsp13RmmnddMxmmOprtngVltg 15687;
BA_ "SPN" SG_ 2566556158 Hvsp13RmmnddMnmmSttOfChrg 15688;
BA_ "SPN" SG_ 2566556158 Hvsp13RmmnddMxmmSttOfChrg 15689;
BA_ "SPN" SG_ 2566556158 Hvsp13RmmnddMxmmOprtngTmprtr 15690;
BA_ "SPN" SG_ 2566556158 Hvsp13RmmnddMnmmOprtngTmprtr 15691;
BA_ "SPN" SG_ 2566556158 Hvesp13CellMaximumVoltageLimit 15692;
BA_ "SPN" SG_ 2566556158 Hvesp13CellMinimumVoltageLimit 15693;
BA_ "SPN" SG_ 2566556158 Hvesp13NominalRatedCapacity 15694;
BA_ "SPN" SG_ 2633665278 Hvesp14StateOfHealth 15821;
BA_ "SPN" SG_ 2633665278 Hvsp14CnttrOpnUndrLdCnt 15822;
BA_ "SPN" SG_ 2633665278 Hvesp14TotalEnergyThroughput 15823;
BA_ "SPN" SG_ 2633665278 Hvesp14TotalAccumulatedCharge 15824;
BA_ "SPN" SG_ 2633665278 Hvesp14TotalLifetimeEnergyInput 15825;
BA_ "SPN" SG_ 2633665278 Hvsp14TtlLftmEnrgOtpt 15826;
BA_ "SPN" SG_ 2566556670 Hvesp14NominalVoltage 15827;
BA_ "SPN" SG_ 2566556670 Hvsp14RmmnddMnmmOprtngVltg 15828;
BA_ "SPN" SG_ 2566556670 Hvsp14RmmnddMxmmOprtngVltg 15829;
BA_ "SPN" SG_ 2566556670 Hvsp14RmmnddMnmmSttOfChrg 15830;
BA_ "SPN" SG_ 2566556670 Hvsp14RmmnddMxmmSttOfChrg 15831;
BA_ "SPN" SG_ 2566556670 Hvsp14RmmnddMxmmOprtngTmprtr 15832;
BA_ "SPN" SG_ 2566556670 Hvsp14RmmnddMnmmOprtngTmprtr 15833;
BA_ "SPN" SG_ 2566556670 Hvesp14CellMaximumVoltageLimit 15834;
BA_ "SPN" SG_ 2566556670 Hvesp14CellMinimumVoltageLimit 15835;
BA_ "SPN" SG_ 2566556670 Hvesp14NominalRatedCapacity 15836;
BA_ "SPN" SG_ 2633665790 Hvesp15StateOfHealth 15963;
BA_ "SPN" SG_ 2633665790 Hvsp15CnttrOpnUndrLdCnt 15964;
BA_ "SPN" SG_ 2633665790 Hvesp15TotalEnergyThroughput 15965;
BA_ "SPN" SG_ 2633665790 Hvesp15TotalAccumulatedCharge 15966;
BA_ "SPN" SG_ 2633665790 Hvesp15TotalLifetimeEnergyInput 15967;
BA_ "SPN" SG_ 2633665790 Hvsp15TtlLftmEnrgOtpt 15968;
BA_ "SPN" SG_ 2566557182 Hvesp15NominalVoltage 15969;
BA_ "SPN" SG_ 2566557182 Hvsp15RmmnddMnmmOprtngVltg 15970;
BA_ "SPN" SG_ 2566557182 Hvsp15RmmnddMxmmOprtngVltg 15971;
BA_ "SPN" SG_ 2566557182 Hvsp15RmmnddMnmmSttOfChrg 15972;
BA_ "SPN" SG_ 2566557182 Hvsp15RmmnddMxmmSttOfChrg 15973;
BA_ "SPN" SG_ 2566557182 Hvsp15RmmnddMxmmOprtngTmprtr 15974;
BA_ "SPN" SG_ 2566557182 Hvsp15RmmnddMnmmOprtngTmprtr 15975;
BA_ "SPN" SG_ 2566557182 Hvesp15CellMaximumVoltageLimit 15976;
BA_ "SPN" SG_ 2566557182 Hvesp15CellMinimumVoltageLimit 15977;
BA_ "SPN" SG_ 2566557182 Hvesp15NominalRatedCapacity 15978;
BA_ "SPN" SG_ 2633666302 Hvesp16StateOfHealth 16105;
BA_ "SPN" SG_ 2633666302 Hvsp16CnttrOpnUndrLdCnt 16106;
BA_ "SPN" SG_ 2633666302 Hvesp16TotalEnergyThroughput 16107;
BA_ "SPN" SG_ 2633666302 Hvesp16TotalAccumulatedCharge 16108;
BA_ "SPN" SG_ 2633666302 Hvesp16TotalLifetimeEnergyInput 16109;
BA_ "SPN" SG_ 2633666302 Hvsp16TtlLftmEnrgOtpt 16110;
BA_ "SPN" SG_ 2566557694 Hvesp16NominalVoltage 16111;
BA_ "SPN" SG_ 2566557694 Hvsp16RmmnddMnmmOprtngVltg 16112;
BA_ "SPN" SG_ 2566557694 Hvsp16RmmnddMxmmOprtngVltg 16113;
BA_ "SPN" SG_ 2566557694 Hvsp16RmmnddMnmmSttOfChrg 16114;
BA_ "SPN" SG_ 2566557694 Hvsp16RmmnddMxmmSttOfChrg 16115;
BA_ "SPN" SG_ 2566557694 Hvsp16RmmnddMxmmOprtngTmprtr 16116;
BA_ "SPN" SG_ 2566557694 Hvsp16RmmnddMnmmOprtngTmprtr 16117;
BA_ "SPN" SG_ 2566557694 Hvesp16CellMaximumVoltageLimit 16118;
BA_ "SPN" SG_ 2566557694 Hvesp16CellMinimumVoltageLimit 16119;
BA_ "SPN" SG_ 2566557694 Hvesp16NominalRatedCapacity 16120;
BA_ "SPN" SG_ 2633666814 Hvesp17StateOfHealth 16247;
BA_ "SPN" SG_ 2633666814 Hvsp17CnttrOpnUndrLdCnt 16248;
BA_ "SPN" SG_ 2633666814 Hvesp17TotalEnergyThroughput 16249;
BA_ "SPN" SG_ 2633666814 Hvesp17TotalAccumulatedCharge 16250;
BA_ "SPN" SG_ 2633666814 Hvesp17TotalLifetimeEnergyInput 16251;
BA_ "SPN" SG_ 2633666814 Hvsp17TtlLftmEnrgOtpt 16252;
BA_ "SPN" SG_ 2566558206 Hvesp17NominalVoltage 16253;
BA_ "SPN" SG_ 2566558206 Hvsp17RmmnddMnmmOprtngVltg 16254;
BA_ "SPN" SG_ 2566558206 Hvsp17RmmnddMxmmOprtngVltg 16255;
BA_ "SPN" SG_ 2566558206 Hvsp17RmmnddMnmmSttOfChrg 16256;
BA_ "SPN" SG_ 2566558206 Hvsp17RmmnddMxmmSttOfChrg 16257;
BA_ "SPN" SG_ 2566558206 Hvsp17RmmnddMxmmOprtngTmprtr 16258;
BA_ "SPN" SG_ 2566558206 Hvsp17RmmnddMnmmOprtngTmprtr 16259;
BA_ "SPN" SG_ 2566558206 Hvesp17CellMaximumVoltageLimit 16260;
BA_ "SPN" SG_ 2566558206 Hvesp17CellMinimumVoltageLimit 16261;
BA_ "SPN" SG_ 2566558206 Hvesp17NominalRatedCapacity 16262;
BA_ "SPN" SG_ 2633667326 Hvesp18StateOfHealth 16389;
BA_ "SPN" SG_ 2633667326 Hvsp18CnttrOpnUndrLdCnt 16390;
BA_ "SPN" SG_ 2633667326 Hvesp18TotalEnergyThroughput 16391;
BA_ "SPN" SG_ 2633667326 Hvesp18TotalAccumulatedCharge 16392;
BA_ "SPN" SG_ 2633667326 Hvesp18TotalLifetimeEnergyInput 16393;
BA_ "SPN" SG_ 2633667326 Hvsp18TtlLftmEnrgOtpt 16394;
BA_ "SPN" SG_ 2566558718 Hvesp18NominalVoltage 16395;
BA_ "SPN" SG_ 2566558718 Hvsp18RmmnddMnmmOprtngVltg 16396;
BA_ "SPN" SG_ 2566558718 Hvsp18RmmnddMxmmOprtngVltg 16397;
BA_ "SPN" SG_ 2566558718 Hvsp18RmmnddMnmmSttOfChrg 16398;
BA_ "SPN" SG_ 2566558718 Hvsp18RmmnddMxmmSttOfChrg 16399;
BA_ "SPN" SG_ 2566558718 Hvsp18RmmnddMxmmOprtngTmprtr 16400;
BA_ "SPN" SG_ 2566558718 Hvsp18RmmnddMnmmOprtngTmprtr 16401;
BA_ "SPN" SG_ 2566558718 Hvesp18CellMaximumVoltageLimit 16402;
BA_ "SPN" SG_ 2566558718 Hvesp18CellMinimumVoltageLimit 16403;
BA_ "SPN" SG_ 2566558718 Hvesp18NominalRatedCapacity 16404;
BA_ "SPN" SG_ 2633667838 Hvesp19StateOfHealth 16531;
BA_ "SPN" SG_ 2633667838 Hvsp19CnttrOpnUndrLdCnt 16532;
BA_ "SPN" SG_ 2633667838 Hvesp19TotalEnergyThroughput 16533;
BA_ "SPN" SG_ 2633667838 Hvesp19TotalAccumulatedCharge 16534;
BA_ "SPN" SG_ 2633667838 Hvesp19TotalLifetimeEnergyInput 16535;
BA_ "SPN" SG_ 2633667838 Hvsp19TtlLftmEnrgOtpt 16536;
BA_ "SPN" SG_ 2566559230 Hvesp19NominalVoltage 16537;
BA_ "SPN" SG_ 2566559230 Hvsp19RmmnddMnmmOprtngVltg 16538;
BA_ "SPN" SG_ 2566559230 Hvsp19RmmnddMxmmOprtngVltg 16539;
BA_ "SPN" SG_ 2566559230 Hvsp19RmmnddMnmmSttOfChrg 16540;
BA_ "SPN" SG_ 2566559230 Hvsp19RmmnddMxmmSttOfChrg 16541;
BA_ "SPN" SG_ 2566559230 Hvsp19RmmnddMxmmOprtngTmprtr 16542;
BA_ "SPN" SG_ 2566559230 Hvsp19RmmnddMnmmOprtngTmprtr 16543;
BA_ "SPN" SG_ 2566559230 Hvesp19CellMaximumVoltageLimit 16544;
BA_ "SPN" SG_ 2566559230 Hvesp19CellMinimumVoltageLimit 16545;
BA_ "SPN" SG_ 2566559230 Hvesp19NominalRatedCapacity 16546;
BA_ "SPN" SG_ 2633668350 Hvesp20StateOfHealth 16673;
BA_ "SPN" SG_ 2633668350 Hvsp20CnttrOpnUndrLdCnt 16674;
BA_ "SPN" SG_ 2633668350 Hvesp20TotalEnergyThroughput 16675;
BA_ "SPN" SG_ 2633668350 Hvesp20TotalAccumulatedCharge 16676;
BA_ "SPN" SG_ 2633668350 Hvesp20TotalLifetimeEnergyInput 16677;
BA_ "SPN" SG_ 2633668350 Hvsp20TtlLftmEnrgOtpt 16678;
BA_ "SPN" SG_ 2566559742 Hvesp20NominalVoltage 16679;
BA_ "SPN" SG_ 2566559742 Hvsp20RmmnddMnmmOprtngVltg 16680;
BA_ "SPN" SG_ 2566559742 Hvsp20RmmnddMxmmOprtngVltg 16681;
BA_ "SPN" SG_ 2566559742 Hvsp20RmmnddMnmmSttOfChrg 16682;
BA_ "SPN" SG_ 2566559742 Hvsp20RmmnddMxmmSttOfChrg 16683;
BA_ "SPN" SG_ 2566559742 Hvsp20RmmnddMxmmOprtngTmprtr 16684;
BA_ "SPN" SG_ 2566559742 Hvsp20RmmnddMnmmOprtngTmprtr 16685;
BA_ "SPN" SG_ 2566559742 Hvesp20CellMaximumVoltageLimit 16686;
BA_ "SPN" SG_ 2566559742 Hvesp20CellMinimumVoltageLimit 16687;
BA_ "SPN" SG_ 2566559742 Hvesp20NominalRatedCapacity 16688;
BA_ "SPN" SG_ 2633668862 Hvesp21StateOfHealth 16815;
BA_ "SPN" SG_ 2633668862 Hvsp21CnttrOpnUndrLdCnt 16816;
BA_ "SPN" SG_ 2633668862 Hvesp21TotalEnergyThroughput 16817;
BA_ "SPN" SG_ 2633668862 Hvesp21TotalAccumulatedCharge 16818;
BA_ "SPN" SG_ 2633668862 Hvesp21TotalLifetimeEnergyInput 16819;
BA_ "SPN" SG_ 2633668862 Hvsp21TtlLftmEnrgOtpt 16820;
BA_ "SPN" SG_ 2566560254 Hvesp21NominalVoltage 16821;
BA_ "SPN" SG_ 2566560254 Hvsp21RmmnddMnmmOprtngVltg 16822;
BA_ "SPN" SG_ 2566560254 Hvsp21RmmnddMxmmOprtngVltg 16823;
BA_ "SPN" SG_ 2566560254 Hvsp21RmmnddMnmmSttOfChrg 16824;
BA_ "SPN" SG_ 2566560254 Hvsp21RmmnddMxmmSttOfChrg 16825;
BA_ "SPN" SG_ 2566560254 Hvsp21RmmnddMxmmOprtngTmprtr 16826;
BA_ "SPN" SG_ 2566560254 Hvsp21RmmnddMnmmOprtngTmprtr 16827;
BA_ "SPN" SG_ 2566560254 Hvesp21CellMaximumVoltageLimit 16828;
BA_ "SPN" SG_ 2566560254 Hvesp21CellMinimumVoltageLimit 16829;
BA_ "SPN" SG_ 2566560254 Hvesp21NominalRatedCapacity 16830;
BA_ "SPN" SG_ 2633669374 Hvesp22StateOfHealth 16957;
BA_ "SPN" SG_ 2633669374 Hvsp22CnttrOpnUndrLdCnt 16958;
BA_ "SPN" SG_ 2633669374 Hvesp22TotalEnergyThroughput 16959;
BA_ "SPN" SG_ 2633669374 Hvesp22TotalAccumulatedCharge 16960;
BA_ "SPN" SG_ 2633669374 Hvesp22TotalLifetimeEnergyInput 16961;
BA_ "SPN" SG_ 2633669374 Hvsp22TtlLftmEnrgOtpt 16962;
BA_ "SPN" SG_ 2566560766 Hvesp22NominalVoltage 16963;
BA_ "SPN" SG_ 2566560766 Hvsp22RmmnddMnmmOprtngVltg 16964;
BA_ "SPN" SG_ 2566560766 Hvsp22RmmnddMxmmOprtngVltg 16965;
BA_ "SPN" SG_ 2566560766 Hvsp22RmmnddMnmmSttOfChrg 16966;
BA_ "SPN" SG_ 2566560766 Hvsp22RmmnddMxmmSttOfChrg 16967;
BA_ "SPN" SG_ 2566560766 Hvsp22RmmnddMxmmOprtngTmprtr 16968;
BA_ "SPN" SG_ 2566560766 Hvsp22RmmnddMnmmOprtngTmprtr 16969;
BA_ "SPN" SG_ 2566560766 Hvesp22CellMaximumVoltageLimit 16970;
BA_ "SPN" SG_ 2566560766 Hvesp22CellMinimumVoltageLimit 16971;
BA_ "SPN" SG_ 2566560766 Hvesp22NominalRatedCapacity 16972;
BA_ "SPN" SG_ 2633669886 Hvesp23StateOfHealth 17099;
BA_ "SPN" SG_ 2633669886 Hvsp23CnttrOpnUndrLdCnt 17100;
BA_ "SPN" SG_ 2633669886 Hvesp23TotalEnergyThroughput 17101;
BA_ "SPN" SG_ 2633669886 Hvesp23TotalAccumulatedCharge 17102;
BA_ "SPN" SG_ 2633669886 Hvesp23TotalLifetimeEnergyInput 17103;
BA_ "SPN" SG_ 2633669886 Hvsp23TtlLftmEnrgOtpt 17104;
BA_ "SPN" SG_ 2566561278 Hvesp23NominalVoltage 17105;
BA_ "SPN" SG_ 2566561278 Hvsp23RmmnddMnmmOprtngVltg 17106;
BA_ "SPN" SG_ 2566561278 Hvsp23RmmnddMxmmOprtngVltg 17107;
BA_ "SPN" SG_ 2566561278 Hvsp23RmmnddMnmmSttOfChrg 17108;
BA_ "SPN" SG_ 2566561278 Hvsp23RmmnddMxmmSttOfChrg 17109;
BA_ "SPN" SG_ 2566561278 Hvsp23RmmnddMxmmOprtngTmprtr 17110;
BA_ "SPN" SG_ 2566561278 Hvsp23RmmnddMnmmOprtngTmprtr 17111;
BA_ "SPN" SG_ 2566561278 Hvesp23CellMaximumVoltageLimit 17112;
BA_ "SPN" SG_ 2566561278 Hvesp23CellMinimumVoltageLimit 17113;
BA_ "SPN" SG_ 2566561278 Hvesp23NominalRatedCapacity 17114;
BA_ "SPN" SG_ 2633670398 Hvesp24StateOfHealth 17241;
BA_ "SPN" SG_ 2633670398 Hvsp24CnttrOpnUndrLdCnt 17242;
BA_ "SPN" SG_ 2633670398 Hvesp24TotalEnergyThroughput 17243;
BA_ "SPN" SG_ 2633670398 Hvesp24TotalAccumulatedCharge 17244;
BA_ "SPN" SG_ 2633670398 Hvesp24TotalLifetimeEnergyInput 17245;
BA_ "SPN" SG_ 2633670398 Hvsp24TtlLftmEnrgOtpt 17246;
BA_ "SPN" SG_ 2566561790 Hvesp24NominalVoltage 17247;
BA_ "SPN" SG_ 2566561790 Hvsp24RmmnddMnmmOprtngVltg 17248;
BA_ "SPN" SG_ 2566561790 Hvsp24RmmnddMxmmOprtngVltg 17249;
BA_ "SPN" SG_ 2566561790 Hvsp24RmmnddMnmmSttOfChrg 17250;
BA_ "SPN" SG_ 2566561790 Hvsp24RmmnddMxmmSttOfChrg 17251;
BA_ "SPN" SG_ 2566561790 Hvsp24RmmnddMxmmOprtngTmprtr 17252;
BA_ "SPN" SG_ 2566561790 Hvsp24RmmnddMnmmOprtngTmprtr 17253;
BA_ "SPN" SG_ 2566561790 Hvesp24CellMaximumVoltageLimit 17254;
BA_ "SPN" SG_ 2566561790 Hvesp24CellMinimumVoltageLimit 17255;
BA_ "SPN" SG_ 2566561790 Hvesp24NominalRatedCapacity 17256;
BA_ "SPN" SG_ 2633670910 Hvesp25StateOfHealth 17383;
BA_ "SPN" SG_ 2633670910 Hvsp25CnttrOpnUndrLdCnt 17384;
BA_ "SPN" SG_ 2633670910 Hvesp25TotalEnergyThroughput 17385;
BA_ "SPN" SG_ 2633670910 Hvesp25TotalAccumulatedCharge 17386;
BA_ "SPN" SG_ 2633670910 Hvesp25TotalLifetimeEnergyInput 17387;
BA_ "SPN" SG_ 2633670910 Hvsp25TtlLftmEnrgOtpt 17388;
BA_ "SPN" SG_ 2566562302 Hvesp25NominalVoltage 17389;
BA_ "SPN" SG_ 2566562302 Hvsp25RmmnddMnmmOprtngVltg 17390;
BA_ "SPN" SG_ 2566562302 Hvsp25RmmnddMxmmOprtngVltg 17391;
BA_ "SPN" SG_ 2566562302 Hvsp25RmmnddMnmmSttOfChrg 17392;
BA_ "SPN" SG_ 2566562302 Hvsp25RmmnddMxmmSttOfChrg 17393;
BA_ "SPN" SG_ 2566562302 Hvsp25RmmnddMxmmOprtngTmprtr 17394;
BA_ "SPN" SG_ 2566562302 Hvsp25RmmnddMnmmOprtngTmprtr 17395;
BA_ "SPN" SG_ 2566562302 Hvesp25CellMaximumVoltageLimit 17396;
BA_ "SPN" SG_ 2566562302 Hvesp25CellMinimumVoltageLimit 17397;
BA_ "SPN" SG_ 2566562302 Hvesp25NominalRatedCapacity 17398;
BA_ "SPN" SG_ 2633671422 Hvesp26StateOfHealth 17525;
BA_ "SPN" SG_ 2633671422 Hvsp26CnttrOpnUndrLdCnt 17526;
BA_ "SPN" SG_ 2633671422 Hvesp26TotalEnergyThroughput 17527;
BA_ "SPN" SG_ 2633671422 Hvesp26TotalAccumulatedCharge 17528;
BA_ "SPN" SG_ 2633671422 Hvesp26TotalLifetimeEnergyInput 17529;
BA_ "SPN" SG_ 2633671422 Hvsp26TtlLftmEnrgOtpt 17530;
BA_ "SPN" SG_ 2566562814 Hvesp26NominalVoltage 17531;
BA_ "SPN" SG_ 2566562814 Hvsp26RmmnddMnmmOprtngVltg 17532;
BA_ "SPN" SG_ 2566562814 Hvsp26RmmnddMxmmOprtngVltg 17533;
BA_ "SPN" SG_ 2566562814 Hvsp26RmmnddMnmmSttOfChrg 17534;
BA_ "SPN" SG_ 2566562814 Hvsp26RmmnddMxmmSttOfChrg 17535;
BA_ "SPN" SG_ 2566562814 Hvsp26RmmnddMxmmOprtngTmprtr 17536;
BA_ "SPN" SG_ 2566562814 Hvsp26RmmnddMnmmOprtngTmprtr 17537;
BA_ "SPN" SG_ 2566562814 Hvesp26CellMaximumVoltageLimit 17538;
BA_ "SPN" SG_ 2566562814 Hvesp26CellMinimumVoltageLimit 17539;
BA_ "SPN" SG_ 2566562814 Hvesp26NominalRatedCapacity 17540;
BA_ "SPN" SG_ 2566563070 AdsVehicleSpeedControlCommand 15248;
BA_ "SPN" SG_ 2566563070 AdsVhlSpdCntrlCmmndPrrt 20869;
BA_ "SPN" SG_ 2566563070 Adsc2EmbeddedIntegritySupport 22261;
BA_ "SPN" SG_ 2566563070 Adsc2Counter 22262;
BA_ "SPN" SG_ 2566563070 Adsc2Crc 22263;
BA_ "SPN" SG_ 2566658814 HvssTMtSstItCtTptRqst 20454;
BA_ "SPN" SG_ 2566658814 HvssTMtSstOttCtTptRqst 20455;
BA_ "SPN" SG_ 2566658814 HvssTMtSstCtFwRtRqst 20456;
BA_ "SPN" SG_ 2566658814 HvssThrmlMngmntSstmHtrEnlCmmnd 20457;
BA_ "SPN" SG_ 2566658814 HvssTMtSstCtPpECd 20458;
BA_ "SPN" SG_ 2566658814 HvssTMtSstCpssECd 20459;
BA_ "SPN" SG_ 2365332478 HvssTMtSstCtPpSpdCd 20460;
BA_ "SPN" SG_ 2365332478 HvssTMtSstCtPpPtSpdCd 20461;
BA_ "SPN" SG_ 2365332478 HvssTMtSstCpssSpdCd 20462;
BA_ "SPN" SG_ 2365332478 HvssTMtSstCpssPtSpdCd 20463;
BA_ "SPN" SG_ 2566679038 HvessEstimatedRemainingDistance 15268;
BA_ "SPN" SG_ 2566079486 EltrnPrkBrkPwrUntCntrlArStts 21169;
BA_ "SPN" SG_ 2566079486 EltrnPrkBrkTwdUntCntrlArStts 21170;
BA_ "SPN" SG_ 2566079486 EltrnPrkBrkOpnAntRllAwStts 21171;
BA_ "SPN" SG_ 2566079486 EltrnPrkBrkTrlrBrkRlsStts 21172;
BA_ "SPN" SG_ 2566079486 EltrnPrkBrkPwrUntVhlTp 21173;
BA_ "SPN" SG_ 2566079486 EltrnPrkBrkOprtngMd 21174;
BA_ "SPN" SG_ 2566079486 EtPBTOvdItSvBStts 21175;
BA_ "SPN" SG_ 2566079486 EtPBTOvdItItStts 21176;
BA_ "SPN" SG_ 2566079486 EtPBTOvdItStBtSwtStts 21177;
BA_ "SPN" SG_ 2566079486 EtPBTOvdItD1Stts 21178;
BA_ "SPN" SG_ 2566079486 EtPBTOvdItD2Stts 21179;
BA_ "SPN" SG_ 2566079486 EltrnPrkBrkExhstAtSpdStts 21180;
BA_ "SPN" SG_ 2566079486 ElectronicParkBrakePowerStatus 21181;
BA_ "SPN" SG_ 2566079486 AntiRollAwayTimer 21182;
BA_ "SPN" SG_ 2566079486 EltrnPrkBrkPwrUntSwthStts 21183;
BA_ "SPN" SG_ 2566079486 EltrnPrkBrkTwdUntSwthStts 21184;
BA_ "SPN" SG_ 2566079742 EltrnPrkBrkPwrUntCntrlArPrssr 21185;
BA_ "SPN" SG_ 2566079742 EltrnPrkBrkTwdUntCntrlArPrssr 21186;
BA_ "SPN" SG_ 2566079742 EltrnPrkBrkPwrUntCrtArPrssr 21187;
BA_ "SPN" SG_ 2566079742 EltrnPrkBrkTwdUntCrtArPrssr 21188;
BA_ "SPN" SG_ 2566079742 EtPBExtRqstSstSttPwUtApp 21189;
BA_ "SPN" SG_ 2566079742 EtPBExtRqstSstSttPwUtRs 21190;
BA_ "SPN" SG_ 2566079742 EtPBExtRqstSstSttTwdUtSpp 21191;
BA_ "SPN" SG_ 2566079742 EtPBExtRqstSstSttTwdUtEvt 21192;
BA_ "SPN" SG_ 2566079742 EtPBAtvExtCtMdPwUt 21193;
BA_ "SPN" SG_ 2566079742 EtPBAtvExtCtMdTwdUt 21194;
BA_ "SPN" SG_ 2566079742 EtPBPAtSpdExtBRqstStts 21195;
BA_ "SPN" SG_ 2566079742 EltrnPrkBrkTrnsmssnNtrlRqstStts 21196;
BA_ "SPN" SG_ 2566079742 EtPBAtRAwRqstSstSttIt 21197;
BA_ "SPN" SG_ 2566079742 EtPBAtvExtItAtRAw 21198;
BA_ "SPN" SG_ 2566538494 TripAverageLoadFactor 21166;
BA_ "SPN" SG_ 2566538494 TotalAverageLoadFactor 21167;
BA_ "SPN" SG_ 2365212158 GeneratorTripKvarHoursImport 21154;
BA_ "SPN" SG_ 2566539006 SrtSstmTmTDslMhnOprtn 21148;
BA_ "SPN" SG_ 2566539006 SrtSstmTmTLmtMhnOprtn 21149;
BA_ "SPN" SG_ 2566539006 SrtSstmMhnOprtnDslRsn 21150;
BA_ "SPN" SG_ 2566539006 SrtSstmMhnOprtnLmtRsn 21151;
BA_ "SPN" SG_ 2566539006 SrtSstmMhnOprtnStts 21147;
BA_ "SPN" SG_ 2566539262 FuelActuator1ServiceModeRequest 21141;
BA_ "SPN" SG_ 2566539262 FuelActuator2ServiceModeRequest 21142;
BA_ "SPN" SG_ 2566539518 SteeringWheelControlNextSwitch 21131;
BA_ "SPN" SG_ 2566539518 StrngWhlCntrlPrvsSwth 21132;
BA_ "SPN" SG_ 2566539518 StrngWhlCntrlVlmUpSwth 21133;
BA_ "SPN" SG_ 2566539518 StrngWhlCntrlVlmDwnSwth 21134;
BA_ "SPN" SG_ 2566539518 StrngWhlCntrlCllEndSwth 21135;
BA_ "SPN" SG_ 2566539518 StrngWhlCntrlVCmmntnSwth 21136;
BA_ "SPN" SG_ 2566539518 StrngWhlCntrlPshTTlkSwth 21137;
BA_ "SPN" SG_ 2566539774 FrontParkAssistStatus 21129;
BA_ "SPN" SG_ 2566539774 RearParkAssistStatus 21130;
BA_ "SPN" SG_ 2364753406 LmtdFrqnSnstvMdRlPwrStpnt 21264;
BA_ "SPN" SG_ 2364753406 FrqnSnstvMdRlPwrStpnt 21266;
BA_ "SPN" SG_ 2364753406 GnrtrFrqnOffstStpnt 21267;
BA_ "SPN" SG_ 2364753406 LmtdFrqnSnstvMdStts 21263;
BA_ "SPN" SG_ 2364753406 FrequencySensitiveModeStatus 21265;
BA_ "SPN" SG_ 2364753406 LmtdFrqnSnstvMdOvrfrqnEnlStts 22274;
BA_ "SPN" SG_ 2364753406 FrqnSnstvMdEnlStts 22277;
BA_ "SPN" SG_ 2364753406 LtdFqSstvMdOvqESttsDtvtTsd 22276;
BA_ "SPN" SG_ 2364753406 LmtdFrqnSnstvMdUndrfrqnEnlStts 22275;
BA_ "SPN" SG_ 2364753662 UtltOprtrRlPwrExprtLmtPrntg 21270;
BA_ "SPN" SG_ 2364753662 UtltPrlllVltgRlPwrCrvStpntPrntg 21271;
BA_ "SPN" SG_ 2364753662 UtltOprtrRlPwrExprtLmtStts 21268;
BA_ "SPN" SG_ 2364753662 UtltPrlllVltgRlPwrCrvStts 21269;
BA_ "SPN" SG_ 2364753662 UttOptRPwExptLtStpt1Stts 22278;
BA_ "SPN" SG_ 2364753662 UttOptRPwExptLtStpt2Stts 22279;
BA_ "SPN" SG_ 2364753662 UttOptRPwExptLtStpt3Stts 22280;
BA_ "SPN" SG_ 2364753662 UttOptRPwExptLtStpt4Stts 22281;
BA_ "SPN" SG_ 2364753662 RlPwrRmpRtLmtEnlStts 22282;
BA_ "SPN" SG_ 2364753662 RealPowerRampRateLimitStatus 22283;
BA_ "SPN" SG_ 2364753918 RealPowerActiveSetpointSource 21272;
BA_ "SPN" SG_ 2364753918 RealPowerRampRateSource 21273;
BA_ "SPN" SG_ 2364753918 RealPowerSetpointPercentage 21274;
BA_ "SPN" SG_ 2364753918 RlPwrInrsRmpRtStpnt 21275;
BA_ "SPN" SG_ 2364753918 RlPwrDrsRmpRtStpnt 21276;
BA_ "SPN" SG_ 2364753918 PrmrRlPwrAtvStpntOffstSr 22284;
BA_ "SPN" SG_ 2364753918 PrmrRlPwrOffstRmpRtSr 22285;
BA_ "SPN" SG_ 2364753918 RlPwrRmtInptCmpnstnStts 23908;
BA_ "SPN" SG_ 2364754174 RtvPwrAtvStpntSr 21277;
BA_ "SPN" SG_ 2364754174 ReactivePowerActiveLimitSource 21279;
BA_ "SPN" SG_ 2364754174 ReactivePowerSetpoint 21278;
BA_ "SPN" SG_ 2364754174 UtilitySynchronizationStatus 21280;
BA_ "SPN" SG_ 2364754174 UtltOprtrRtvPwrStpntSr 22732;
BA_ "SPN" SG_ 2364754174 RtvPwrMdSltnDgtlInpt1Stts 22733;
BA_ "SPN" SG_ 2364754174 RtvPwrMdSltnDgtlInpt2Stts 22734;
BA_ "SPN" SG_ 2364754174 RtvPwrMdSltnDgtlInpt3Stts 22735;
BA_ "SPN" SG_ 2364754174 RtvPwrMdSltnDgtlInpt4Stts 22736;
BA_ "SPN" SG_ 2364754174 RtvPwrCntrlAtLwLdStts 22737;
BA_ "SPN" SG_ 2364754174 UtilitySynchronizationDelayTime 21281;
BA_ "SPN" SG_ 2364754174 RtvPwrRmtInptCmpnstnStts 23907;
BA_ "SPN" SG_ 2566081022 FlCllEnlsr1HdrgnCnntrtn 21336;
BA_ "SPN" SG_ 2566081022 FlCllEnlsr2HdrgnCnntrtn 21337;
BA_ "SPN" SG_ 2566081022 FlCllCmprtmntHdrgnCnntrtn 21338;
BA_ "SPN" SG_ 2365210878 EltrnTrnsmssnCntrl15Cr 21255;
BA_ "SPN" SG_ 2365210878 EltrnTrnsmssnCntrl15Cntr 21256;
BA_ "SPN" SG_ 2365210878 TrnsmssnAtNtrlAtRtrnRqstFdk 21253;
BA_ "SPN" SG_ 2365210878 TrnsmssnAtNtrlAtRtrnFntnStt 21254;
BA_ "SPN" SG_ 2365210878 LaunchProcessStatus 24295;
BA_ "SPN" SG_ 2566537726 SourceAddressOfAdsController1 21239;
BA_ "SPN" SG_ 2566537726 ReceivePortOfAdsController1 21240;
BA_ "SPN" SG_ 2566537726 ReceivePortOfAdsController2 21241;
BA_ "SPN" SG_ 2566537726 SourceAddressOfAdsController2 21242;
BA_ "SPN" SG_ 2566537726 SourceAddressOfAdsController3 21243;
BA_ "SPN" SG_ 2566537726 ReceivePortOfAdsController3 21244;
BA_ "SPN" SG_ 2566537726 ReceivePortOfAdsController4 21245;
BA_ "SPN" SG_ 2566537726 SourceAddressOfAdsController4 21246;
BA_ "SPN" SG_ 2499429374 HrdOrEvSstmTtlRgnrtvBrkngLvl 21224;
BA_ "SPN" SG_ 2566686206 FlCllAxlrHtrMdRqst 21314;
BA_ "SPN" SG_ 2566686206 FlCllAxlrHtrOtptClntTmprtrStpnt 21316;
BA_ "SPN" SG_ 2566686206 FlCllAxlrHtrOtptPwrPrntCmmnd 21315;
BA_ "SPN" SG_ 2566686462 FuelCellAuxiliaryHeaterMode 21317;
BA_ "SPN" SG_ 2566686462 FlCllAxlrHtrOtptPwrPrnt 21318;
BA_ "SPN" SG_ 2566686462 FlCllAxlrHtrOtptClntTmprtr 21319;
BA_ "SPN" SG_ 2566686462 FlCllAxlrHtrInptCrrntLvl 21320;
BA_ "SPN" SG_ 2566686462 FlCllAxlrHtrInptVltgLvl 21321;
BA_ "SPN" SG_ 2566686718 FlCllClntPmp1SpdCmmnd 21322;
BA_ "SPN" SG_ 2566686718 FlCllClntPmp1PrntSpdCmmnd 21323;
BA_ "SPN" SG_ 2566686718 FlCllClntPmp1EnlCmmnd 21324;
BA_ "SPN" SG_ 2566686974 FlCllClntPmp2SpdCmmnd 21325;
BA_ "SPN" SG_ 2566686974 FlCllClntPmp2PrntSpdCmmnd 21326;
BA_ "SPN" SG_ 2566686974 FlCllClntPmp2EnlCmmnd 21327;
BA_ "SPN" SG_ 2566687230 FuelCellCoolantPump1Speed 21328;
BA_ "SPN" SG_ 2566687230 FlCllClntPmp1InptVltg 21329;
BA_ "SPN" SG_ 2566687230 FlCllClntPmp1InptCrrnt 21330;
BA_ "SPN" SG_ 2566687230 FlCllClntPmp1EnlStts 21331;
BA_ "SPN" SG_ 2566687486 FuelCellCoolantPump2Speed 21333;
BA_ "SPN" SG_ 2566687486 FlCllClntPmp2InptVltg 21334;
BA_ "SPN" SG_ 2566687486 FlCllClntPmp2InptCrrnt 21335;
BA_ "SPN" SG_ 2566687486 FlCllClntPmp2EnlStts 21332;
BA_ "SPN" SG_ 2364754686 GnrtrRlLdCntrlBsLdStpnt 22286;
BA_ "SPN" SG_ 2364754686 ThrdPrtOprtrRlPwrStpnt 22287;
BA_ "SPN" SG_ 2364754686 UtltOprtrRlPwrPrntgStpnt 22288;
BA_ "SPN" SG_ 2364754686 ThrdPrtOprtrRlPwrStts 22289;
BA_ "SPN" SG_ 2364754686 UtilityOperatorRealPowerStatus 22290;
BA_ "SPN" SG_ 2364754686 ThrdPrtOprtrRlPwrEnlStts 22291;
BA_ "SPN" SG_ 2364754686 UtltOprtrRlPwrEnlStts 22292;
BA_ "SPN" SG_ 2364754942 DsrdSndrFrqnCntrlRlPwrOffst 22293;
BA_ "SPN" SG_ 2364754942 IntgrlLlFrqnCntrlRlPwrOffst 22294;
BA_ "SPN" SG_ 2364754942 SecondaryFrequencyControlStatus 22295;
BA_ "SPN" SG_ 2364754942 IntgrlLlFrqnCntrlStts 22296;
BA_ "SPN" SG_ 2364754942 ItLFqCtOSdFqCtStts 22297;
BA_ "SPN" SG_ 2364754942 IntgrlLlFrqnCntrlRstStts 22298;
BA_ "SPN" SG_ 2364754942 RealPowerReversionStatus 22299;
BA_ "SPN" SG_ 2364754942 RlPwrAndRtvPwrRvrsnStts 22300;
BA_ "SPN" SG_ 2364754942 SndrRlPwrAtvStpntOffstSr 22301;
BA_ "SPN" SG_ 2364754942 SndrRlPwrOffstRmpRtSr 22302;
BA_ "SPN" SG_ 2364754942 ReactivePowerReversionStatus 23865;
BA_ "SPN" SG_ 2364755198 Hvsp1AvllDshrgPwrExtnddRng 22358;
BA_ "SPN" SG_ 2364755198 Hvsp1AvllChrgPwrExtnddRng 22359;
BA_ "SPN" SG_ 2364755198 Hvesp1VoltageLevelExtendedRange 22360;
BA_ "SPN" SG_ 2364755198 Hvesp1CurrentExtendedRange 22361;
BA_ "SPN" SG_ 2364755454 Hvsp1MxIsttsDsCtLtExtddR 22362;
BA_ "SPN" SG_ 2364755454 Hvsp1MxIsttsCCtLtExtddR 22363;
BA_ "SPN" SG_ 2364755454 Hvsp1NmnlDshrgCrrntLmt 22825;
BA_ "SPN" SG_ 2364755454 Hvesp1NominalChargeCurrentLimit 22826;
BA_ "SPN" SG_ 2364755710 Hvsp2AvllDshrgPwrExtnddRng 22380;
BA_ "SPN" SG_ 2364755710 Hvsp2AvllChrgPwrExtnddRng 22381;
BA_ "SPN" SG_ 2364755710 Hvesp2VoltageLevelExtendedRange 22382;
BA_ "SPN" SG_ 2364755710 Hvesp2CurrentExtendedRange 22383;
BA_ "SPN" SG_ 2364755966 Hvsp2MxIsttsDsCtLtExtddR 22384;
BA_ "SPN" SG_ 2364755966 Hvsp2MxIsttsCCtLtExtddR 22385;
BA_ "SPN" SG_ 2364755966 Hvsp2NmnlDshrgCrrntLmt 22827;
BA_ "SPN" SG_ 2364755966 Hvesp2NominalChargeCurrentLimit 22828;
BA_ "SPN" SG_ 2364756222 Hvsp3AvllDshrgPwrExtnddRng 22402;
BA_ "SPN" SG_ 2364756222 Hvsp3AvllChrgPwrExtnddRng 22403;
BA_ "SPN" SG_ 2364756222 Hvesp3VoltageLevelExtendedRange 22404;
BA_ "SPN" SG_ 2364756222 Hvesp3CurrentExtendedRange 22405;
BA_ "SPN" SG_ 2364756478 Hvsp3MxIsttsDsCtLtExtddR 22406;
BA_ "SPN" SG_ 2364756478 Hvsp3MxIsttsCCtLtExtddR 22407;
BA_ "SPN" SG_ 2364756478 Hvsp3NmnlDshrgCrrntLmt 22829;
BA_ "SPN" SG_ 2364756478 Hvesp3NominalChargeCurrentLimit 22830;
BA_ "SPN" SG_ 2364756734 Hvsp4AvllDshrgPwrExtnddRng 22424;
BA_ "SPN" SG_ 2364756734 Hvsp4AvllChrgPwrExtnddRng 22425;
BA_ "SPN" SG_ 2364756734 Hvesp4VoltageLevelExtendedRange 22426;
BA_ "SPN" SG_ 2364756734 Hvesp4CurrentExtendedRange 22427;
